VERSION ""

NS_ :

BS_:

BU_: SGW RFHM MPAD IPC GNMM EVCU2 ESL ECM DTCM DMSM BSM BCM AGSM ADCAM

BO_ 2654339197 PDC_INFO_FD_IDCM: 32 EVCU2
 SG_ EOL_FD11_IDCM : 7|1@0+ (1,0) [0|1] "-"  SGW
 SG_ WakeupSource_FD11_IDCM : 95|8@0+ (1,0) [0|255] "" SGW
 SG_ StayActiveSource_FD11_IDCM : 111|64@0+ (1,0) [0|0] "" SGW
 SG_ PreviousCanNMState_FD11_IDCM : 103|4@0+ (1,0) [0|15] "" SGW
 SG_ GenericFailSts_FD11_IDCM : 180|1@0+ (1,0) [0|1] "" SGW
 SG_ DES_FD11_IDCM : 183|2@0+ (1,0) [0|3] "" SGW
 SG_ CurrentFailSts_FD11_IDCM : 181|1@0+ (1,0) [0|1] "" SGW
 SG_ CurrentCanNMState_FD11_IDCM : 99|4@0+ (1,0) [0|15] "" SGW
 SG_ WakeupSource_FD05_IDCM : 23|8@0+ (1,0) [0|255] "" SGW
 SG_ StayActiveSource_FD05_IDCM : 31|64@0+ (1,0) [0|0] "" SGW
 SG_ PreviousCanNMState_FD05_IDCM : 11|4@0+ (1,0) [0|15] "" SGW
 SG_ GenericFailSts_FD05_IDCM : 5|1@0+ (1,0) [0|1] "" SGW,BCM
 SG_ EOL_FD05_IDCM : 2|1@0+ (1,0) [0|1] "-"  SGW,BCM
 SG_ DES_FD05_IDCM : 4|2@0+ (1,0) [0|3] "" SGW
 SG_ CurrentFailSts_FD05_IDCM : 6|1@0+ (1,0) [0|1] "" SGW,BCM
 SG_ CurrentCanNMState_FD05_IDCM : 15|4@0+ (1,0) [0|15] "" SGW

BO_ 1585 TBM_FD_2: 32 SGW
 SG_ WiFi_Client_Mode_Confirm : 13|2@0+ (1,0) [0|3] "-"  MPAD

BO_ 2654339137 PDC_INFO_FD_RFHM: 32 RFHM
 SG_ GenericFailSts_FD03_RFHM : 5|1@0+ (1,0) [0|1] "" SGW,BCM
 SG_ EOL_FD03_RFHM : 7|1@0+ (1,0) [0|1] "-"  SGW,BCM
 SG_ CurrentFailSts_FD03_RFHM : 6|1@0+ (1,0) [0|1] "" SGW,BCM
 SG_ WakeupSource_FD03_RFHM : 23|8@0+ (1,0) [0|255] "" SGW
 SG_ PreviousCanNMState_FD03_RFHM : 11|4@0+ (1,0) [0|15] "" SGW
 SG_ DES_FD03_RFHM : 4|2@0+ (1,0) [0|3] "" SGW
 SG_ CurrentCanNMState_FD03_RFHM : 15|4@0+ (1,0) [0|15] "" SGW
 SG_ WakeupSource_FD09_RFHM : 111|8@0+ (1,0) [0|255] "" SGW
 SG_ PreviousCanNMState_FD09_RFHM : 99|4@0+ (1,0) [0|15] "" SGW
 SG_ GenericFailSts_FD09_RFHM : 93|1@0+ (1,0) [0|1] "" SGW
 SG_ EOL_FD09_RFHM : 95|1@0+ (1,0) [0|1] "-"  SGW
 SG_ DES_FD09_RFHM : 92|2@0+ (1,0) [0|3] "" SGW
 SG_ CurrentFailSts_FD09_RFHM : 94|1@0+ (1,0) [0|1] "" SGW
 SG_ CurrentCanNMState_FD09_RFHM : 103|4@0+ (1,0) [0|15] "" SGW
 SG_ StayActiveSource_FD09_RFHM : 119|64@0+ (1,0) [0|18446744073709551615] "" SGW
 SG_ StayActiveSource_FD03_RFHM : 31|64@0+ (1,0) [0|18446744073709551615] "" SGW

BO_ 2564487440 DIAGNOSTIC_RESPONSE_FOTA_ECM_KWP: 8 ECM
 SG_ N_PDU : 7|64@0+ (1,0) [0|0] "" SGW

BO_ 2564554489 DIAGNOSTIC_REQUEST_FUNC_FOTA_KWP: 8 SGW
 SG_ N_PDU : 7|64@0+ (1,0) [0|0] "" Vector__XXX

BO_ 2564428025 DIAGNOSTIC_REQUEST_FOTA_ECM_KWP: 8 SGW
 SG_ N_PDU : 7|64@0+ (1,0) [0|0] "" Vector__XXX

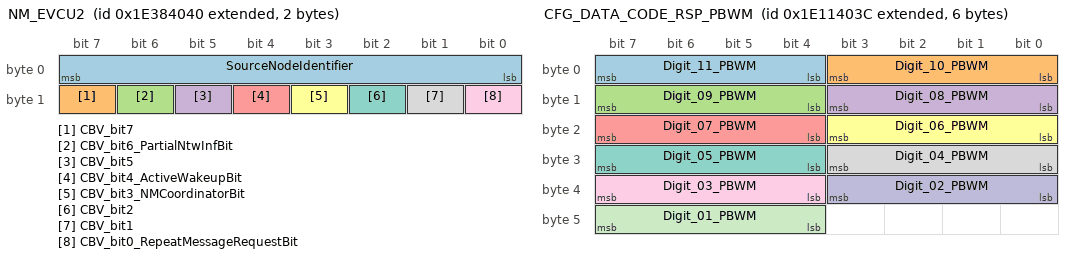
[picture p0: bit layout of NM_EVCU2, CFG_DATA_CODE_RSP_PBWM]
BO_ 2654486592 NM_EVCU2: 2 EVCU2
 SG_ SourceNodeIdentifier : 7|8@0+ (1,0) [0|255] "-"  ADCAM,MPAD,GNMM,SGW,AGSM,ESL,BCM,BSM,IPC,RFHM,ECM,DTCM
 SG_ CBV_bit7 : 15|1@0+ (1,0) [0|1] "" ADCAM,MPAD,GNMM,SGW,AGSM,ESL,BCM,BSM,IPC,RFHM,ECM,DTCM
 SG_ CBV_bit6_PartialNtwInfBit : 14|1@0+ (1,0) [0|1] "" ADCAM,MPAD,GNMM,SGW,AGSM,ESL,BCM,BSM,IPC,RFHM,ECM,DTCM
 SG_ CBV_bit5 : 13|1@0+ (1,0) [0|1] "" ADCAM,MPAD,GNMM,SGW,AGSM,ESL,BCM,BSM,IPC,RFHM,ECM,DTCM
 SG_ CBV_bit4_ActiveWakeupBit : 12|1@0+ (1,0) [0|1] "" ADCAM,MPAD,GNMM,SGW,AGSM,ESL,BCM,BSM,IPC,RFHM,ECM,DTCM
 SG_ CBV_bit3_NMCoordinatorBit : 11|1@0+ (1,0) [0|1] "" ADCAM,MPAD,GNMM,SGW,AGSM,ESL,BCM,BSM,IPC,RFHM,ECM,DTCM
 SG_ CBV_bit2 : 10|1@0+ (1,0) [0|1] "" ADCAM,MPAD,GNMM,SGW,AGSM,ESL,BCM,BSM,IPC,RFHM,ECM,DTCM
 SG_ CBV_bit1 : 9|1@0+ (1,0) [0|1] "" ADCAM,MPAD,GNMM,SGW,AGSM,ESL,BCM,BSM,IPC,RFHM,ECM,DTCM
 SG_ CBV_bit0_RepeatMessageRequestBit : 8|1@0+ (1,0) [0|1] "" ADCAM,MPAD,GNMM,SGW,AGSM,ESL,BCM,BSM,IPC,RFHM,ECM,DTCM

BO_ 1044 HYBRID_DISPLAY2: 64 EVCU2
 SG_ RI_TOTAL_Range_Add : 63|11@0+ (0.1,0) [0|204.70] "km"  SGW
 SG_ RI_SEATSWHL_Range : 20|9@0+ (0.1,0) [0|51.1] "km"  SGW
 SG_ RI_OTHER_Range : 40|9@0+ (0.1,0) [0|51.1] "km"  SGW
 SG_ RI_LIGHTS_Range : 33|9@0+ (0.1,0) [0|51.1] "km"  SGW
 SG_ RI_DEFROST_Range : 13|9@0+ (0.1,0) [0|51.1] "km"  SGW
 SG_ RI_AUDIO_Range : 27|10@0+ (0.1,0) [0|102.3] "km"  SGW
 SG_ RI_AC_FAN_Range : 7|10@0+ (0.1,0) [0|102.30] "km"  SGW
 SG_ PnC_Reattepmt_Failure : 68|1@0+ (1,0) [0|1] "" IPC
 SG_ PnC_Failure : 67|1@0+ (1,0) [0|1] "" SGW,IPC
 SG_ TransTemp_Display : 181|6@0+ (3,-40) [-40|149] "deg C"  SGW,IPC
 SG_ HVBatteryMILRq : 104|1@0+ (1,0) [0|1] "" IPC
 SG_ APCM_Rq_Display : 183|2@0+ (1,0) [0|3] "" SGW

BO_ 616 ADAS_FD_HMI_VIP: 32 ADCAM
 SG_ Set_Speed_MPH_VIP : 15|8@0+ (1,0) [0|255] "mph"  Vector__XXX
 SG_ Set_Speed_KPH_VIP : 7|8@0+ (1,0) [0|255] "kph"  Vector__XXX
 SG_ RRCC_LEDSts_VIP : 25|2@0+ (1,0) [0|3] "No_Unit"  MPAD
 SG_ MessageCounter_ADAS_FD_HMI_VIP : 179|4@0+ (1,0) [0|15] "No_Unit"  MPAD
 SG_ CRC_ADAS_FD_HMI_VIP : 191|8@0+ (1,0) [0|255] "No_Unit"  MPAD

BO_ 1488 TBM_COOP_CHARGING: 64 SGW
 SG_ TBM_StopCharge : 7|1@0+ (1,0) [0|1] "" EVCU2
 SG_ TBM_Cooperative_Charge_Command : 3|2@0+ (1,0) [0|3] "" EVCU2
 SG_ Remote_Chargeport_Command : 6|2@0+ (1,0) [0|3] "" EVCU2
 SG_ Cooperative_Vehicle_Location : 4|1@0+ (1,0) [0|1] "" EVCU2

BO_ 1487 HCP_CHARGING_STAT: 64 EVCU2
 SG_ Total_Battery_Capacity : 5|12@0+ (0.1,0) [0|409.5] "kWh"  SGW
 SG_ Lv2_EstChargeTime_80 : 79|13@0+ (1,0) [0|8191] "Min"  SGW
 SG_ Lv1_EstChargeTime_80 : 63|13@0+ (1,0) [0|8191] "Min"  SGW
 SG_ EVSE_Power : 37|9@0+ (0.1,0) [0|51.1] "kW"  SGW
 SG_ EV_Charge_Current : 44|11@0+ (0.1,0) [0|204.70] "Amp"  SGW
 SG_ Est_Range_FullCharge : 16|11@0+ (1,0) [0|2047] "km"  SGW
 SG_ Energy_to_Battery : 9|9@0+ (0.1,0) [0|51.1] "kW"  SGW
 SG_ Cooperative_Status : 66|3@0+ (1,0) [0|7] "" SGW
 SG_ Chargeport_Lock_Status : 7|2@0+ (1,0) [0|3] "" SGW

BO_ 2654339132 PDC_INFO_FD_PBWM: 32 EVCU2
 SG_ WakeupSource_FD11_PBWM : 23|8@0+ (1,0) [0|255] "" Vector__XXX
 SG_ WakeupSource_FD05_PBWM : 175|8@0+ (1,0) [0|255] "" Vector__XXX
 SG_ StayActiveSource_FD11_PBWM : 31|64@0+ (1,0) [0|0] "" Vector__XXX
 SG_ StayActiveSource_FD05_PBWM : 99|64@0+ (1,0) [0|0] "" Vector__XXX
 SG_ PreviousCanNMState_FD11_PBWM : 11|4@0+ (1,0) [0|15] "" Vector__XXX
 SG_ PreviousCanNMState_FD05_PBWM : 103|4@0+ (1,0) [0|15] "" Vector__XXX
 SG_ GenericFailSts_FD11_PBWM : 5|1@0+ (1,0) [0|1] "" BCM
 SG_ GenericFailSts_FD05_PBWM : 89|1@0+ (1,0) [0|1] "" Vector__XXX
 SG_ EOL_FD11_PBWM : 7|1@0+ (1,0) [0|1] "-"  BCM
 SG_ EOL_FD05_PBWM : 1|1@0+ (1,0) [0|1] "-"  Vector__XXX
 SG_ DES_FD11_PBWM : 4|2@0+ (1,0) [0|3] "" Vector__XXX
 SG_ DES_FD05_PBWM : 91|2@0+ (1,0) [0|3] "" Vector__XXX
 SG_ CurrentFailSts_FD11_PBWM : 2|1@0+ (1,0) [0|1] "" BCM
 SG_ CurrentFailSts_FD05_PBWM : 6|1@0+ (1,0) [0|1] "" Vector__XXX
 SG_ CurrentCanNMState_FD11_PBWM : 15|4@0+ (1,0) [0|15] "" Vector__XXX
 SG_ CurrentCanNMState_FD05_PBWM : 95|4@0+ (1,0) [0|15] "" Vector__XXX

BO_ 2654339138 PDC_INFO_FD_DMPI: 32 EVCU2
 SG_ WakeupSource_FD11_DMPI : 23|8@0+ (1,0) [0|255] "" Vector__XXX
 SG_ WakeupSource_FD05_DMPI : 175|8@0+ (1,0) [0|255] "" Vector__XXX
 SG_ StayActiveSource_FD11_DMPI : 31|64@0+ (1,0) [0|0] "" Vector__XXX
 SG_ StayActiveSource_FD05_DMPI : 99|64@0+ (1,0) [0|0] "" Vector__XXX
 SG_ PreviousCanNMState_FD11_DMPI : 11|4@0+ (1,0) [0|15] "" Vector__XXX
 SG_ PreviousCanNMState_FD05_DMPI : 103|4@0+ (1,0) [0|15] "" Vector__XXX
 SG_ GenericFailSts_FD11_DMPI : 5|1@0+ (1,0) [0|1] "" BCM
 SG_ GenericFailSts_FD05_DMPI : 89|1@0+ (1,0) [0|1] "" Vector__XXX
 SG_ EOL_FD11_DMPI : 7|1@0+ (1,0) [0|1] "-"  BCM
 SG_ EOL_FD05_DMPI : 1|1@0+ (1,0) [0|1] "-"  Vector__XXX
 SG_ DES_FD11_DMPI : 4|2@0+ (1,0) [0|3] "" Vector__XXX
 SG_ DES_FD05_DMPI : 91|2@0+ (1,0) [0|3] "" Vector__XXX
 SG_ CurrentFailSts_FD11_DMPI : 2|1@0+ (1,0) [0|1] "" BCM
 SG_ CurrentFailSts_FD05_DMPI : 6|1@0+ (1,0) [0|1] "" Vector__XXX
 SG_ CurrentCanNMState_FD11_DMPI : 15|4@0+ (1,0) [0|15] "" Vector__XXX
 SG_ CurrentCanNMState_FD05_DMPI : 95|4@0+ (1,0) [0|15] "" Vector__XXX

BO_ 2564486631 DIAGNOSTIC_RESPONSE_FOTA_MPFC: 64 MPAD
 SG_ N_PDU : 7|64@0+ (1,0) [0|0] "" SGW

BO_ 2564483061 DIAGNOSTIC_REQUEST_FOTA_MPFC: 64 SGW
 SG_ N_PDU : 7|64@0+ (1,0) [0|0] "-"  MPAD

BO_ 2651930684 CFG_DATA_CODE_RSP_PBWM: 6 EVCU2
 SG_ Digit_11_PBWM : 7|4@0+ (1,0) [0|15] "-"  BCM
 SG_ Digit_10_PBWM : 3|4@0+ (1,0) [0|15] "-"  BCM
 SG_ Digit_09_PBWM : 15|4@0+ (1,0) [0|15] "-"  BCM
 SG_ Digit_08_PBWM : 11|4@0+ (1,0) [0|15] "-"  BCM
 SG_ Digit_07_PBWM : 23|4@0+ (1,0) [0|15] "-"  BCM
 SG_ Digit_06_PBWM : 19|4@0+ (1,0) [0|15] "-"  BCM
 SG_ Digit_05_PBWM : 31|4@0+ (1,0) [0|15] "-"  BCM
 SG_ Digit_04_PBWM : 27|4@0+ (1,0) [0|15] "-"  BCM
 SG_ Digit_03_PBWM : 39|4@0+ (1,0) [0|15] "-"  BCM
 SG_ Digit_02_PBWM : 35|4@0+ (1,0) [0|15] "-"  BCM
 SG_ Digit_01_PBWM : 47|4@0+ (1,0) [0|15] "-"  BCM

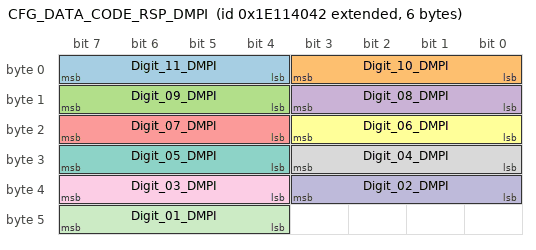
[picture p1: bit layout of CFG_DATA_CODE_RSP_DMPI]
BO_ 2651930690 CFG_DATA_CODE_RSP_DMPI: 6 EVCU2
 SG_ Digit_11_DMPI : 7|4@0+ (1,0) [0|15] "-"  BCM
 SG_ Digit_10_DMPI : 3|4@0+ (1,0) [0|15] "-"  BCM
 SG_ Digit_09_DMPI : 15|4@0+ (1,0) [0|15] "-"  BCM
 SG_ Digit_08_DMPI : 11|4@0+ (1,0) [0|15] "-"  BCM
 SG_ Digit_07_DMPI : 23|4@0+ (1,0) [0|15] "-"  BCM
 SG_ Digit_06_DMPI : 19|4@0+ (1,0) [0|15] "-"  BCM
 SG_ Digit_05_DMPI : 31|4@0+ (1,0) [0|15] "-"  BCM
 SG_ Digit_04_DMPI : 27|4@0+ (1,0) [0|15] "-"  BCM
 SG_ Digit_03_DMPI : 39|4@0+ (1,0) [0|15] "-"  BCM
 SG_ Digit_02_DMPI : 35|4@0+ (1,0) [0|15] "-"  BCM
 SG_ Digit_01_DMPI : 47|4@0+ (1,0) [0|15] "-"  BCM

BO_ 2564682304 DIAGNOSTIC_ROE_FD_BCM: 64 BCM
 SG_ N_PDU : 7|64@0+ (1,0) [0|0] "" SGW

BO_ 2564682048 DIAGNOSTIC_ROE_BCM: 8 BCM
 SG_ N_PDU : 7|64@0+ (1,0) [0|0] "" SGW

BO_ 577 SYNCHRO_DC_GLOBAL: 32 ECM
 SG_ QualifyDriveCycle : 7|1@0+ (1,0) [0|1] "" EVCU2

BO_ 1914 FOTA_RSP_MPFC: 32 MPAD
 SG_ Download_Status_MPFC : 12|2@0+ (1,0) [0|3] "" SGW
 SG_ Big_ECU_Ready_MPFC : 14|2@0+ (1,0) [0|3] "" SGW
 SG_ Update_Status_MPFC : 5|2@0+ (1,0) [0|3] "" SGW

CM_ SG_ 2654339197 CurrentFailSts_FD05_IDCM "Indicates the presence/absence of at least one DTC with DTCStatus = present in the System Memory";
CM_ SG_ 2654339197 CurrentCanNMState_FD11_IDCM "Indicates that CanNM state the ECU is currently executing";
CM_ SG_ 2654339197 CurrentCanNMState_FD05_IDCM "Indicates that CanNM state the ECU is currently executing";
CM_ SG_ 2654339197 DES_FD05_IDCM "Indicates whether the ECU?s CAN cell is in either ErrorActive, or ErrorPassive state OR has just now recovered from a BusOff condition";
CM_ SG_ 2654339197 DES_FD11_IDCM "Indicates whether the ECU?s CAN cell is in either ErrorActive, or ErrorPassive state OR has just now recovered from a BusOff condition";
CM_ SG_ 2654339197 EOL_FD05_IDCM "Indicates if the ECU requires configuration data at the assembly plant End Of Line";
CM_ SG_ 2654339197 EOL_FD11_IDCM "Indicates if the ECU requires configuration data at the assembly plant End Of Line";
CM_ SG_ 2654339197 GenericFailSts_FD05_IDCM "Indicates the presence/absent of at least one DTC in the System Memory";
CM_ SG_ 2654339197 GenericFailSts_FD11_IDCM "Indicates the presence/absent of at least one DTC in the System Memory";
CM_ SG_ 2654339197 PreviousCanNMState_FD05_IDCM "Indicates the last CanNM state that the ECU existed in";
CM_ SG_ 2654339197 PreviousCanNMState_FD11_IDCM "Indicates the last CanNM state that the ECU existed in";
CM_ SG_ 2654339197 StayActiveSource_FD05_IDCM "Indicates the source that requests the ECU to stay active";
CM_ SG_ 2654339197 StayActiveSource_FD11_IDCM "Indicates the source that requests the ECU to stay active";
CM_ SG_ 2654339197 WakeupSource_FD05_IDCM "Indicates the reason the ECU was most recently awakened";
CM_ SG_ 2654339197 WakeupSource_FD11_IDCM "Indicates the reason the ECU was most recently awakened";
CM_ SG_ 2654339197 CurrentFailSts_FD11_IDCM "Indicates the presence/absence of at least one DTC with DTCStatus = present in the System Memory";
CM_ SG_ 1585 WiFi_Client_Mode_Confirm "WiFI Client Mode Confirmation";
CM_ SG_ 2654339137 DES_FD09_RFHM "Indicates whether the ECU?s CAN cell is in either ErrorActive, or ErrorPassive state OR has just now recovered from a BusOff condition";
CM_ SG_ 2654339137 CurrentCanNMState_FD03_RFHM "Indicates that CanNM state the ECU is currently executing";
CM_ SG_ 2654339137 CurrentCanNMState_FD09_RFHM "Indicates that CanNM state the ECU is currently executing";
CM_ SG_ 2654339137 CurrentFailSts_FD03_RFHM "Indicates the presence/absence of at least one DTC with DTCStatus = present in the System Memory";
CM_ SG_ 2654339137 CurrentFailSts_FD09_RFHM "Indicates the presence/absence of at least one DTC with DTCStatus = present in the System Memory";
CM_ SG_ 2654339137 DES_FD03_RFHM "Indicates whether the ECU?s CAN cell is in either ErrorActive, or ErrorPassive state OR has just now recovered from a BusOff condition";
CM_ SG_ 2654339137 EOL_FD03_RFHM "Indicates if the ECU requires configuration data at the assembly plant End Of Line";
CM_ SG_ 2654339137 EOL_FD09_RFHM "Indicates if the ECU requires configuration data at the assembly plant End Of Line";
CM_ SG_ 2654339137 GenericFailSts_FD03_RFHM "Indicates the presence/absent of at least one DTC in the System Memory";
CM_ SG_ 2654339137 GenericFailSts_FD09_RFHM "Indicates the presence/absent of at least one DTC in the System Memory";
CM_ SG_ 2654339137 PreviousCanNMState_FD03_RFHM "Indicates the last CanNM state that the ECU existed in";
CM_ SG_ 2654339137 PreviousCanNMState_FD09_RFHM "Indicates the last CanNM state that the ECU existed in";
CM_ SG_ 2654339137 StayActiveSource_FD03_RFHM "Indicates the source that requests the ECU to stay active";
CM_ SG_ 2654339137 StayActiveSource_FD09_RFHM "Indicates the source that requests the ECU to stay active";
CM_ SG_ 2654339137 WakeupSource_FD03_RFHM "Indicates the reason the ECU was most recently awakened";
CM_ SG_ 2654339137 WakeupSource_FD09_RFHM "Indicates the reason the ECU was most recently awakened";
CM_ SG_ 2564487440 N_PDU "This signal is used for diagnostic purposes";
CM_ SG_ 2564554489 N_PDU "This signal is used for diagnostic purposes";
CM_ SG_ 2564428025 N_PDU "This signal is used for diagnostic purposes";
CM_ SG_ 1044 TransTemp_Display "Transmission Temp For Display";
CM_ SG_ 1044 RI_TOTAL_Range_Add "Total Range Impact of Turning All Non-Propulsive Power Consuming Features Off";
CM_ SG_ 1044 RI_SEATSWHL_Range "Range Impact of Turning Seats and Wheel Heating/Venting Off";
CM_ SG_ 1044 RI_OTHER_Range "Range Impact of Turning Other Non-Propulsive Power Consuming Features Off";
CM_ SG_ 1044 RI_LIGHTS_Range "Range Impact of Turning External Lights Off";
CM_ SG_ 1044 RI_DEFROST_Range "Range Impact of Turning Defrost Off";
CM_ SG_ 1044 RI_AUDIO_Range "Range Impact of Turning Audio Off";
CM_ SG_ 1044 RI_AC_FAN_Range "Range Impact of Turning AC Off";
CM_ SG_ 1044 PnC_Reattepmt_Failure "The maximum number of authentication retry attempts has been reached";
CM_ SG_ 1044 PnC_Failure "A Plug and Charge failure has been detected";
CM_ SG_ 1044 HVBatteryMILRq "HV Battery MIL Request";
CM_ SG_ 1044 APCM_Rq_Display "Auto position correction mode request";
CM_ SG_ 616 CRC_ADAS_FD_HMI_VIP "CRC according to SAE J1850 standard at each frame transmission.";
CM_ SG_ 616 MessageCounter_ADAS_FD_HMI_VIP "This signal is a counter used for safety checks strategies. This counter is incremented of 1 (one) unit at each frame transmission.";
CM_ SG_ 616 RRCC_LEDSts_VIP "RRCC_LEDSts";
CM_ SG_ 616 Set_Speed_KPH_VIP "Speed shown by IPC, which ACC is controlling in KPH";
CM_ SG_ 616 Set_Speed_MPH_VIP "Speed shown by IPC, which ACC is controlling in MPH";
CM_ SG_ 1488 Cooperative_Vehicle_Location "Vehicle at Cooperative enabled location.";
CM_ SG_ 1488 Remote_Chargeport_Command "Remote Charge port lock/unlock command";
CM_ SG_ 1488 TBM_Cooperative_Charge_Command "Remote cooperative charging command";
CM_ SG_ 1488 TBM_StopCharge "Remote Stop HV Charging Command";
CM_ SG_ 1487 EV_Charge_Current "HV Charging Current Draw from EVSE";
CM_ SG_ 1487 Est_Range_FullCharge "Estimated Range at 100% SOC";
CM_ SG_ 1487 Total_Battery_Capacity "Total Battery capacity in kWh";
CM_ SG_ 1487 Lv2_EstChargeTime_80 "Estimated time to charge to 80% on Level 2";
CM_ SG_ 1487 Lv1_EstChargeTime_80 "Estimated time to charge to 80% on Level 1";
CM_ SG_ 1487 Chargeport_Lock_Status "Charge Port Lock Status";
CM_ SG_ 1487 Cooperative_Status "Cooperative charging status";
CM_ SG_ 1487 Energy_to_Battery "HV Battery Charging Energy Rate";
CM_ SG_ 1487 EVSE_Power "EVSE Power available";
CM_ SG_ 2654339132 GenericFailSts_FD11_PBWM "Indicates the presence/absent of at least one DTC in the System Memory";
CM_ SG_ 2654339132 CurrentCanNMState_FD05_PBWM "Indicates that CanNM state the ECU is currently executing";
CM_ SG_ 2654339132 CurrentCanNMState_FD11_PBWM "Indicates that CanNM state the ECU is currently executing";
CM_ SG_ 2654339132 CurrentFailSts_FD05_PBWM "Indicates the presence/absence of at least one DTC with DTCStatus = present in the System Memory";
CM_ SG_ 2654339132 CurrentFailSts_FD11_PBWM "Indicates the presence/absence of at least one DTC with DTCStatus = present in the System Memory";
CM_ SG_ 2654339132 DES_FD05_PBWM "Indicates whether the ECU?s CAN cell is in either ErrorActive, or ErrorPassive state OR has just now recovered from a BusOff condition";
CM_ SG_ 2654339132 DES_FD11_PBWM "Indicates whether the ECU?s CAN cell is in either ErrorActive, or ErrorPassive state OR has just now recovered from a BusOff condition";
CM_ SG_ 2654339132 EOL_FD05_PBWM "Indicates if the ECU requires configuration data at the assembly plant End Of Line";
CM_ SG_ 2654339132 EOL_FD11_PBWM "Indicates if the ECU requires configuration data at the assembly plant End Of Line";
CM_ SG_ 2654339132 GenericFailSts_FD05_PBWM "Indicates the presence/absent of at least one DTC in the System Memory";
CM_ SG_ 2654339132 PreviousCanNMState_FD05_PBWM "Indicates the last CanNM state that the ECU existed in";
CM_ SG_ 2654339132 PreviousCanNMState_FD11_PBWM "Indicates the last CanNM state that the ECU existed in";
CM_ SG_ 2654339132 StayActiveSource_FD05_PBWM "Indicates the source that requests the ECU to stay active";
CM_ SG_ 2654339132 StayActiveSource_FD11_PBWM "Indicates the source that requests the ECU to stay active";
CM_ SG_ 2654339132 WakeupSource_FD05_PBWM "Indicates the reason the ECU was most recently awakened";
CM_ SG_ 2654339132 WakeupSource_FD11_PBWM "Indicates the reason the ECU was most recently awakened";
CM_ SG_ 2654339138 CurrentCanNMState_FD05_DMPI "Indicates that CanNM state the ECU is currently executing";
CM_ SG_ 2654339138 CurrentCanNMState_FD11_DMPI "Indicates that CanNM state the ECU is currently executing";
CM_ SG_ 2654339138 CurrentFailSts_FD05_DMPI "Indicates the presence/absence of at least one DTC with DTCStatus = present in the System Memory";
CM_ SG_ 2654339138 CurrentFailSts_FD11_DMPI "Indicates the presence/absence of at least one DTC with DTCStatus = present in the System Memory";
CM_ SG_ 2654339138 DES_FD05_DMPI "Indicates whether the ECU?s CAN cell is in either ErrorActive, or ErrorPassive state OR has just now recovered from a BusOff condition";
CM_ SG_ 2654339138 DES_FD11_DMPI "Indicates whether the ECU?s CAN cell is in either ErrorActive, or ErrorPassive state OR has just now recovered from a BusOff condition";
CM_ SG_ 2654339138 EOL_FD05_DMPI "Indicates if the ECU requires configuration data at the assembly plant End Of Line";
CM_ SG_ 2654339138 EOL_FD11_DMPI "Indicates if the ECU requires configuration data at the assembly plant End Of Line";
CM_ SG_ 2654339138 GenericFailSts_FD05_DMPI "Indicates the presence/absent of at least one DTC in the System Memory";
CM_ SG_ 2654339138 GenericFailSts_FD11_DMPI "Indicates the presence/absent of at least one DTC in the System Memory";
CM_ SG_ 2654339138 PreviousCanNMState_FD05_DMPI "Indicates the last CanNM state that the ECU existed in";
CM_ SG_ 2654339138 PreviousCanNMState_FD11_DMPI "Indicates the last CanNM state that the ECU existed in";
CM_ SG_ 2654339138 StayActiveSource_FD05_DMPI "Indicates the source that requests the ECU to stay active";
CM_ SG_ 2654339138 StayActiveSource_FD11_DMPI "Indicates the source that requests the ECU to stay active";
CM_ SG_ 2654339138 WakeupSource_FD05_DMPI "Indicates the reason the ECU was most recently awakened";
CM_ SG_ 2654339138 WakeupSource_FD11_DMPI "Indicates the reason the ECU was most recently awakened";
CM_ SG_ 2564486631 N_PDU "This signal is used for diagnostic purposes";
CM_ SG_ 2564483061 N_PDU "This signal is used for diagnostic purposes";
CM_ SG_ 2564682304 N_PDU "This signal is used for diagnostic purposes";
CM_ SG_ 2564682048 N_PDU "This signal is used for diagnostic purposes";
CM_ SG_ 577 QualifyDriveCycle "Qualified Drive Cycle";
CM_ SG_ 1914 Big_ECU_Ready_MPFC "MPFC Ready Status";
CM_ SG_ 1914 Download_Status_MPFC "MPFC Download Status";
CM_ SG_ 1914 Update_Status_MPFC "MPFC Update Status";
BA_DEF_ BO_ "CANFD_BRS" ENUM "0","1";
BA_DEF_ BO_ "VFrameFormat" ENUM "StandardCAN","ExtendedCAN","reserved","reserved","reserved","reserved","reserved","reserved","reserved","reserved","reserved","reserved","reserved","reserved","StandardCAN_FD","ExtendedCAN_FD";
BA_DEF_ BO_ "DiagConnection" HEX 0 65535;
BA_DEF_ BO_ "DiagState" ENUM "No","Yes";
BA_DEF_ BO_ "NmAsrMessage" ENUM "No","Yes";
BA_DEF_ BO_ "GenMsgDelayTime" INT 0 65535;
BA_DEF_ BO_ "GenMsgCycleTime" INT 0 65535;
BA_DEF_ BO_ "GenMsgCycleTimeFast" INT 0 65535;
BA_DEF_ BO_ "GenMsgStartDelayTime" INT 0 65535;
BA_DEF_ BO_ "GenMsgILSupport" ENUM "No","Yes";
BA_DEF_ BO_ "GenMsgNrOfRepetition" INT 0 255;
BA_DEF_ BO_ "GenMsgSendType" ENUM "Cyclic","NotUsed","NotUsed","NotUsed","NotUsed","NotUsed","NotUsed","NotUsed","NoMsgSendType";
BA_DEF_ BO_ "NmMessage" ENUM "No","Yes";
BA_DEF_ BO_ "DiagResponse" ENUM "No","Yes";
BA_DEF_ BO_ "Type" ENUM "P","C","PE","COC","PE_Cntrl","E","E_Cntrl","OC","S","BAF","DC","EM","MM","ISO-TP","-";
BA_DEF_ BO_ "DiagRequest" ENUM "No","Yes";
BA_DEF_ SG_ "GenSigTimeoutTime_SGW" INT 0 65535;
BA_DEF_ SG_ "GenSigTimeoutTime_RFHM" INT 0 65535;
BA_DEF_ SG_ "GenSigTimeoutTime_MPAD" INT 0 65535;
BA_DEF_ SG_ "GenSigTimeoutTime_IPC" INT 0 65535;
BA_DEF_ SG_ "GenSigTimeoutTime_GNMM" INT 0 65535;
BA_DEF_ SG_ "GenSigTimeoutTime_EVCU2" INT 0 65535;
BA_DEF_ SG_ "GenSigTimeoutTime_ESL" INT 0 65535;
BA_DEF_ SG_ "GenSigTimeoutTime_ECM" INT 0 65535;
BA_DEF_ SG_ "GenSigTimeoutTime_DTCM" INT 0 65535;
BA_DEF_ SG_ "GenSigTimeoutTime_DMSM" INT 0 65535;
BA_DEF_ SG_ "GenSigTimeoutTime_BSM" INT 0 65535;
BA_DEF_ SG_ "GenSigTimeoutTime_BCM" INT 0 65535;
BA_DEF_ SG_ "GenSigTimeoutTime_AGSM" INT 0 65535;
BA_DEF_ SG_ "GenSigTimeoutTime_ADCAM" INT 0 65535;
BA_DEF_ SG_ "SystemSignalLongSymbol" STRING ;
BA_DEF_ SG_ "GenSigSendType" ENUM "NotUsed","OnWrite","OnWriteWithRepetition","OnChange","OnChangeWithRepetition","IfActive","IfActiveWithRepetition","NoSigSendType";
BA_DEF_ SG_ "GenSigInactiveValue" INT 0 2147483647;
BA_DEF_ SG_ "GenSigStartValue" INT 0 2147483647;
BA_DEF_DEF_ "CANFD_BRS" "0";
BA_DEF_DEF_ "VFrameFormat" "StandardCAN_FD";
BA_DEF_DEF_ "DiagConnection" 0;
BA_DEF_DEF_ "DiagState" "No";
BA_DEF_DEF_ "NmAsrMessage" "No";
BA_DEF_DEF_ "GenMsgDelayTime" 0;
BA_DEF_DEF_ "GenMsgCycleTime" 0;
BA_DEF_DEF_ "GenMsgCycleTimeFast" 0;
BA_DEF_DEF_ "GenMsgStartDelayTime" 0;
BA_DEF_DEF_ "GenMsgILSupport" "No";
BA_DEF_DEF_ "GenMsgNrOfRepetition" 0;
BA_DEF_DEF_ "GenMsgSendType" "NoMsgSendType";
BA_DEF_DEF_ "NmMessage" "No";
BA_DEF_DEF_ "DiagResponse" "No";
BA_DEF_DEF_ "Type" "-";
BA_DEF_DEF_ "DiagRequest" "No";
BA_DEF_DEF_ "GenSigTimeoutTime_SGW" 2500;
BA_DEF_DEF_ "GenSigTimeoutTime_RFHM" 2500;
BA_DEF_DEF_ "GenSigTimeoutTime_MPAD" 2500;
BA_DEF_DEF_ "GenSigTimeoutTime_IPC" 2500;
BA_DEF_DEF_ "GenSigTimeoutTime_GNMM" 2500;
BA_DEF_DEF_ "GenSigTimeoutTime_EVCU2" 2500;
BA_DEF_DEF_ "GenSigTimeoutTime_ESL" 2500;
BA_DEF_DEF_ "GenSigTimeoutTime_ECM" 2500;
BA_DEF_DEF_ "GenSigTimeoutTime_DTCM" 2500;
BA_DEF_DEF_ "GenSigTimeoutTime_DMSM" 2500;
BA_DEF_DEF_ "GenSigTimeoutTime_BSM" 2500;
BA_DEF_DEF_ "GenSigTimeoutTime_BCM" 2500;
BA_DEF_DEF_ "GenSigTimeoutTime_AGSM" 2500;
BA_DEF_DEF_ "GenSigTimeoutTime_ADCAM" 2500;
BA_DEF_DEF_ "SystemSignalLongSymbol" "";
BA_DEF_DEF_ "GenSigSendType" "NoSigSendType";
BA_DEF_DEF_ "GenSigInactiveValue" 0;
BA_DEF_DEF_ "GenSigStartValue" 0;
BA_ "GenMsgCycleTime" BO_ 2654339197 1000;
BA_ "GenMsgILSupport" BO_ 2654339197 1;
BA_ "CANFD_BRS" BO_ 2654339197 1;
BA_ "VFrameFormat" BO_ 2654339197 15;
BA_ "GenMsgSendType" BO_ 2654339197 0;
BA_ "Type" BO_ 2654339197 1;
BA_ "CANFD_BRS" BO_ 1585 1;
BA_ "GenMsgCycleTime" BO_ 1585 500;
BA_ "GenMsgILSupport" BO_ 1585 1;
BA_ "GenMsgSendType" BO_ 1585 0;
BA_ "Type" BO_ 1585 1;
BA_ "CANFD_BRS" BO_ 2654339137 1;
BA_ "VFrameFormat" BO_ 2654339137 15;
BA_ "GenMsgCycleTime" BO_ 2654339137 1000;
BA_ "GenMsgILSupport" BO_ 2654339137 1;
BA_ "GenMsgSendType" BO_ 2654339137 0;
BA_ "Type" BO_ 2654339137 1;
BA_ "VFrameFormat" BO_ 2564487440 1;
BA_ "DiagConnection" BO_ 2564487440 63760;
BA_ "DiagResponse" BO_ 2564487440 1;
BA_ "Type" BO_ 2564487440 8;
BA_ "VFrameFormat" BO_ 2564554489 1;
BA_ "DiagConnection" BO_ 2564554489 63998;
BA_ "DiagState" BO_ 2564554489 1;
BA_ "Type" BO_ 2564554489 8;
BA_ "VFrameFormat" BO_ 2564428025 1;
BA_ "DiagConnection" BO_ 2564428025 63760;
BA_ "Type" BO_ 2564428025 8;
BA_ "DiagRequest" BO_ 2564428025 1;
BA_ "CANFD_BRS" BO_ 2654486592 1;
BA_ "VFrameFormat" BO_ 2654486592 15;
BA_ "NmAsrMessage" BO_ 2654486592 1;
BA_ "NmMessage" BO_ 2654486592 1;
BA_ "Type" BO_ 2654486592 8;
BA_ "CANFD_BRS" BO_ 1044 1;
BA_ "GenMsgDelayTime" BO_ 1044 20;
BA_ "GenMsgCycleTime" BO_ 1044 100;
BA_ "GenMsgILSupport" BO_ 1044 1;
BA_ "GenMsgSendType" BO_ 1044 0;
BA_ "Type" BO_ 1044 1;
BA_ "CANFD_BRS" BO_ 616 1;
BA_ "GenMsgDelayTime" BO_ 616 20;
BA_ "GenMsgCycleTime" BO_ 616 100;
BA_ "GenMsgILSupport" BO_ 616 1;
BA_ "GenMsgSendType" BO_ 616 0;
BA_ "Type" BO_ 616 3;
BA_ "CANFD_BRS" BO_ 1488 1;
BA_ "GenMsgDelayTime" BO_ 1488 20;
BA_ "GenMsgCycleTime" BO_ 1488 1000;
BA_ "GenMsgILSupport" BO_ 1488 1;
BA_ "GenMsgSendType" BO_ 1488 0;
BA_ "Type" BO_ 1488 1;
BA_ "CANFD_BRS" BO_ 1487 1;
BA_ "GenMsgDelayTime" BO_ 1487 20;
BA_ "GenMsgCycleTime" BO_ 1487 1000;
BA_ "GenMsgILSupport" BO_ 1487 1;
BA_ "GenMsgSendType" BO_ 1487 0;
BA_ "Type" BO_ 1487 1;
BA_ "CANFD_BRS" BO_ 2654339132 1;
BA_ "VFrameFormat" BO_ 2654339132 15;
BA_ "GenMsgCycleTime" BO_ 2654339132 1000;
BA_ "GenMsgILSupport" BO_ 2654339132 1;
BA_ "GenMsgSendType" BO_ 2654339132 0;
BA_ "Type" BO_ 2654339132 1;
BA_ "CANFD_BRS" BO_ 2654339138 1;
BA_ "VFrameFormat" BO_ 2654339138 15;
BA_ "GenMsgCycleTime" BO_ 2654339138 1000;
BA_ "GenMsgILSupport" BO_ 2654339138 1;
BA_ "GenMsgSendType" BO_ 2654339138 0;
BA_ "Type" BO_ 2654339138 1;
BA_ "CANFD_BRS" BO_ 2564486631 1;
BA_ "VFrameFormat" BO_ 2564486631 15;
BA_ "DiagConnection" BO_ 2564486631 62951;
BA_ "DiagResponse" BO_ 2564486631 1;
BA_ "Type" BO_ 2564486631 8;
BA_ "CANFD_BRS" BO_ 2564483061 1;
BA_ "VFrameFormat" BO_ 2564483061 15;
BA_ "DiagConnection" BO_ 2564483061 62951;
BA_ "Type" BO_ 2564483061 8;
BA_ "DiagRequest" BO_ 2564483061 1;
BA_ "CANFD_BRS" BO_ 2651930684 1;
BA_ "VFrameFormat" BO_ 2651930684 15;
BA_ "GenMsgILSupport" BO_ 2651930684 1;
BA_ "Type" BO_ 2651930684 11;
BA_ "CANFD_BRS" BO_ 2651930690 1;
BA_ "VFrameFormat" BO_ 2651930690 15;
BA_ "GenMsgILSupport" BO_ 2651930690 1;
BA_ "Type" BO_ 2651930690 11;
BA_ "CANFD_BRS" BO_ 2564682304 1;
BA_ "VFrameFormat" BO_ 2564682304 15;
BA_ "DiagConnection" BO_ 2564682304 62016;
BA_ "DiagResponse" BO_ 2564682304 1;
BA_ "Type" BO_ 2564682304 8;
BA_ "VFrameFormat" BO_ 2564682048 1;
BA_ "DiagConnection" BO_ 2564682048 61760;
BA_ "DiagResponse" BO_ 2564682048 1;
BA_ "Type" BO_ 2564682048 8;
BA_ "CANFD_BRS" BO_ 577 1;
BA_ "GenMsgDelayTime" BO_ 577 20;
BA_ "GenMsgCycleTime" BO_ 577 1000;
BA_ "GenMsgILSupport" BO_ 577 1;
BA_ "GenMsgSendType" BO_ 577 0;
BA_ "Type" BO_ 577 3;
BA_ "CANFD_BRS" BO_ 1914 1;
BA_ "GenMsgDelayTime" BO_ 1914 20;
BA_ "GenMsgCycleTime" BO_ 1914 1000;
BA_ "GenMsgCycleTimeFast" BO_ 1914 20;
BA_ "GenMsgILSupport" BO_ 1914 1;
BA_ "GenMsgNrOfRepetition" BO_ 1914 2;
BA_ "GenMsgSendType" BO_ 1914 0;
BA_ "Type" BO_ 1914 1;
BA_ "GenSigTimeoutTime_SGW" SG_ 2564682304 N_PDU 0;
BA_ "GenSigTimeoutTime_RFHM" SG_ 2564682304 N_PDU 0;
BA_ "GenSigTimeoutTime_MPAD" SG_ 2564682304 N_PDU 0;
BA_ "GenSigTimeoutTime_IPC" SG_ 2564682304 N_PDU 0;
BA_ "GenSigTimeoutTime_GNMM" SG_ 2564682304 N_PDU 0;
BA_ "GenSigTimeoutTime_EVCU2" SG_ 2564682304 N_PDU 0;
BA_ "GenSigTimeoutTime_ESL" SG_ 2564682304 N_PDU 0;
BA_ "GenSigTimeoutTime_ECM" SG_ 2564682304 N_PDU 0;
BA_ "GenSigTimeoutTime_DTCM" SG_ 2564682304 N_PDU 0;
BA_ "GenSigTimeoutTime_DMSM" SG_ 2564682304 N_PDU 0;
BA_ "GenSigTimeoutTime_BSM" SG_ 2564682304 N_PDU 0;
BA_ "GenSigTimeoutTime_BCM" SG_ 2564682304 N_PDU 0;
BA_ "GenSigTimeoutTime_AGSM" SG_ 2564682304 N_PDU 0;
BA_ "GenSigTimeoutTime_ADCAM" SG_ 2564682304 N_PDU 0;
BA_ "GenSigTimeoutTime_SGW" SG_ 2564682048 N_PDU 0;
BA_ "GenSigTimeoutTime_RFHM" SG_ 2564682048 N_PDU 0;
BA_ "GenSigTimeoutTime_MPAD" SG_ 2564682048 N_PDU 0;
BA_ "GenSigTimeoutTime_IPC" SG_ 2564682048 N_PDU 0;
BA_ "GenSigTimeoutTime_GNMM" SG_ 2564682048 N_PDU 0;
BA_ "GenSigTimeoutTime_EVCU2" SG_ 2564682048 N_PDU 0;
BA_ "GenSigTimeoutTime_ESL" SG_ 2564682048 N_PDU 0;
BA_ "GenSigTimeoutTime_ECM" SG_ 2564682048 N_PDU 0;
BA_ "GenSigTimeoutTime_DTCM" SG_ 2564682048 N_PDU 0;
BA_ "GenSigTimeoutTime_DMSM" SG_ 2564682048 N_PDU 0;
BA_ "GenSigTimeoutTime_BSM" SG_ 2564682048 N_PDU 0;
BA_ "GenSigTimeoutTime_BCM" SG_ 2564682048 N_PDU 0;
BA_ "GenSigTimeoutTime_AGSM" SG_ 2564682048 N_PDU 0;
BA_ "GenSigTimeoutTime_ADCAM" SG_ 2564682048 N_PDU 0;
BA_ "GenSigTimeoutTime_SGW" SG_ 2564486631 N_PDU 0;
BA_ "GenSigTimeoutTime_RFHM" SG_ 2564486631 N_PDU 0;
BA_ "GenSigTimeoutTime_MPAD" SG_ 2564486631 N_PDU 0;
BA_ "GenSigTimeoutTime_IPC" SG_ 2564486631 N_PDU 0;
BA_ "GenSigTimeoutTime_GNMM" SG_ 2564486631 N_PDU 0;
BA_ "GenSigTimeoutTime_EVCU2" SG_ 2564486631 N_PDU 0;
BA_ "GenSigTimeoutTime_ESL" SG_ 2564486631 N_PDU 0;
BA_ "GenSigTimeoutTime_ECM" SG_ 2564486631 N_PDU 0;
BA_ "GenSigTimeoutTime_DTCM" SG_ 2564486631 N_PDU 0;
BA_ "GenSigTimeoutTime_DMSM" SG_ 2564486631 N_PDU 0;
BA_ "GenSigTimeoutTime_BSM" SG_ 2564486631 N_PDU 0;
BA_ "GenSigTimeoutTime_BCM" SG_ 2564486631 N_PDU 0;
BA_ "GenSigTimeoutTime_AGSM" SG_ 2564486631 N_PDU 0;
BA_ "GenSigTimeoutTime_ADCAM" SG_ 2564486631 N_PDU 0;
BA_ "GenSigTimeoutTime_SGW" SG_ 2564487440 N_PDU 0;
BA_ "GenSigTimeoutTime_RFHM" SG_ 2564487440 N_PDU 0;
BA_ "GenSigTimeoutTime_MPAD" SG_ 2564487440 N_PDU 0;
BA_ "GenSigTimeoutTime_IPC" SG_ 2564487440 N_PDU 0;
BA_ "GenSigTimeoutTime_GNMM" SG_ 2564487440 N_PDU 0;
BA_ "GenSigTimeoutTime_EVCU2" SG_ 2564487440 N_PDU 0;
BA_ "GenSigTimeoutTime_ESL" SG_ 2564487440 N_PDU 0;
BA_ "GenSigTimeoutTime_ECM" SG_ 2564487440 N_PDU 0;
BA_ "GenSigTimeoutTime_DTCM" SG_ 2564487440 N_PDU 0;
BA_ "GenSigTimeoutTime_DMSM" SG_ 2564487440 N_PDU 0;
BA_ "GenSigTimeoutTime_BSM" SG_ 2564487440 N_PDU 0;
BA_ "GenSigTimeoutTime_BCM" SG_ 2564487440 N_PDU 0;
BA_ "GenSigTimeoutTime_AGSM" SG_ 2564487440 N_PDU 0;
BA_ "GenSigTimeoutTime_ADCAM" SG_ 2564487440 N_PDU 0;
BA_ "GenSigTimeoutTime_AGSM" SG_ 2564554489 N_PDU 0;
BA_ "GenSigTimeoutTime_ADCAM" SG_ 2564554489 N_PDU 0;
BA_ "GenSigTimeoutTime_SGW" SG_ 2564554489 N_PDU 0;
BA_ "GenSigTimeoutTime_RFHM" SG_ 2564554489 N_PDU 0;
BA_ "GenSigTimeoutTime_MPAD" SG_ 2564554489 N_PDU 0;
BA_ "GenSigTimeoutTime_IPC" SG_ 2564554489 N_PDU 0;
BA_ "GenSigTimeoutTime_GNMM" SG_ 2564554489 N_PDU 0;
BA_ "GenSigTimeoutTime_EVCU2" SG_ 2564554489 N_PDU 0;
BA_ "GenSigTimeoutTime_ESL" SG_ 2564554489 N_PDU 0;
BA_ "GenSigTimeoutTime_ECM" SG_ 2564554489 N_PDU 0;
BA_ "GenSigTimeoutTime_DTCM" SG_ 2564554489 N_PDU 0;
BA_ "GenSigTimeoutTime_DMSM" SG_ 2564554489 N_PDU 0;
BA_ "GenSigTimeoutTime_BSM" SG_ 2564554489 N_PDU 0;
BA_ "GenSigTimeoutTime_BCM" SG_ 2564554489 N_PDU 0;
BA_ "GenSigTimeoutTime_SGW" SG_ 2564483061 N_PDU 0;
BA_ "GenSigTimeoutTime_RFHM" SG_ 2564483061 N_PDU 0;
BA_ "GenSigTimeoutTime_MPAD" SG_ 2564483061 N_PDU 0;
BA_ "GenSigTimeoutTime_IPC" SG_ 2564483061 N_PDU 0;
BA_ "GenSigTimeoutTime_GNMM" SG_ 2564483061 N_PDU 0;
BA_ "GenSigTimeoutTime_EVCU2" SG_ 2564483061 N_PDU 0;
BA_ "GenSigTimeoutTime_ESL" SG_ 2564483061 N_PDU 0;
BA_ "GenSigTimeoutTime_ECM" SG_ 2564483061 N_PDU 0;
BA_ "GenSigTimeoutTime_DTCM" SG_ 2564483061 N_PDU 0;
BA_ "GenSigTimeoutTime_DMSM" SG_ 2564483061 N_PDU 0;
BA_ "GenSigTimeoutTime_BSM" SG_ 2564483061 N_PDU 0;
BA_ "GenSigTimeoutTime_BCM" SG_ 2564483061 N_PDU 0;
BA_ "GenSigTimeoutTime_AGSM" SG_ 2564483061 N_PDU 0;
BA_ "GenSigTimeoutTime_ADCAM" SG_ 2564483061 N_PDU 0;
BA_ "GenSigTimeoutTime_SGW" SG_ 2564428025 N_PDU 0;
BA_ "GenSigTimeoutTime_RFHM" SG_ 2564428025 N_PDU 0;
BA_ "GenSigTimeoutTime_MPAD" SG_ 2564428025 N_PDU 0;
BA_ "GenSigTimeoutTime_IPC" SG_ 2564428025 N_PDU 0;
BA_ "GenSigTimeoutTime_GNMM" SG_ 2564428025 N_PDU 0;
BA_ "GenSigTimeoutTime_EVCU2" SG_ 2564428025 N_PDU 0;
BA_ "GenSigTimeoutTime_ESL" SG_ 2564428025 N_PDU 0;
BA_ "GenSigTimeoutTime_ECM" SG_ 2564428025 N_PDU 0;
BA_ "GenSigTimeoutTime_DTCM" SG_ 2564428025 N_PDU 0;
BA_ "GenSigTimeoutTime_DMSM" SG_ 2564428025 N_PDU 0;
BA_ "GenSigTimeoutTime_BSM" SG_ 2564428025 N_PDU 0;
BA_ "GenSigTimeoutTime_BCM" SG_ 2564428025 N_PDU 0;
BA_ "GenSigTimeoutTime_AGSM" SG_ 2564428025 N_PDU 0;
BA_ "GenSigTimeoutTime_ADCAM" SG_ 2564428025 N_PDU 0;
BA_ "GenSigTimeoutTime_SGW" SG_ 2654486592 CBV_bit6_PartialNtwInfBit 0;
BA_ "GenSigTimeoutTime_RFHM" SG_ 2654486592 CBV_bit6_PartialNtwInfBit 0;
BA_ "GenSigTimeoutTime_MPAD" SG_ 2654486592 CBV_bit6_PartialNtwInfBit 0;
BA_ "GenSigTimeoutTime_IPC" SG_ 2654486592 CBV_bit6_PartialNtwInfBit 0;
BA_ "GenSigTimeoutTime_GNMM" SG_ 2654486592 CBV_bit6_PartialNtwInfBit 0;
BA_ "GenSigTimeoutTime_EVCU2" SG_ 2654486592 CBV_bit6_PartialNtwInfBit 0;
BA_ "GenSigTimeoutTime_ESL" SG_ 2654486592 CBV_bit6_PartialNtwInfBit 0;
BA_ "GenSigTimeoutTime_ECM" SG_ 2654486592 CBV_bit6_PartialNtwInfBit 0;
BA_ "GenSigTimeoutTime_DTCM" SG_ 2654486592 CBV_bit6_PartialNtwInfBit 0;
BA_ "GenSigTimeoutTime_DMSM" SG_ 2654486592 CBV_bit6_PartialNtwInfBit 0;
BA_ "GenSigTimeoutTime_BSM" SG_ 2654486592 CBV_bit6_PartialNtwInfBit 0;
BA_ "GenSigTimeoutTime_BCM" SG_ 2654486592 CBV_bit6_PartialNtwInfBit 0;
BA_ "GenSigTimeoutTime_AGSM" SG_ 2654486592 CBV_bit6_PartialNtwInfBit 0;
BA_ "GenSigTimeoutTime_ADCAM" SG_ 2654486592 CBV_bit6_PartialNtwInfBit 0;
BA_ "GenSigTimeoutTime_SGW" SG_ 2654486592 CBV_bit5 0;
BA_ "GenSigTimeoutTime_RFHM" SG_ 2654486592 CBV_bit5 0;
BA_ "GenSigTimeoutTime_MPAD" SG_ 2654486592 CBV_bit5 0;
BA_ "GenSigTimeoutTime_IPC" SG_ 2654486592 CBV_bit5 0;
BA_ "GenSigTimeoutTime_GNMM" SG_ 2654486592 CBV_bit5 0;
BA_ "GenSigTimeoutTime_EVCU2" SG_ 2654486592 CBV_bit5 0;
BA_ "GenSigTimeoutTime_ESL" SG_ 2654486592 CBV_bit5 0;
BA_ "GenSigTimeoutTime_ECM" SG_ 2654486592 CBV_bit5 0;
BA_ "GenSigTimeoutTime_DTCM" SG_ 2654486592 CBV_bit5 0;
BA_ "GenSigTimeoutTime_DMSM" SG_ 2654486592 CBV_bit5 0;
BA_ "GenSigTimeoutTime_BSM" SG_ 2654486592 CBV_bit5 0;
BA_ "GenSigTimeoutTime_BCM" SG_ 2654486592 CBV_bit5 0;
BA_ "GenSigTimeoutTime_AGSM" SG_ 2654486592 CBV_bit5 0;
BA_ "GenSigTimeoutTime_ADCAM" SG_ 2654486592 CBV_bit5 0;
BA_ "GenSigTimeoutTime_SGW" SG_ 2654486592 CBV_bit4_ActiveWakeupBit 0;
BA_ "GenSigTimeoutTime_RFHM" SG_ 2654486592 CBV_bit4_ActiveWakeupBit 0;
BA_ "GenSigTimeoutTime_MPAD" SG_ 2654486592 CBV_bit4_ActiveWakeupBit 0;
BA_ "GenSigTimeoutTime_IPC" SG_ 2654486592 CBV_bit4_ActiveWakeupBit 0;
BA_ "GenSigTimeoutTime_GNMM" SG_ 2654486592 CBV_bit4_ActiveWakeupBit 0;
BA_ "GenSigTimeoutTime_EVCU2" SG_ 2654486592 CBV_bit4_ActiveWakeupBit 0;
BA_ "GenSigTimeoutTime_ESL" SG_ 2654486592 CBV_bit4_ActiveWakeupBit 0;
BA_ "GenSigTimeoutTime_ECM" SG_ 2654486592 CBV_bit4_ActiveWakeupBit 0;
BA_ "GenSigTimeoutTime_DTCM" SG_ 2654486592 CBV_bit4_ActiveWakeupBit 0;
BA_ "GenSigTimeoutTime_DMSM" SG_ 2654486592 CBV_bit4_ActiveWakeupBit 0;
BA_ "GenSigTimeoutTime_BSM" SG_ 2654486592 CBV_bit4_ActiveWakeupBit 0;
BA_ "GenSigTimeoutTime_BCM" SG_ 2654486592 CBV_bit4_ActiveWakeupBit 0;
BA_ "GenSigTimeoutTime_AGSM" SG_ 2654486592 CBV_bit4_ActiveWakeupBit 0;
BA_ "GenSigTimeoutTime_ADCAM" SG_ 2654486592 CBV_bit4_ActiveWakeupBit 0;
BA_ "GenSigTimeoutTime_SGW" SG_ 2654486592 CBV_bit3_NMCoordinatorBit 0;
BA_ "GenSigTimeoutTime_RFHM" SG_ 2654486592 CBV_bit3_NMCoordinatorBit 0;
BA_ "GenSigTimeoutTime_MPAD" SG_ 2654486592 CBV_bit3_NMCoordinatorBit 0;
BA_ "GenSigTimeoutTime_IPC" SG_ 2654486592 CBV_bit3_NMCoordinatorBit 0;
BA_ "GenSigTimeoutTime_SGW" SG_ 2654486592 CBV_bit2 0;
BA_ "GenSigTimeoutTime_RFHM" SG_ 2654486592 CBV_bit2 0;
BA_ "GenSigTimeoutTime_MPAD" SG_ 2654486592 CBV_bit2 0;
BA_ "GenSigTimeoutTime_IPC" SG_ 2654486592 CBV_bit2 0;
BA_ "GenSigTimeoutTime_GNMM" SG_ 2654486592 CBV_bit2 0;
BA_ "GenSigTimeoutTime_EVCU2" SG_ 2654486592 CBV_bit2 0;
BA_ "GenSigTimeoutTime_ESL" SG_ 2654486592 CBV_bit2 0;
BA_ "GenSigTimeoutTime_ECM" SG_ 2654486592 CBV_bit2 0;
BA_ "GenSigTimeoutTime_DTCM" SG_ 2654486592 CBV_bit2 0;
BA_ "GenSigTimeoutTime_DMSM" SG_ 2654486592 CBV_bit2 0;
BA_ "GenSigTimeoutTime_BSM" SG_ 2654486592 CBV_bit2 0;
BA_ "GenSigTimeoutTime_BCM" SG_ 2654486592 CBV_bit2 0;
BA_ "GenSigTimeoutTime_AGSM" SG_ 2654486592 CBV_bit2 0;
BA_ "GenSigTimeoutTime_ADCAM" SG_ 2654486592 CBV_bit2 0;
BA_ "GenSigTimeoutTime_GNMM" SG_ 2654486592 CBV_bit3_NMCoordinatorBit 0;
BA_ "GenSigTimeoutTime_EVCU2" SG_ 2654486592 CBV_bit3_NMCoordinatorBit 0;
BA_ "GenSigTimeoutTime_ESL" SG_ 2654486592 CBV_bit3_NMCoordinatorBit 0;
BA_ "GenSigTimeoutTime_ECM" SG_ 2654486592 CBV_bit3_NMCoordinatorBit 0;
BA_ "GenSigTimeoutTime_DTCM" SG_ 2654486592 CBV_bit3_NMCoordinatorBit 0;
BA_ "GenSigTimeoutTime_DMSM" SG_ 2654486592 CBV_bit3_NMCoordinatorBit 0;
BA_ "GenSigTimeoutTime_BSM" SG_ 2654486592 CBV_bit3_NMCoordinatorBit 0;
BA_ "GenSigTimeoutTime_BCM" SG_ 2654486592 CBV_bit3_NMCoordinatorBit 0;
BA_ "GenSigTimeoutTime_AGSM" SG_ 2654486592 CBV_bit3_NMCoordinatorBit 0;
BA_ "GenSigTimeoutTime_ADCAM" SG_ 2654486592 CBV_bit3_NMCoordinatorBit 0;
BA_ "GenSigTimeoutTime_SGW" SG_ 2654486592 CBV_bit1 0;
BA_ "GenSigTimeoutTime_RFHM" SG_ 2654486592 CBV_bit1 0;
BA_ "GenSigTimeoutTime_MPAD" SG_ 2654486592 CBV_bit1 0;
BA_ "GenSigTimeoutTime_IPC" SG_ 2654486592 CBV_bit1 0;
BA_ "GenSigTimeoutTime_GNMM" SG_ 2654486592 CBV_bit1 0;
BA_ "GenSigTimeoutTime_EVCU2" SG_ 2654486592 CBV_bit1 0;
BA_ "GenSigTimeoutTime_ESL" SG_ 2654486592 CBV_bit1 0;
BA_ "GenSigTimeoutTime_ECM" SG_ 2654486592 CBV_bit1 0;
BA_ "GenSigTimeoutTime_DTCM" SG_ 2654486592 CBV_bit1 0;
BA_ "GenSigTimeoutTime_DMSM" SG_ 2654486592 CBV_bit1 0;
BA_ "GenSigTimeoutTime_BSM" SG_ 2654486592 CBV_bit1 0;
BA_ "GenSigTimeoutTime_BCM" SG_ 2654486592 CBV_bit1 0;
BA_ "GenSigTimeoutTime_AGSM" SG_ 2654486592 CBV_bit1 0;
BA_ "GenSigTimeoutTime_ADCAM" SG_ 2654486592 CBV_bit1 0;
BA_ "GenSigTimeoutTime_SGW" SG_ 2654486592 CBV_bit0_RepeatMessageRequestBit 0;
BA_ "GenSigTimeoutTime_RFHM" SG_ 2654486592 CBV_bit0_RepeatMessageRequestBit 0;
BA_ "GenSigTimeoutTime_MPAD" SG_ 2654486592 CBV_bit0_RepeatMessageRequestBit 0;
BA_ "GenSigTimeoutTime_IPC" SG_ 2654486592 CBV_bit0_RepeatMessageRequestBit 0;
BA_ "GenSigTimeoutTime_GNMM" SG_ 2654486592 CBV_bit0_RepeatMessageRequestBit 0;
BA_ "GenSigTimeoutTime_EVCU2" SG_ 2654486592 CBV_bit0_RepeatMessageRequestBit 0;
BA_ "GenSigTimeoutTime_ESL" SG_ 2654486592 CBV_bit0_RepeatMessageRequestBit 0;
BA_ "GenSigTimeoutTime_ECM" SG_ 2654486592 CBV_bit0_RepeatMessageRequestBit 0;
BA_ "GenSigTimeoutTime_DTCM" SG_ 2654486592 CBV_bit0_RepeatMessageRequestBit 0;
BA_ "GenSigTimeoutTime_DMSM" SG_ 2654486592 CBV_bit0_RepeatMessageRequestBit 0;
BA_ "GenSigTimeoutTime_BSM" SG_ 2654486592 CBV_bit0_RepeatMessageRequestBit 0;
BA_ "GenSigTimeoutTime_BCM" SG_ 2654486592 CBV_bit0_RepeatMessageRequestBit 0;
BA_ "GenSigTimeoutTime_AGSM" SG_ 2654486592 CBV_bit0_RepeatMessageRequestBit 0;
BA_ "GenSigTimeoutTime_ADCAM" SG_ 2654486592 CBV_bit0_RepeatMessageRequestBit 0;
BA_ "GenSigTimeoutTime_SGW" SG_ 616 Set_Speed_MPH_VIP 0;
BA_ "GenSigTimeoutTime_RFHM" SG_ 616 Set_Speed_MPH_VIP 0;
BA_ "GenSigTimeoutTime_MPAD" SG_ 616 Set_Speed_MPH_VIP 0;
BA_ "GenSigTimeoutTime_IPC" SG_ 616 Set_Speed_MPH_VIP 0;
BA_ "GenSigTimeoutTime_GNMM" SG_ 616 Set_Speed_MPH_VIP 0;
BA_ "GenSigTimeoutTime_EVCU2" SG_ 616 Set_Speed_MPH_VIP 0;
BA_ "GenSigTimeoutTime_ESL" SG_ 616 Set_Speed_MPH_VIP 0;
BA_ "GenSigTimeoutTime_ECM" SG_ 616 Set_Speed_MPH_VIP 0;
BA_ "GenSigTimeoutTime_DTCM" SG_ 616 Set_Speed_MPH_VIP 0;
BA_ "GenSigTimeoutTime_DMSM" SG_ 616 Set_Speed_MPH_VIP 0;
BA_ "GenSigTimeoutTime_BSM" SG_ 616 Set_Speed_MPH_VIP 0;
BA_ "GenSigTimeoutTime_BCM" SG_ 616 Set_Speed_MPH_VIP 0;
BA_ "GenSigTimeoutTime_AGSM" SG_ 616 Set_Speed_MPH_VIP 0;
BA_ "GenSigTimeoutTime_ADCAM" SG_ 616 Set_Speed_MPH_VIP 0;
BA_ "GenSigSendType" SG_ 616 Set_Speed_MPH_VIP 3;
BA_ "GenSigTimeoutTime_SGW" SG_ 616 Set_Speed_KPH_VIP 0;
BA_ "GenSigTimeoutTime_RFHM" SG_ 616 Set_Speed_KPH_VIP 0;
BA_ "GenSigTimeoutTime_MPAD" SG_ 616 Set_Speed_KPH_VIP 0;
BA_ "GenSigTimeoutTime_IPC" SG_ 616 Set_Speed_KPH_VIP 0;
BA_ "GenSigTimeoutTime_GNMM" SG_ 616 Set_Speed_KPH_VIP 0;
BA_ "GenSigTimeoutTime_EVCU2" SG_ 616 Set_Speed_KPH_VIP 0;
BA_ "GenSigTimeoutTime_ESL" SG_ 616 Set_Speed_KPH_VIP 0;
BA_ "GenSigTimeoutTime_ECM" SG_ 616 Set_Speed_KPH_VIP 0;
BA_ "GenSigTimeoutTime_DTCM" SG_ 616 Set_Speed_KPH_VIP 0;
BA_ "GenSigTimeoutTime_DMSM" SG_ 616 Set_Speed_KPH_VIP 0;
BA_ "GenSigTimeoutTime_BSM" SG_ 616 Set_Speed_KPH_VIP 0;
BA_ "GenSigTimeoutTime_BCM" SG_ 616 Set_Speed_KPH_VIP 0;
BA_ "GenSigTimeoutTime_AGSM" SG_ 616 Set_Speed_KPH_VIP 0;
BA_ "GenSigTimeoutTime_ADCAM" SG_ 616 Set_Speed_KPH_VIP 0;
BA_ "GenSigSendType" SG_ 616 Set_Speed_KPH_VIP 3;
BA_ "GenSigTimeoutTime_SGW" SG_ 616 RRCC_LEDSts_VIP 0;
BA_ "GenSigTimeoutTime_RFHM" SG_ 616 RRCC_LEDSts_VIP 0;
BA_ "GenSigTimeoutTime_IPC" SG_ 616 RRCC_LEDSts_VIP 0;
BA_ "GenSigTimeoutTime_GNMM" SG_ 616 RRCC_LEDSts_VIP 0;
BA_ "GenSigTimeoutTime_EVCU2" SG_ 616 RRCC_LEDSts_VIP 0;
BA_ "GenSigTimeoutTime_ESL" SG_ 616 RRCC_LEDSts_VIP 0;
BA_ "GenSigTimeoutTime_ECM" SG_ 616 RRCC_LEDSts_VIP 0;
BA_ "GenSigTimeoutTime_DTCM" SG_ 616 RRCC_LEDSts_VIP 0;
BA_ "GenSigTimeoutTime_DMSM" SG_ 616 RRCC_LEDSts_VIP 0;
BA_ "GenSigTimeoutTime_BSM" SG_ 616 RRCC_LEDSts_VIP 0;
BA_ "GenSigTimeoutTime_BCM" SG_ 616 RRCC_LEDSts_VIP 0;
BA_ "GenSigTimeoutTime_AGSM" SG_ 616 RRCC_LEDSts_VIP 0;
BA_ "GenSigTimeoutTime_ADCAM" SG_ 616 RRCC_LEDSts_VIP 0;
BA_ "GenSigSendType" SG_ 616 RRCC_LEDSts_VIP 3;
BA_ "GenSigTimeoutTime_SGW" SG_ 616 MessageCounter_ADAS_FD_HMI_VIP 0;
BA_ "GenSigTimeoutTime_RFHM" SG_ 616 MessageCounter_ADAS_FD_HMI_VIP 0;
BA_ "GenSigTimeoutTime_IPC" SG_ 616 MessageCounter_ADAS_FD_HMI_VIP 0;
BA_ "GenSigTimeoutTime_GNMM" SG_ 616 MessageCounter_ADAS_FD_HMI_VIP 0;
BA_ "GenSigTimeoutTime_EVCU2" SG_ 616 MessageCounter_ADAS_FD_HMI_VIP 0;
BA_ "GenSigTimeoutTime_ESL" SG_ 616 MessageCounter_ADAS_FD_HMI_VIP 0;
BA_ "GenSigTimeoutTime_ECM" SG_ 616 MessageCounter_ADAS_FD_HMI_VIP 0;
BA_ "GenSigTimeoutTime_DTCM" SG_ 616 MessageCounter_ADAS_FD_HMI_VIP 0;
BA_ "GenSigTimeoutTime_DMSM" SG_ 616 MessageCounter_ADAS_FD_HMI_VIP 0;
BA_ "GenSigTimeoutTime_BSM" SG_ 616 MessageCounter_ADAS_FD_HMI_VIP 0;
BA_ "GenSigTimeoutTime_BCM" SG_ 616 MessageCounter_ADAS_FD_HMI_VIP 0;
BA_ "GenSigTimeoutTime_AGSM" SG_ 616 MessageCounter_ADAS_FD_HMI_VIP 0;
BA_ "GenSigTimeoutTime_ADCAM" SG_ 616 MessageCounter_ADAS_FD_HMI_VIP 0;
BA_ "GenSigTimeoutTime_SGW" SG_ 616 CRC_ADAS_FD_HMI_VIP 0;
BA_ "GenSigTimeoutTime_RFHM" SG_ 616 CRC_ADAS_FD_HMI_VIP 0;
BA_ "GenSigTimeoutTime_IPC" SG_ 616 CRC_ADAS_FD_HMI_VIP 0;
BA_ "GenSigTimeoutTime_GNMM" SG_ 616 CRC_ADAS_FD_HMI_VIP 0;
BA_ "GenSigTimeoutTime_EVCU2" SG_ 616 CRC_ADAS_FD_HMI_VIP 0;
BA_ "GenSigTimeoutTime_ESL" SG_ 616 CRC_ADAS_FD_HMI_VIP 0;
BA_ "GenSigTimeoutTime_ECM" SG_ 616 CRC_ADAS_FD_HMI_VIP 0;
BA_ "GenSigTimeoutTime_DTCM" SG_ 616 CRC_ADAS_FD_HMI_VIP 0;
BA_ "GenSigTimeoutTime_DMSM" SG_ 616 CRC_ADAS_FD_HMI_VIP 0;
BA_ "GenSigTimeoutTime_BSM" SG_ 616 CRC_ADAS_FD_HMI_VIP 0;
BA_ "GenSigTimeoutTime_BCM" SG_ 616 CRC_ADAS_FD_HMI_VIP 0;
BA_ "GenSigTimeoutTime_AGSM" SG_ 616 CRC_ADAS_FD_HMI_VIP 0;
BA_ "GenSigTimeoutTime_ADCAM" SG_ 616 CRC_ADAS_FD_HMI_VIP 0;
BA_ "GenSigTimeoutTime_RFHM" SG_ 1487 Est_Range_FullCharge 0;
BA_ "GenSigTimeoutTime_MPAD" SG_ 1487 Est_Range_FullCharge 0;
BA_ "GenSigTimeoutTime_IPC" SG_ 1487 Est_Range_FullCharge 0;
BA_ "GenSigTimeoutTime_GNMM" SG_ 1487 Est_Range_FullCharge 0;
BA_ "GenSigTimeoutTime_RFHM" SG_ 1487 EV_Charge_Current 0;
BA_ "GenSigTimeoutTime_MPAD" SG_ 1487 EV_Charge_Current 0;
BA_ "GenSigTimeoutTime_IPC" SG_ 1487 EV_Charge_Current 0;
BA_ "GenSigTimeoutTime_GNMM" SG_ 1487 EV_Charge_Current 0;
BA_ "GenSigTimeoutTime_EVCU2" SG_ 1487 EV_Charge_Current 0;
BA_ "GenSigTimeoutTime_ESL" SG_ 1487 EV_Charge_Current 0;
BA_ "GenSigTimeoutTime_ECM" SG_ 1487 EV_Charge_Current 0;
BA_ "GenSigTimeoutTime_DTCM" SG_ 1487 EV_Charge_Current 0;
BA_ "GenSigTimeoutTime_DMSM" SG_ 1487 EV_Charge_Current 0;
BA_ "GenSigTimeoutTime_BSM" SG_ 1487 EV_Charge_Current 0;
BA_ "GenSigTimeoutTime_BCM" SG_ 1487 EV_Charge_Current 0;
BA_ "GenSigTimeoutTime_AGSM" SG_ 1487 EV_Charge_Current 0;
BA_ "GenSigTimeoutTime_ADCAM" SG_ 1487 EV_Charge_Current 0;
BA_ "GenSigTimeoutTime_RFHM" SG_ 1487 EVSE_Power 0;
BA_ "GenSigTimeoutTime_MPAD" SG_ 1487 EVSE_Power 0;
BA_ "GenSigTimeoutTime_IPC" SG_ 1487 EVSE_Power 0;
BA_ "GenSigTimeoutTime_GNMM" SG_ 1487 EVSE_Power 0;
BA_ "GenSigTimeoutTime_EVCU2" SG_ 1487 EVSE_Power 0;
BA_ "GenSigTimeoutTime_ESL" SG_ 1487 EVSE_Power 0;
BA_ "GenSigTimeoutTime_ECM" SG_ 1487 EVSE_Power 0;
BA_ "GenSigTimeoutTime_DTCM" SG_ 1487 EVSE_Power 0;
BA_ "GenSigTimeoutTime_DMSM" SG_ 1487 EVSE_Power 0;
BA_ "GenSigTimeoutTime_BSM" SG_ 1487 EVSE_Power 0;
BA_ "GenSigTimeoutTime_BCM" SG_ 1487 EVSE_Power 0;
BA_ "GenSigTimeoutTime_AGSM" SG_ 1487 EVSE_Power 0;
BA_ "GenSigTimeoutTime_ADCAM" SG_ 1487 EVSE_Power 0;
BA_ "GenSigTimeoutTime_ADCAM" SG_ 1487 Lv1_EstChargeTime_80 0;
BA_ "GenSigTimeoutTime_RFHM" SG_ 1487 Lv1_EstChargeTime_80 0;
BA_ "GenSigTimeoutTime_MPAD" SG_ 1487 Lv1_EstChargeTime_80 0;
BA_ "GenSigTimeoutTime_IPC" SG_ 1487 Lv1_EstChargeTime_80 0;
BA_ "GenSigTimeoutTime_GNMM" SG_ 1487 Lv1_EstChargeTime_80 0;
BA_ "GenSigTimeoutTime_EVCU2" SG_ 1487 Lv1_EstChargeTime_80 0;
BA_ "GenSigTimeoutTime_ESL" SG_ 1487 Lv1_EstChargeTime_80 0;
BA_ "GenSigTimeoutTime_ECM" SG_ 1487 Lv1_EstChargeTime_80 0;
BA_ "GenSigTimeoutTime_DTCM" SG_ 1487 Lv1_EstChargeTime_80 0;
BA_ "GenSigTimeoutTime_DMSM" SG_ 1487 Lv1_EstChargeTime_80 0;
BA_ "GenSigTimeoutTime_BSM" SG_ 1487 Lv1_EstChargeTime_80 0;
BA_ "GenSigTimeoutTime_BCM" SG_ 1487 Lv1_EstChargeTime_80 0;
BA_ "GenSigTimeoutTime_AGSM" SG_ 1487 Lv1_EstChargeTime_80 0;
BA_ "GenSigTimeoutTime_RFHM" SG_ 1487 Lv2_EstChargeTime_80 0;
BA_ "GenSigTimeoutTime_MPAD" SG_ 1487 Lv2_EstChargeTime_80 0;
BA_ "GenSigTimeoutTime_IPC" SG_ 1487 Lv2_EstChargeTime_80 0;
BA_ "GenSigTimeoutTime_GNMM" SG_ 1487 Lv2_EstChargeTime_80 0;
BA_ "GenSigTimeoutTime_EVCU2" SG_ 1487 Lv2_EstChargeTime_80 0;
BA_ "GenSigTimeoutTime_ESL" SG_ 1487 Lv2_EstChargeTime_80 0;
BA_ "GenSigTimeoutTime_ECM" SG_ 1487 Lv2_EstChargeTime_80 0;
BA_ "GenSigTimeoutTime_DTCM" SG_ 1487 Lv2_EstChargeTime_80 0;
BA_ "GenSigTimeoutTime_DMSM" SG_ 1487 Lv2_EstChargeTime_80 0;
BA_ "GenSigTimeoutTime_BSM" SG_ 1487 Lv2_EstChargeTime_80 0;
BA_ "GenSigTimeoutTime_BCM" SG_ 1487 Lv2_EstChargeTime_80 0;
BA_ "GenSigTimeoutTime_AGSM" SG_ 1487 Lv2_EstChargeTime_80 0;
BA_ "GenSigTimeoutTime_ADCAM" SG_ 1487 Lv2_EstChargeTime_80 0;
BA_ "GenSigTimeoutTime_RFHM" SG_ 1487 Total_Battery_Capacity 0;
BA_ "GenSigTimeoutTime_MPAD" SG_ 1487 Total_Battery_Capacity 0;
BA_ "GenSigTimeoutTime_IPC" SG_ 1487 Total_Battery_Capacity 0;
BA_ "GenSigTimeoutTime_GNMM" SG_ 1487 Total_Battery_Capacity 0;
BA_ "GenSigTimeoutTime_EVCU2" SG_ 1487 Total_Battery_Capacity 0;
BA_ "GenSigTimeoutTime_ESL" SG_ 1487 Total_Battery_Capacity 0;
BA_ "GenSigTimeoutTime_ECM" SG_ 1487 Total_Battery_Capacity 0;
BA_ "GenSigTimeoutTime_DTCM" SG_ 1487 Total_Battery_Capacity 0;
BA_ "GenSigTimeoutTime_DMSM" SG_ 1487 Total_Battery_Capacity 0;
BA_ "GenSigTimeoutTime_BSM" SG_ 1487 Total_Battery_Capacity 0;
BA_ "GenSigTimeoutTime_BCM" SG_ 1487 Total_Battery_Capacity 0;
BA_ "GenSigTimeoutTime_AGSM" SG_ 1487 Total_Battery_Capacity 0;
BA_ "GenSigTimeoutTime_ADCAM" SG_ 1487 Total_Battery_Capacity 0;
BA_ "GenSigTimeoutTime_RFHM" SG_ 2654339137 GenericFailSts_FD03_RFHM 0;
BA_ "GenSigTimeoutTime_MPAD" SG_ 2654339137 GenericFailSts_FD03_RFHM 0;
BA_ "GenSigTimeoutTime_IPC" SG_ 2654339137 GenericFailSts_FD03_RFHM 0;
BA_ "GenSigTimeoutTime_GNMM" SG_ 2654339137 GenericFailSts_FD03_RFHM 0;
BA_ "GenSigTimeoutTime_EVCU2" SG_ 2654339137 GenericFailSts_FD03_RFHM 0;
BA_ "GenSigTimeoutTime_ESL" SG_ 2654339137 GenericFailSts_FD03_RFHM 0;
BA_ "GenSigTimeoutTime_ECM" SG_ 2654339137 GenericFailSts_FD03_RFHM 0;
BA_ "GenSigTimeoutTime_DTCM" SG_ 2654339137 GenericFailSts_FD03_RFHM 0;
BA_ "GenSigTimeoutTime_DMSM" SG_ 2654339137 GenericFailSts_FD03_RFHM 0;
BA_ "GenSigTimeoutTime_BSM" SG_ 2654339137 GenericFailSts_FD03_RFHM 0;
BA_ "GenSigTimeoutTime_AGSM" SG_ 2654339137 GenericFailSts_FD03_RFHM 0;
BA_ "GenSigTimeoutTime_ADCAM" SG_ 2654339137 GenericFailSts_FD03_RFHM 0;
BA_ "GenSigTimeoutTime_RFHM" SG_ 2654339137 EOL_FD03_RFHM 0;
BA_ "GenSigTimeoutTime_MPAD" SG_ 2654339137 EOL_FD03_RFHM 0;
BA_ "GenSigTimeoutTime_IPC" SG_ 2654339137 EOL_FD03_RFHM 0;
BA_ "GenSigTimeoutTime_GNMM" SG_ 2654339137 EOL_FD03_RFHM 0;
BA_ "GenSigTimeoutTime_EVCU2" SG_ 2654339137 EOL_FD03_RFHM 0;
BA_ "GenSigTimeoutTime_ESL" SG_ 2654339137 EOL_FD03_RFHM 0;
BA_ "GenSigTimeoutTime_ECM" SG_ 2654339137 EOL_FD03_RFHM 0;
BA_ "GenSigTimeoutTime_DTCM" SG_ 2654339137 EOL_FD03_RFHM 0;
BA_ "GenSigTimeoutTime_DMSM" SG_ 2654339137 EOL_FD03_RFHM 0;
BA_ "GenSigTimeoutTime_BSM" SG_ 2654339137 EOL_FD03_RFHM 0;
BA_ "GenSigTimeoutTime_AGSM" SG_ 2654339137 EOL_FD03_RFHM 0;
BA_ "GenSigTimeoutTime_ADCAM" SG_ 2654339137 EOL_FD03_RFHM 0;
BA_ "GenSigTimeoutTime_RFHM" SG_ 2654339137 CurrentFailSts_FD03_RFHM 0;
BA_ "GenSigTimeoutTime_MPAD" SG_ 2654339137 CurrentFailSts_FD03_RFHM 0;
BA_ "GenSigTimeoutTime_IPC" SG_ 2654339137 CurrentFailSts_FD03_RFHM 0;
BA_ "GenSigTimeoutTime_GNMM" SG_ 2654339137 CurrentFailSts_FD03_RFHM 0;
BA_ "GenSigTimeoutTime_EVCU2" SG_ 2654339137 CurrentFailSts_FD03_RFHM 0;
BA_ "GenSigTimeoutTime_ESL" SG_ 2654339137 CurrentFailSts_FD03_RFHM 0;
BA_ "GenSigTimeoutTime_ECM" SG_ 2654339137 CurrentFailSts_FD03_RFHM 0;
BA_ "GenSigTimeoutTime_DTCM" SG_ 2654339137 CurrentFailSts_FD03_RFHM 0;
BA_ "GenSigTimeoutTime_DMSM" SG_ 2654339137 CurrentFailSts_FD03_RFHM 0;
BA_ "GenSigTimeoutTime_BSM" SG_ 2654339137 CurrentFailSts_FD03_RFHM 0;
BA_ "GenSigTimeoutTime_AGSM" SG_ 2654339137 CurrentFailSts_FD03_RFHM 0;
BA_ "GenSigTimeoutTime_ADCAM" SG_ 2654339137 CurrentFailSts_FD03_RFHM 0;
BA_ "GenSigTimeoutTime_SGW" SG_ 2651930684 Digit_05_PBWM 0;
BA_ "GenSigTimeoutTime_RFHM" SG_ 2651930684 Digit_05_PBWM 0;
BA_ "GenSigTimeoutTime_MPAD" SG_ 2651930684 Digit_05_PBWM 0;
BA_ "GenSigTimeoutTime_IPC" SG_ 2651930684 Digit_05_PBWM 0;
BA_ "GenSigTimeoutTime_GNMM" SG_ 2651930684 Digit_05_PBWM 0;
BA_ "GenSigTimeoutTime_EVCU2" SG_ 2651930684 Digit_05_PBWM 0;
BA_ "GenSigTimeoutTime_ESL" SG_ 2651930684 Digit_05_PBWM 0;
BA_ "GenSigTimeoutTime_ECM" SG_ 2651930684 Digit_05_PBWM 0;
BA_ "GenSigTimeoutTime_DTCM" SG_ 2651930684 Digit_05_PBWM 0;
BA_ "GenSigTimeoutTime_DMSM" SG_ 2651930684 Digit_05_PBWM 0;
BA_ "GenSigTimeoutTime_BSM" SG_ 2651930684 Digit_05_PBWM 0;
BA_ "GenSigTimeoutTime_AGSM" SG_ 2651930684 Digit_05_PBWM 0;
BA_ "GenSigTimeoutTime_ADCAM" SG_ 2651930684 Digit_05_PBWM 0;
BA_ "GenSigTimeoutTime_SGW" SG_ 2651930684 Digit_06_PBWM 0;
BA_ "GenSigTimeoutTime_RFHM" SG_ 2651930684 Digit_06_PBWM 0;
BA_ "GenSigTimeoutTime_MPAD" SG_ 2651930684 Digit_06_PBWM 0;
BA_ "GenSigTimeoutTime_IPC" SG_ 2651930684 Digit_06_PBWM 0;
BA_ "GenSigTimeoutTime_GNMM" SG_ 2651930684 Digit_06_PBWM 0;
BA_ "GenSigTimeoutTime_EVCU2" SG_ 2651930684 Digit_06_PBWM 0;
BA_ "GenSigTimeoutTime_ESL" SG_ 2651930684 Digit_06_PBWM 0;
BA_ "GenSigTimeoutTime_ECM" SG_ 2651930684 Digit_06_PBWM 0;
BA_ "GenSigTimeoutTime_DTCM" SG_ 2651930684 Digit_06_PBWM 0;
BA_ "GenSigTimeoutTime_DMSM" SG_ 2651930684 Digit_06_PBWM 0;
BA_ "GenSigTimeoutTime_BSM" SG_ 2651930684 Digit_06_PBWM 0;
BA_ "GenSigTimeoutTime_AGSM" SG_ 2651930684 Digit_06_PBWM 0;
BA_ "GenSigTimeoutTime_ADCAM" SG_ 2651930684 Digit_06_PBWM 0;
BA_ "GenSigTimeoutTime_SGW" SG_ 2651930684 Digit_07_PBWM 0;
BA_ "GenSigTimeoutTime_RFHM" SG_ 2651930684 Digit_07_PBWM 0;
BA_ "GenSigTimeoutTime_MPAD" SG_ 2651930684 Digit_07_PBWM 0;
BA_ "GenSigTimeoutTime_IPC" SG_ 2651930684 Digit_07_PBWM 0;
BA_ "GenSigTimeoutTime_GNMM" SG_ 2651930684 Digit_07_PBWM 0;
BA_ "GenSigTimeoutTime_EVCU2" SG_ 2651930684 Digit_07_PBWM 0;
BA_ "GenSigTimeoutTime_ESL" SG_ 2651930684 Digit_07_PBWM 0;
BA_ "GenSigTimeoutTime_ECM" SG_ 2651930684 Digit_07_PBWM 0;
BA_ "GenSigTimeoutTime_DTCM" SG_ 2651930684 Digit_07_PBWM 0;
BA_ "GenSigTimeoutTime_DMSM" SG_ 2651930684 Digit_07_PBWM 0;
BA_ "GenSigTimeoutTime_BSM" SG_ 2651930684 Digit_07_PBWM 0;
BA_ "GenSigTimeoutTime_AGSM" SG_ 2651930684 Digit_07_PBWM 0;
BA_ "GenSigTimeoutTime_ADCAM" SG_ 2651930684 Digit_07_PBWM 0;
BA_ "GenSigTimeoutTime_SGW" SG_ 2651930684 Digit_08_PBWM 0;
BA_ "GenSigTimeoutTime_RFHM" SG_ 2651930684 Digit_08_PBWM 0;
BA_ "GenSigTimeoutTime_MPAD" SG_ 2651930684 Digit_08_PBWM 0;
BA_ "GenSigTimeoutTime_IPC" SG_ 2651930684 Digit_08_PBWM 0;
BA_ "GenSigTimeoutTime_GNMM" SG_ 2651930684 Digit_08_PBWM 0;
BA_ "GenSigTimeoutTime_EVCU2" SG_ 2651930684 Digit_08_PBWM 0;
BA_ "GenSigTimeoutTime_ESL" SG_ 2651930684 Digit_08_PBWM 0;
BA_ "GenSigTimeoutTime_ECM" SG_ 2651930684 Digit_08_PBWM 0;
BA_ "GenSigTimeoutTime_DTCM" SG_ 2651930684 Digit_08_PBWM 0;
BA_ "GenSigTimeoutTime_DMSM" SG_ 2651930684 Digit_08_PBWM 0;
BA_ "GenSigTimeoutTime_BSM" SG_ 2651930684 Digit_08_PBWM 0;
BA_ "GenSigTimeoutTime_AGSM" SG_ 2651930684 Digit_08_PBWM 0;
BA_ "GenSigTimeoutTime_ADCAM" SG_ 2651930684 Digit_08_PBWM 0;
BA_ "GenSigTimeoutTime_SGW" SG_ 2651930684 Digit_09_PBWM 0;
BA_ "GenSigTimeoutTime_RFHM" SG_ 2651930684 Digit_09_PBWM 0;
BA_ "GenSigTimeoutTime_MPAD" SG_ 2651930684 Digit_09_PBWM 0;
BA_ "GenSigTimeoutTime_IPC" SG_ 2651930684 Digit_09_PBWM 0;
BA_ "GenSigTimeoutTime_GNMM" SG_ 2651930684 Digit_09_PBWM 0;
BA_ "GenSigTimeoutTime_EVCU2" SG_ 2651930684 Digit_09_PBWM 0;
BA_ "GenSigTimeoutTime_ESL" SG_ 2651930684 Digit_09_PBWM 0;
BA_ "GenSigTimeoutTime_ECM" SG_ 2651930684 Digit_09_PBWM 0;
BA_ "GenSigTimeoutTime_DTCM" SG_ 2651930684 Digit_09_PBWM 0;
BA_ "GenSigTimeoutTime_DMSM" SG_ 2651930684 Digit_09_PBWM 0;
BA_ "GenSigTimeoutTime_BSM" SG_ 2651930684 Digit_09_PBWM 0;
BA_ "GenSigTimeoutTime_AGSM" SG_ 2651930684 Digit_09_PBWM 0;
BA_ "GenSigTimeoutTime_ADCAM" SG_ 2651930684 Digit_09_PBWM 0;
BA_ "GenSigTimeoutTime_SGW" SG_ 2651930684 Digit_10_PBWM 0;
BA_ "GenSigTimeoutTime_RFHM" SG_ 2651930684 Digit_10_PBWM 0;
BA_ "GenSigTimeoutTime_MPAD" SG_ 2651930684 Digit_10_PBWM 0;
BA_ "GenSigTimeoutTime_IPC" SG_ 2651930684 Digit_10_PBWM 0;
BA_ "GenSigTimeoutTime_GNMM" SG_ 2651930684 Digit_10_PBWM 0;
BA_ "GenSigTimeoutTime_EVCU2" SG_ 2651930684 Digit_10_PBWM 0;
BA_ "GenSigTimeoutTime_ESL" SG_ 2651930684 Digit_10_PBWM 0;
BA_ "GenSigTimeoutTime_ECM" SG_ 2651930684 Digit_10_PBWM 0;
BA_ "GenSigTimeoutTime_DTCM" SG_ 2651930684 Digit_10_PBWM 0;
BA_ "GenSigTimeoutTime_DMSM" SG_ 2651930684 Digit_10_PBWM 0;
BA_ "GenSigTimeoutTime_BSM" SG_ 2651930684 Digit_10_PBWM 0;
BA_ "GenSigTimeoutTime_AGSM" SG_ 2651930684 Digit_10_PBWM 0;
BA_ "GenSigTimeoutTime_ADCAM" SG_ 2651930684 Digit_10_PBWM 0;
BA_ "GenSigTimeoutTime_SGW" SG_ 2651930684 Digit_11_PBWM 0;
BA_ "GenSigTimeoutTime_RFHM" SG_ 2651930684 Digit_11_PBWM 0;
BA_ "GenSigTimeoutTime_MPAD" SG_ 2651930684 Digit_11_PBWM 0;
BA_ "GenSigTimeoutTime_IPC" SG_ 2651930684 Digit_11_PBWM 0;
BA_ "GenSigTimeoutTime_GNMM" SG_ 2651930684 Digit_11_PBWM 0;
BA_ "GenSigTimeoutTime_EVCU2" SG_ 2651930684 Digit_11_PBWM 0;
BA_ "GenSigTimeoutTime_ESL" SG_ 2651930684 Digit_11_PBWM 0;
BA_ "GenSigTimeoutTime_ECM" SG_ 2651930684 Digit_11_PBWM 0;
BA_ "GenSigTimeoutTime_DTCM" SG_ 2651930684 Digit_11_PBWM 0;
BA_ "GenSigTimeoutTime_DMSM" SG_ 2651930684 Digit_11_PBWM 0;
BA_ "GenSigTimeoutTime_BSM" SG_ 2651930684 Digit_11_PBWM 0;
BA_ "GenSigTimeoutTime_AGSM" SG_ 2651930684 Digit_11_PBWM 0;
BA_ "GenSigTimeoutTime_ADCAM" SG_ 2651930684 Digit_11_PBWM 0;
BA_ "GenSigTimeoutTime_SGW" SG_ 2651930690 Digit_11_DMPI 0;
BA_ "GenSigTimeoutTime_RFHM" SG_ 2651930690 Digit_11_DMPI 0;
BA_ "GenSigTimeoutTime_MPAD" SG_ 2651930690 Digit_11_DMPI 0;
BA_ "GenSigTimeoutTime_IPC" SG_ 2651930690 Digit_11_DMPI 0;
BA_ "GenSigTimeoutTime_GNMM" SG_ 2651930690 Digit_11_DMPI 0;
BA_ "GenSigTimeoutTime_EVCU2" SG_ 2651930690 Digit_11_DMPI 0;
BA_ "GenSigTimeoutTime_ESL" SG_ 2651930690 Digit_11_DMPI 0;
BA_ "GenSigTimeoutTime_ECM" SG_ 2651930690 Digit_11_DMPI 0;
BA_ "GenSigTimeoutTime_DTCM" SG_ 2651930690 Digit_11_DMPI 0;
BA_ "GenSigTimeoutTime_DMSM" SG_ 2651930690 Digit_11_DMPI 0;
BA_ "GenSigTimeoutTime_BSM" SG_ 2651930690 Digit_11_DMPI 0;
BA_ "GenSigTimeoutTime_AGSM" SG_ 2651930690 Digit_11_DMPI 0;
BA_ "GenSigTimeoutTime_ESL" SG_ 2654339137 GenericFailSts_FD09_RFHM 0;
BA_ "GenSigTimeoutTime_ECM" SG_ 2654339137 GenericFailSts_FD09_RFHM 0;
BA_ "GenSigTimeoutTime_DTCM" SG_ 2654339137 GenericFailSts_FD09_RFHM 0;
BA_ "GenSigTimeoutTime_DMSM" SG_ 2654339137 GenericFailSts_FD09_RFHM 0;
BA_ "GenSigTimeoutTime_BSM" SG_ 2654339137 GenericFailSts_FD09_RFHM 0;
BA_ "GenSigTimeoutTime_BCM" SG_ 2654339137 GenericFailSts_FD09_RFHM 0;
BA_ "GenSigTimeoutTime_AGSM" SG_ 2654339137 GenericFailSts_FD09_RFHM 0;
BA_ "GenSigTimeoutTime_ADCAM" SG_ 2654339137 GenericFailSts_FD09_RFHM 0;
BA_ "GenSigTimeoutTime_RFHM" SG_ 2654339137 EOL_FD09_RFHM 0;
BA_ "GenSigTimeoutTime_MPAD" SG_ 2654339137 EOL_FD09_RFHM 0;
BA_ "GenSigTimeoutTime_IPC" SG_ 2654339137 EOL_FD09_RFHM 0;
BA_ "GenSigTimeoutTime_GNMM" SG_ 2654339137 EOL_FD09_RFHM 0;
BA_ "GenSigTimeoutTime_EVCU2" SG_ 2654339137 EOL_FD09_RFHM 0;
BA_ "GenSigTimeoutTime_ESL" SG_ 2654339137 EOL_FD09_RFHM 0;
BA_ "GenSigTimeoutTime_ECM" SG_ 2654339137 EOL_FD09_RFHM 0;
BA_ "GenSigTimeoutTime_DTCM" SG_ 2654339137 EOL_FD09_RFHM 0;
BA_ "GenSigTimeoutTime_DMSM" SG_ 2654339137 EOL_FD09_RFHM 0;
BA_ "GenSigTimeoutTime_BSM" SG_ 2654339137 EOL_FD09_RFHM 0;
BA_ "GenSigTimeoutTime_BCM" SG_ 2654339137 EOL_FD09_RFHM 0;
BA_ "GenSigTimeoutTime_AGSM" SG_ 2654339137 EOL_FD09_RFHM 0;
BA_ "GenSigTimeoutTime_ADCAM" SG_ 2654339137 EOL_FD09_RFHM 0;
BA_ "GenSigTimeoutTime_RFHM" SG_ 2654339137 DES_FD09_RFHM 0;
BA_ "GenSigTimeoutTime_MPAD" SG_ 2654339137 DES_FD09_RFHM 0;
BA_ "GenSigTimeoutTime_IPC" SG_ 2654339137 DES_FD09_RFHM 0;
BA_ "GenSigTimeoutTime_GNMM" SG_ 2654339137 DES_FD09_RFHM 0;
BA_ "GenSigTimeoutTime_EVCU2" SG_ 2654339137 DES_FD09_RFHM 0;
BA_ "GenSigTimeoutTime_ESL" SG_ 2654339137 DES_FD09_RFHM 0;
BA_ "GenSigTimeoutTime_ECM" SG_ 2654339137 DES_FD09_RFHM 0;
BA_ "GenSigTimeoutTime_DTCM" SG_ 2654339137 DES_FD09_RFHM 0;
BA_ "GenSigTimeoutTime_DMSM" SG_ 2654339137 DES_FD09_RFHM 0;
BA_ "GenSigTimeoutTime_BSM" SG_ 2654339137 DES_FD09_RFHM 0;
BA_ "GenSigTimeoutTime_BCM" SG_ 2654339137 DES_FD09_RFHM 0;
BA_ "GenSigTimeoutTime_AGSM" SG_ 2654339137 DES_FD09_RFHM 0;
BA_ "GenSigTimeoutTime_ADCAM" SG_ 2654339137 DES_FD09_RFHM 0;
BA_ "GenSigTimeoutTime_RFHM" SG_ 2654339137 CurrentFailSts_FD09_RFHM 0;
BA_ "GenSigTimeoutTime_MPAD" SG_ 2654339137 CurrentFailSts_FD09_RFHM 0;
BA_ "GenSigTimeoutTime_IPC" SG_ 2654339137 CurrentFailSts_FD09_RFHM 0;
BA_ "GenSigTimeoutTime_GNMM" SG_ 2654339137 CurrentFailSts_FD09_RFHM 0;
BA_ "GenSigTimeoutTime_EVCU2" SG_ 2654339137 CurrentFailSts_FD09_RFHM 0;
BA_ "GenSigTimeoutTime_ESL" SG_ 2654339137 CurrentFailSts_FD09_RFHM 0;
BA_ "GenSigTimeoutTime_ECM" SG_ 2654339137 CurrentFailSts_FD09_RFHM 0;
BA_ "GenSigTimeoutTime_DTCM" SG_ 2654339137 CurrentFailSts_FD09_RFHM 0;
BA_ "GenSigTimeoutTime_DMSM" SG_ 2654339137 CurrentFailSts_FD09_RFHM 0;
BA_ "GenSigTimeoutTime_BSM" SG_ 2654339137 CurrentFailSts_FD09_RFHM 0;
BA_ "GenSigTimeoutTime_BCM" SG_ 2654339137 CurrentFailSts_FD09_RFHM 0;
BA_ "GenSigTimeoutTime_AGSM" SG_ 2654339137 CurrentFailSts_FD09_RFHM 0;
BA_ "GenSigTimeoutTime_ADCAM" SG_ 2654339137 CurrentFailSts_FD09_RFHM 0;
BA_ "GenSigTimeoutTime_RFHM" SG_ 2654339137 CurrentCanNMState_FD09_RFHM 0;
BA_ "GenSigTimeoutTime_MPAD" SG_ 2654339137 CurrentCanNMState_FD09_RFHM 0;
BA_ "GenSigTimeoutTime_IPC" SG_ 2654339137 CurrentCanNMState_FD09_RFHM 0;
BA_ "GenSigTimeoutTime_GNMM" SG_ 2654339137 CurrentCanNMState_FD09_RFHM 0;
BA_ "GenSigTimeoutTime_EVCU2" SG_ 2654339137 CurrentCanNMState_FD09_RFHM 0;
BA_ "GenSigTimeoutTime_ESL" SG_ 2654339137 CurrentCanNMState_FD09_RFHM 0;
BA_ "GenSigTimeoutTime_ECM" SG_ 2654339137 CurrentCanNMState_FD09_RFHM 0;
BA_ "GenSigTimeoutTime_DTCM" SG_ 2654339137 CurrentCanNMState_FD09_RFHM 0;
BA_ "GenSigTimeoutTime_DMSM" SG_ 2654339137 CurrentCanNMState_FD09_RFHM 0;
BA_ "GenSigTimeoutTime_BSM" SG_ 2654339137 CurrentCanNMState_FD09_RFHM 0;
BA_ "GenSigTimeoutTime_BCM" SG_ 2654339137 CurrentCanNMState_FD09_RFHM 0;
BA_ "GenSigTimeoutTime_AGSM" SG_ 2654339137 CurrentCanNMState_FD09_RFHM 0;
BA_ "GenSigTimeoutTime_ADCAM" SG_ 2654339137 CurrentCanNMState_FD09_RFHM 0;
BA_ "GenSigTimeoutTime_SGW" SG_ 2654339132 WakeupSource_FD11_PBWM 0;
BA_ "GenSigTimeoutTime_RFHM" SG_ 2654339132 WakeupSource_FD11_PBWM 0;
BA_ "GenSigTimeoutTime_MPAD" SG_ 2654339132 WakeupSource_FD11_PBWM 0;
BA_ "GenSigTimeoutTime_IPC" SG_ 2654339132 WakeupSource_FD11_PBWM 0;
BA_ "GenSigTimeoutTime_GNMM" SG_ 2654339132 WakeupSource_FD11_PBWM 0;
BA_ "GenSigTimeoutTime_EVCU2" SG_ 2654339132 WakeupSource_FD11_PBWM 0;
BA_ "GenSigTimeoutTime_ESL" SG_ 2654339132 WakeupSource_FD11_PBWM 0;
BA_ "GenSigTimeoutTime_ECM" SG_ 2654339132 WakeupSource_FD11_PBWM 0;
BA_ "GenSigTimeoutTime_DTCM" SG_ 2654339132 WakeupSource_FD11_PBWM 0;
BA_ "GenSigTimeoutTime_DMSM" SG_ 2654339132 WakeupSource_FD11_PBWM 0;
BA_ "GenSigTimeoutTime_BSM" SG_ 2654339132 WakeupSource_FD11_PBWM 0;
BA_ "GenSigTimeoutTime_BCM" SG_ 2654339132 WakeupSource_FD11_PBWM 0;
BA_ "GenSigTimeoutTime_AGSM" SG_ 2654339132 WakeupSource_FD11_PBWM 0;
BA_ "GenSigTimeoutTime_ADCAM" SG_ 2654339132 WakeupSource_FD11_PBWM 0;
BA_ "GenSigTimeoutTime_SGW" SG_ 2654339132 WakeupSource_FD05_PBWM 0;
BA_ "GenSigTimeoutTime_RFHM" SG_ 2654339132 WakeupSource_FD05_PBWM 0;
BA_ "GenSigTimeoutTime_MPAD" SG_ 2654339132 WakeupSource_FD05_PBWM 0;
BA_ "GenSigTimeoutTime_IPC" SG_ 2654339132 WakeupSource_FD05_PBWM 0;
BA_ "GenSigTimeoutTime_GNMM" SG_ 2654339132 WakeupSource_FD05_PBWM 0;
BA_ "GenSigTimeoutTime_EVCU2" SG_ 2654339132 WakeupSource_FD05_PBWM 0;
BA_ "GenSigTimeoutTime_ESL" SG_ 2654339132 WakeupSource_FD05_PBWM 0;
BA_ "GenSigTimeoutTime_ECM" SG_ 2654339132 WakeupSource_FD05_PBWM 0;
BA_ "GenSigTimeoutTime_DTCM" SG_ 2654339132 WakeupSource_FD05_PBWM 0;
BA_ "GenSigTimeoutTime_DMSM" SG_ 2654339132 WakeupSource_FD05_PBWM 0;
BA_ "GenSigTimeoutTime_BSM" SG_ 2654339132 WakeupSource_FD05_PBWM 0;
BA_ "GenSigTimeoutTime_BCM" SG_ 2654339132 WakeupSource_FD05_PBWM 0;
BA_ "GenSigTimeoutTime_AGSM" SG_ 2654339132 WakeupSource_FD05_PBWM 0;
BA_ "GenSigTimeoutTime_ADCAM" SG_ 2654339132 WakeupSource_FD05_PBWM 0;
BA_ "GenSigTimeoutTime_SGW" SG_ 2654339132 StayActiveSource_FD11_PBWM 0;
BA_ "GenSigTimeoutTime_RFHM" SG_ 2654339132 StayActiveSource_FD11_PBWM 0;
BA_ "GenSigTimeoutTime_MPAD" SG_ 2654339132 StayActiveSource_FD11_PBWM 0;
BA_ "GenSigTimeoutTime_IPC" SG_ 2654339132 StayActiveSource_FD11_PBWM 0;
BA_ "GenSigTimeoutTime_GNMM" SG_ 2654339132 StayActiveSource_FD11_PBWM 0;
BA_ "GenSigTimeoutTime_EVCU2" SG_ 2654339132 StayActiveSource_FD11_PBWM 0;
BA_ "GenSigTimeoutTime_ESL" SG_ 2654339132 StayActiveSource_FD11_PBWM 0;
BA_ "GenSigTimeoutTime_ECM" SG_ 2654339132 StayActiveSource_FD11_PBWM 0;
BA_ "GenSigTimeoutTime_DTCM" SG_ 2654339132 StayActiveSource_FD11_PBWM 0;
BA_ "GenSigTimeoutTime_DMSM" SG_ 2654339132 StayActiveSource_FD11_PBWM 0;
BA_ "GenSigTimeoutTime_BSM" SG_ 2654339132 StayActiveSource_FD11_PBWM 0;
BA_ "GenSigTimeoutTime_BCM" SG_ 2654339132 StayActiveSource_FD11_PBWM 0;
BA_ "GenSigTimeoutTime_AGSM" SG_ 2654339132 StayActiveSource_FD11_PBWM 0;
BA_ "GenSigTimeoutTime_ADCAM" SG_ 2654339132 StayActiveSource_FD11_PBWM 0;
BA_ "GenSigTimeoutTime_GNMM" SG_ 2654339132 StayActiveSource_FD05_PBWM 0;
BA_ "GenSigTimeoutTime_EVCU2" SG_ 2654339132 StayActiveSource_FD05_PBWM 0;
BA_ "GenSigTimeoutTime_ESL" SG_ 2654339132 StayActiveSource_FD05_PBWM 0;
BA_ "GenSigTimeoutTime_ECM" SG_ 2654339132 StayActiveSource_FD05_PBWM 0;
BA_ "GenSigTimeoutTime_DTCM" SG_ 2654339132 StayActiveSource_FD05_PBWM 0;
BA_ "GenSigTimeoutTime_DMSM" SG_ 2654339132 StayActiveSource_FD05_PBWM 0;
BA_ "GenSigTimeoutTime_BSM" SG_ 2654339132 StayActiveSource_FD05_PBWM 0;
BA_ "GenSigTimeoutTime_BCM" SG_ 2654339132 StayActiveSource_FD05_PBWM 0;
BA_ "GenSigTimeoutTime_AGSM" SG_ 2654339132 StayActiveSource_FD05_PBWM 0;
BA_ "GenSigTimeoutTime_ADCAM" SG_ 2654339132 StayActiveSource_FD05_PBWM 0;
BA_ "GenSigTimeoutTime_SGW" SG_ 2654339132 StayActiveSource_FD05_PBWM 0;
BA_ "GenSigTimeoutTime_RFHM" SG_ 2654339132 StayActiveSource_FD05_PBWM 0;
BA_ "GenSigTimeoutTime_MPAD" SG_ 2654339132 StayActiveSource_FD05_PBWM 0;
BA_ "GenSigTimeoutTime_IPC" SG_ 2654339132 StayActiveSource_FD05_PBWM 0;
BA_ "GenSigTimeoutTime_SGW" SG_ 2654339132 PreviousCanNMState_FD11_PBWM 0;
BA_ "GenSigTimeoutTime_RFHM" SG_ 2654339132 PreviousCanNMState_FD11_PBWM 0;
BA_ "GenSigTimeoutTime_MPAD" SG_ 2654339132 PreviousCanNMState_FD11_PBWM 0;
BA_ "GenSigTimeoutTime_IPC" SG_ 2654339132 PreviousCanNMState_FD11_PBWM 0;
BA_ "GenSigTimeoutTime_GNMM" SG_ 2654339132 PreviousCanNMState_FD11_PBWM 0;
BA_ "GenSigTimeoutTime_EVCU2" SG_ 2654339132 PreviousCanNMState_FD11_PBWM 0;
BA_ "GenSigTimeoutTime_ESL" SG_ 2654339132 PreviousCanNMState_FD11_PBWM 0;
BA_ "GenSigTimeoutTime_ECM" SG_ 2654339132 PreviousCanNMState_FD11_PBWM 0;
BA_ "GenSigTimeoutTime_DTCM" SG_ 2654339132 PreviousCanNMState_FD11_PBWM 0;
BA_ "GenSigTimeoutTime_DMSM" SG_ 2654339132 PreviousCanNMState_FD11_PBWM 0;
BA_ "GenSigTimeoutTime_BSM" SG_ 2654339132 PreviousCanNMState_FD11_PBWM 0;
BA_ "GenSigTimeoutTime_BCM" SG_ 2654339132 PreviousCanNMState_FD11_PBWM 0;
BA_ "GenSigTimeoutTime_AGSM" SG_ 2654339132 PreviousCanNMState_FD11_PBWM 0;
BA_ "GenSigTimeoutTime_ADCAM" SG_ 2654339132 PreviousCanNMState_FD11_PBWM 0;
BA_ "GenSigTimeoutTime_SGW" SG_ 2654339132 PreviousCanNMState_FD05_PBWM 0;
BA_ "GenSigTimeoutTime_RFHM" SG_ 2654339132 PreviousCanNMState_FD05_PBWM 0;
BA_ "GenSigTimeoutTime_MPAD" SG_ 2654339132 PreviousCanNMState_FD05_PBWM 0;
BA_ "GenSigTimeoutTime_IPC" SG_ 2654339132 PreviousCanNMState_FD05_PBWM 0;
BA_ "GenSigTimeoutTime_GNMM" SG_ 2654339132 PreviousCanNMState_FD05_PBWM 0;
BA_ "GenSigTimeoutTime_EVCU2" SG_ 2654339132 PreviousCanNMState_FD05_PBWM 0;
BA_ "GenSigTimeoutTime_ESL" SG_ 2654339132 PreviousCanNMState_FD05_PBWM 0;
BA_ "GenSigTimeoutTime_ECM" SG_ 2654339132 PreviousCanNMState_FD05_PBWM 0;
BA_ "GenSigTimeoutTime_DTCM" SG_ 2654339132 PreviousCanNMState_FD05_PBWM 0;
BA_ "GenSigTimeoutTime_DMSM" SG_ 2654339132 PreviousCanNMState_FD05_PBWM 0;
BA_ "GenSigTimeoutTime_RFHM" SG_ 2654339137 DES_FD03_RFHM 0;
BA_ "GenSigTimeoutTime_MPAD" SG_ 2654339137 DES_FD03_RFHM 0;
BA_ "GenSigTimeoutTime_IPC" SG_ 2654339137 DES_FD03_RFHM 0;
BA_ "GenSigTimeoutTime_GNMM" SG_ 2654339137 DES_FD03_RFHM 0;
BA_ "GenSigTimeoutTime_EVCU2" SG_ 2654339137 DES_FD03_RFHM 0;
BA_ "GenSigTimeoutTime_ESL" SG_ 2654339137 DES_FD03_RFHM 0;
BA_ "GenSigTimeoutTime_ECM" SG_ 2654339137 DES_FD03_RFHM 0;
BA_ "GenSigTimeoutTime_DTCM" SG_ 2654339137 DES_FD03_RFHM 0;
BA_ "GenSigTimeoutTime_DMSM" SG_ 2654339137 DES_FD03_RFHM 0;
BA_ "GenSigTimeoutTime_BSM" SG_ 2654339137 DES_FD03_RFHM 0;
BA_ "GenSigTimeoutTime_BCM" SG_ 2654339137 DES_FD03_RFHM 0;
BA_ "GenSigTimeoutTime_AGSM" SG_ 2654339137 DES_FD03_RFHM 0;
BA_ "GenSigTimeoutTime_ADCAM" SG_ 2654339137 DES_FD03_RFHM 0;
BA_ "GenSigTimeoutTime_RFHM" SG_ 2654339137 CurrentCanNMState_FD03_RFHM 0;
BA_ "GenSigTimeoutTime_MPAD" SG_ 2654339137 CurrentCanNMState_FD03_RFHM 0;
BA_ "GenSigTimeoutTime_IPC" SG_ 2654339137 CurrentCanNMState_FD03_RFHM 0;
BA_ "GenSigTimeoutTime_GNMM" SG_ 2654339137 CurrentCanNMState_FD03_RFHM 0;
BA_ "GenSigTimeoutTime_EVCU2" SG_ 2654339137 CurrentCanNMState_FD03_RFHM 0;
BA_ "GenSigTimeoutTime_ESL" SG_ 2654339137 CurrentCanNMState_FD03_RFHM 0;
BA_ "GenSigTimeoutTime_ECM" SG_ 2654339137 CurrentCanNMState_FD03_RFHM 0;
BA_ "GenSigTimeoutTime_DTCM" SG_ 2654339137 CurrentCanNMState_FD03_RFHM 0;
BA_ "GenSigTimeoutTime_DMSM" SG_ 2654339137 CurrentCanNMState_FD03_RFHM 0;
BA_ "GenSigTimeoutTime_BSM" SG_ 2654339137 CurrentCanNMState_FD03_RFHM 0;
BA_ "GenSigTimeoutTime_BCM" SG_ 2654339137 CurrentCanNMState_FD03_RFHM 0;
BA_ "GenSigTimeoutTime_AGSM" SG_ 2654339137 CurrentCanNMState_FD03_RFHM 0;
BA_ "GenSigTimeoutTime_ADCAM" SG_ 2654339137 CurrentCanNMState_FD03_RFHM 0;
BA_ "GenSigTimeoutTime_BSM" SG_ 2654339132 PreviousCanNMState_FD05_PBWM 0;
BA_ "GenSigTimeoutTime_RFHM" SG_ 1044 TransTemp_Display 0;
BA_ "GenSigTimeoutTime_MPAD" SG_ 1044 TransTemp_Display 0;
BA_ "GenSigTimeoutTime_GNMM" SG_ 1044 TransTemp_Display 0;
BA_ "GenSigTimeoutTime_EVCU2" SG_ 1044 TransTemp_Display 0;
BA_ "GenSigTimeoutTime_ESL" SG_ 1044 TransTemp_Display 0;
BA_ "GenSigTimeoutTime_ECM" SG_ 1044 TransTemp_Display 0;
BA_ "GenSigTimeoutTime_DTCM" SG_ 1044 TransTemp_Display 0;
BA_ "GenSigTimeoutTime_DMSM" SG_ 1044 TransTemp_Display 0;
BA_ "GenSigTimeoutTime_BSM" SG_ 1044 TransTemp_Display 0;
BA_ "GenSigTimeoutTime_BCM" SG_ 1044 TransTemp_Display 0;
BA_ "GenSigTimeoutTime_AGSM" SG_ 1044 TransTemp_Display 0;
BA_ "GenSigTimeoutTime_ADCAM" SG_ 1044 TransTemp_Display 0;
BA_ "GenSigStartValue" SG_ 1044 TransTemp_Display 40;
BA_ "GenSigTimeoutTime_RFHM" SG_ 1044 RI_LIGHTS_Range 0;
BA_ "GenSigTimeoutTime_MPAD" SG_ 1044 RI_LIGHTS_Range 0;
BA_ "GenSigTimeoutTime_IPC" SG_ 1044 RI_LIGHTS_Range 0;
BA_ "GenSigTimeoutTime_GNMM" SG_ 1044 RI_LIGHTS_Range 0;
BA_ "GenSigTimeoutTime_EVCU2" SG_ 1044 RI_LIGHTS_Range 0;
BA_ "GenSigTimeoutTime_ESL" SG_ 1044 RI_LIGHTS_Range 0;
BA_ "GenSigTimeoutTime_ECM" SG_ 1044 RI_LIGHTS_Range 0;
BA_ "GenSigTimeoutTime_DTCM" SG_ 1044 RI_LIGHTS_Range 0;
BA_ "GenSigTimeoutTime_DMSM" SG_ 1044 RI_LIGHTS_Range 0;
BA_ "GenSigTimeoutTime_BSM" SG_ 1044 RI_LIGHTS_Range 0;
BA_ "GenSigTimeoutTime_BCM" SG_ 1044 RI_LIGHTS_Range 0;
BA_ "GenSigTimeoutTime_AGSM" SG_ 1044 RI_LIGHTS_Range 0;
BA_ "GenSigTimeoutTime_ADCAM" SG_ 1044 RI_LIGHTS_Range 0;
BA_ "GenSigTimeoutTime_RFHM" SG_ 1044 RI_OTHER_Range 0;
BA_ "GenSigTimeoutTime_MPAD" SG_ 1044 RI_OTHER_Range 0;
BA_ "GenSigTimeoutTime_IPC" SG_ 1044 RI_OTHER_Range 0;
BA_ "GenSigTimeoutTime_GNMM" SG_ 1044 RI_OTHER_Range 0;
BA_ "GenSigTimeoutTime_EVCU2" SG_ 1044 RI_OTHER_Range 0;
BA_ "GenSigTimeoutTime_ESL" SG_ 1044 RI_OTHER_Range 0;
BA_ "GenSigTimeoutTime_ECM" SG_ 1044 RI_OTHER_Range 0;
BA_ "GenSigTimeoutTime_DTCM" SG_ 1044 RI_OTHER_Range 0;
BA_ "GenSigTimeoutTime_DMSM" SG_ 1044 RI_OTHER_Range 0;
BA_ "GenSigTimeoutTime_BSM" SG_ 1044 RI_OTHER_Range 0;
BA_ "GenSigTimeoutTime_BCM" SG_ 1044 RI_OTHER_Range 0;
BA_ "GenSigTimeoutTime_AGSM" SG_ 1044 RI_OTHER_Range 0;
BA_ "GenSigTimeoutTime_ADCAM" SG_ 1044 RI_OTHER_Range 0;
BA_ "GenSigTimeoutTime_RFHM" SG_ 1044 RI_SEATSWHL_Range 0;
BA_ "GenSigTimeoutTime_MPAD" SG_ 1044 RI_SEATSWHL_Range 0;
BA_ "GenSigTimeoutTime_IPC" SG_ 1044 RI_SEATSWHL_Range 0;
BA_ "GenSigTimeoutTime_GNMM" SG_ 1044 RI_SEATSWHL_Range 0;
BA_ "GenSigTimeoutTime_EVCU2" SG_ 1044 RI_SEATSWHL_Range 0;
BA_ "GenSigTimeoutTime_ESL" SG_ 1044 RI_SEATSWHL_Range 0;
BA_ "GenSigTimeoutTime_ECM" SG_ 1044 RI_SEATSWHL_Range 0;
BA_ "GenSigTimeoutTime_DTCM" SG_ 1044 RI_SEATSWHL_Range 0;
BA_ "GenSigTimeoutTime_DMSM" SG_ 1044 RI_SEATSWHL_Range 0;
BA_ "GenSigTimeoutTime_BSM" SG_ 1044 RI_SEATSWHL_Range 0;
BA_ "GenSigTimeoutTime_BCM" SG_ 1044 RI_SEATSWHL_Range 0;
BA_ "GenSigTimeoutTime_AGSM" SG_ 1044 RI_SEATSWHL_Range 0;
BA_ "GenSigTimeoutTime_ADCAM" SG_ 1044 RI_SEATSWHL_Range 0;
BA_ "GenSigTimeoutTime_RFHM" SG_ 1044 RI_TOTAL_Range_Add 0;
BA_ "GenSigTimeoutTime_MPAD" SG_ 1044 RI_TOTAL_Range_Add 0;
BA_ "GenSigTimeoutTime_IPC" SG_ 1044 RI_TOTAL_Range_Add 0;
BA_ "GenSigTimeoutTime_GNMM" SG_ 1044 RI_TOTAL_Range_Add 0;
BA_ "GenSigTimeoutTime_EVCU2" SG_ 1044 RI_TOTAL_Range_Add 0;
BA_ "GenSigTimeoutTime_ESL" SG_ 1044 RI_TOTAL_Range_Add 0;
BA_ "GenSigTimeoutTime_ECM" SG_ 1044 RI_TOTAL_Range_Add 0;
BA_ "GenSigTimeoutTime_DTCM" SG_ 1044 RI_TOTAL_Range_Add 0;
BA_ "GenSigTimeoutTime_DMSM" SG_ 1044 RI_TOTAL_Range_Add 0;
BA_ "GenSigTimeoutTime_BSM" SG_ 1044 RI_TOTAL_Range_Add 0;
BA_ "GenSigTimeoutTime_BCM" SG_ 1044 RI_TOTAL_Range_Add 0;
BA_ "GenSigTimeoutTime_AGSM" SG_ 1044 RI_TOTAL_Range_Add 0;
BA_ "GenSigTimeoutTime_ADCAM" SG_ 1044 RI_TOTAL_Range_Add 0;
BA_ "GenSigTimeoutTime_RFHM" SG_ 1044 APCM_Rq_Display 0;
BA_ "GenSigTimeoutTime_MPAD" SG_ 1044 APCM_Rq_Display 0;
BA_ "GenSigTimeoutTime_IPC" SG_ 1044 APCM_Rq_Display 0;
BA_ "GenSigTimeoutTime_GNMM" SG_ 1044 APCM_Rq_Display 0;
BA_ "GenSigTimeoutTime_EVCU2" SG_ 1044 APCM_Rq_Display 0;
BA_ "GenSigTimeoutTime_ESL" SG_ 1044 APCM_Rq_Display 0;
BA_ "GenSigTimeoutTime_ECM" SG_ 1044 APCM_Rq_Display 0;
BA_ "GenSigTimeoutTime_DTCM" SG_ 1044 APCM_Rq_Display 0;
BA_ "GenSigTimeoutTime_DMSM" SG_ 1044 APCM_Rq_Display 0;
BA_ "GenSigTimeoutTime_BSM" SG_ 1044 APCM_Rq_Display 0;
BA_ "GenSigTimeoutTime_BCM" SG_ 1044 APCM_Rq_Display 0;
BA_ "GenSigTimeoutTime_AGSM" SG_ 1044 APCM_Rq_Display 0;
BA_ "GenSigTimeoutTime_ADCAM" SG_ 1044 APCM_Rq_Display 0;
BA_ "GenSigTimeoutTime_SGW" SG_ 1044 HVBatteryMILRq 0;
BA_ "GenSigTimeoutTime_RFHM" SG_ 1044 HVBatteryMILRq 0;
BA_ "GenSigTimeoutTime_MPAD" SG_ 1044 HVBatteryMILRq 0;
BA_ "GenSigTimeoutTime_GNMM" SG_ 1044 HVBatteryMILRq 0;
BA_ "GenSigTimeoutTime_EVCU2" SG_ 1044 HVBatteryMILRq 0;
BA_ "GenSigTimeoutTime_ESL" SG_ 1044 HVBatteryMILRq 0;
BA_ "GenSigTimeoutTime_ECM" SG_ 1044 HVBatteryMILRq 0;
BA_ "GenSigTimeoutTime_DTCM" SG_ 1044 HVBatteryMILRq 0;
BA_ "GenSigTimeoutTime_DMSM" SG_ 1044 HVBatteryMILRq 0;
BA_ "GenSigTimeoutTime_BSM" SG_ 1044 HVBatteryMILRq 0;
BA_ "GenSigTimeoutTime_BCM" SG_ 1044 HVBatteryMILRq 0;
BA_ "GenSigTimeoutTime_AGSM" SG_ 1044 HVBatteryMILRq 0;
BA_ "GenSigTimeoutTime_ADCAM" SG_ 1044 HVBatteryMILRq 0;
BA_ "GenSigTimeoutTime_RFHM" SG_ 1044 PnC_Failure 0;
BA_ "GenSigTimeoutTime_MPAD" SG_ 1044 PnC_Failure 0;
BA_ "GenSigTimeoutTime_GNMM" SG_ 1044 PnC_Failure 0;
BA_ "GenSigTimeoutTime_EVCU2" SG_ 1044 PnC_Failure 0;
BA_ "GenSigTimeoutTime_ESL" SG_ 1044 PnC_Failure 0;
BA_ "GenSigTimeoutTime_ECM" SG_ 1044 PnC_Failure 0;
BA_ "GenSigTimeoutTime_DTCM" SG_ 1044 PnC_Failure 0;
BA_ "GenSigTimeoutTime_DMSM" SG_ 1044 PnC_Failure 0;
BA_ "GenSigTimeoutTime_BSM" SG_ 1044 PnC_Failure 0;
BA_ "GenSigTimeoutTime_BCM" SG_ 1044 PnC_Failure 0;
BA_ "GenSigTimeoutTime_AGSM" SG_ 1044 PnC_Failure 0;
BA_ "GenSigTimeoutTime_ADCAM" SG_ 1044 PnC_Failure 0;
BA_ "GenSigTimeoutTime_SGW" SG_ 1044 PnC_Reattepmt_Failure 0;
BA_ "GenSigTimeoutTime_RFHM" SG_ 1044 PnC_Reattepmt_Failure 0;
BA_ "GenSigTimeoutTime_MPAD" SG_ 1044 PnC_Reattepmt_Failure 0;
BA_ "GenSigTimeoutTime_GNMM" SG_ 1044 PnC_Reattepmt_Failure 0;
BA_ "GenSigTimeoutTime_EVCU2" SG_ 1044 PnC_Reattepmt_Failure 0;
BA_ "GenSigTimeoutTime_ESL" SG_ 1044 PnC_Reattepmt_Failure 0;
BA_ "GenSigTimeoutTime_ECM" SG_ 1044 PnC_Reattepmt_Failure 0;
BA_ "GenSigTimeoutTime_DTCM" SG_ 1044 PnC_Reattepmt_Failure 0;
BA_ "GenSigTimeoutTime_DMSM" SG_ 1044 PnC_Reattepmt_Failure 0;
BA_ "GenSigTimeoutTime_BSM" SG_ 1044 PnC_Reattepmt_Failure 0;
BA_ "GenSigTimeoutTime_BCM" SG_ 1044 PnC_Reattepmt_Failure 0;
BA_ "GenSigTimeoutTime_AGSM" SG_ 1044 PnC_Reattepmt_Failure 0;
BA_ "GenSigTimeoutTime_ADCAM" SG_ 1044 PnC_Reattepmt_Failure 0;
BA_ "GenSigTimeoutTime_RFHM" SG_ 1044 RI_AC_FAN_Range 0;
BA_ "GenSigTimeoutTime_MPAD" SG_ 1044 RI_AC_FAN_Range 0;
BA_ "GenSigTimeoutTime_IPC" SG_ 1044 RI_AC_FAN_Range 0;
BA_ "GenSigTimeoutTime_GNMM" SG_ 1044 RI_AC_FAN_Range 0;
BA_ "GenSigTimeoutTime_EVCU2" SG_ 1044 RI_AC_FAN_Range 0;
BA_ "GenSigTimeoutTime_ESL" SG_ 1044 RI_AC_FAN_Range 0;
BA_ "GenSigTimeoutTime_ECM" SG_ 1044 RI_AC_FAN_Range 0;
BA_ "GenSigTimeoutTime_DTCM" SG_ 1044 RI_AC_FAN_Range 0;
BA_ "GenSigTimeoutTime_DMSM" SG_ 1044 RI_AC_FAN_Range 0;
BA_ "GenSigTimeoutTime_BSM" SG_ 1044 RI_AC_FAN_Range 0;
BA_ "GenSigTimeoutTime_BCM" SG_ 1044 RI_AC_FAN_Range 0;
BA_ "GenSigTimeoutTime_AGSM" SG_ 1044 RI_AC_FAN_Range 0;
BA_ "GenSigTimeoutTime_ADCAM" SG_ 1044 RI_AC_FAN_Range 0;
BA_ "GenSigTimeoutTime_RFHM" SG_ 1044 RI_AUDIO_Range 0;
BA_ "GenSigTimeoutTime_MPAD" SG_ 1044 RI_AUDIO_Range 0;
BA_ "GenSigTimeoutTime_IPC" SG_ 1044 RI_AUDIO_Range 0;
BA_ "GenSigTimeoutTime_GNMM" SG_ 1044 RI_AUDIO_Range 0;
BA_ "GenSigTimeoutTime_EVCU2" SG_ 1044 RI_AUDIO_Range 0;
BA_ "GenSigTimeoutTime_ESL" SG_ 1044 RI_AUDIO_Range 0;
BA_ "GenSigTimeoutTime_ECM" SG_ 1044 RI_AUDIO_Range 0;
BA_ "GenSigTimeoutTime_DTCM" SG_ 1044 RI_AUDIO_Range 0;
BA_ "GenSigTimeoutTime_DMSM" SG_ 1044 RI_AUDIO_Range 0;
BA_ "GenSigTimeoutTime_BSM" SG_ 1044 RI_AUDIO_Range 0;
BA_ "GenSigTimeoutTime_BCM" SG_ 1044 RI_AUDIO_Range 0;
BA_ "GenSigTimeoutTime_AGSM" SG_ 1044 RI_AUDIO_Range 0;
BA_ "GenSigTimeoutTime_ADCAM" SG_ 1044 RI_AUDIO_Range 0;
BA_ "GenSigTimeoutTime_RFHM" SG_ 1044 RI_DEFROST_Range 0;
BA_ "GenSigTimeoutTime_MPAD" SG_ 1044 RI_DEFROST_Range 0;
BA_ "GenSigTimeoutTime_IPC" SG_ 1044 RI_DEFROST_Range 0;
BA_ "GenSigTimeoutTime_GNMM" SG_ 1044 RI_DEFROST_Range 0;
BA_ "GenSigTimeoutTime_EVCU2" SG_ 1044 RI_DEFROST_Range 0;
BA_ "GenSigTimeoutTime_ESL" SG_ 1044 RI_DEFROST_Range 0;
BA_ "GenSigTimeoutTime_ECM" SG_ 1044 RI_DEFROST_Range 0;
BA_ "GenSigTimeoutTime_DTCM" SG_ 1044 RI_DEFROST_Range 0;
BA_ "GenSigTimeoutTime_DMSM" SG_ 1044 RI_DEFROST_Range 0;
BA_ "GenSigTimeoutTime_BSM" SG_ 1044 RI_DEFROST_Range 0;
BA_ "GenSigTimeoutTime_BCM" SG_ 1044 RI_DEFROST_Range 0;
BA_ "GenSigTimeoutTime_AGSM" SG_ 1044 RI_DEFROST_Range 0;
BA_ "GenSigTimeoutTime_ADCAM" SG_ 1044 RI_DEFROST_Range 0;
BA_ "GenSigTimeoutTime_ADCAM" SG_ 2654339197 DES_FD11_IDCM 0;
BA_ "GenSigTimeoutTime_RFHM" SG_ 2654339197 DES_FD11_IDCM 0;
BA_ "GenSigTimeoutTime_MPAD" SG_ 2654339197 DES_FD11_IDCM 0;
BA_ "GenSigTimeoutTime_IPC" SG_ 2654339197 DES_FD11_IDCM 0;
BA_ "GenSigTimeoutTime_GNMM" SG_ 2654339197 DES_FD11_IDCM 0;
BA_ "GenSigTimeoutTime_EVCU2" SG_ 2654339197 DES_FD11_IDCM 0;
BA_ "GenSigTimeoutTime_ESL" SG_ 2654339197 DES_FD11_IDCM 0;
BA_ "GenSigTimeoutTime_ECM" SG_ 2654339197 DES_FD11_IDCM 0;
BA_ "GenSigTimeoutTime_DTCM" SG_ 2654339197 DES_FD11_IDCM 0;
BA_ "GenSigTimeoutTime_DMSM" SG_ 2654339197 DES_FD11_IDCM 0;
BA_ "GenSigTimeoutTime_BSM" SG_ 2654339197 DES_FD11_IDCM 0;
BA_ "GenSigTimeoutTime_BCM" SG_ 2654339197 DES_FD11_IDCM 0;
BA_ "GenSigTimeoutTime_AGSM" SG_ 2654339197 DES_FD11_IDCM 0;
BA_ "GenSigTimeoutTime_RFHM" SG_ 2654339197 DES_FD05_IDCM 0;
BA_ "GenSigTimeoutTime_MPAD" SG_ 2654339197 DES_FD05_IDCM 0;
BA_ "GenSigTimeoutTime_IPC" SG_ 2654339197 DES_FD05_IDCM 0;
BA_ "GenSigTimeoutTime_GNMM" SG_ 2654339197 DES_FD05_IDCM 0;
BA_ "GenSigTimeoutTime_EVCU2" SG_ 2654339197 DES_FD05_IDCM 0;
BA_ "GenSigTimeoutTime_ESL" SG_ 2654339197 DES_FD05_IDCM 0;
BA_ "GenSigTimeoutTime_ECM" SG_ 2654339197 DES_FD05_IDCM 0;
BA_ "GenSigTimeoutTime_DTCM" SG_ 2654339197 DES_FD05_IDCM 0;
BA_ "GenSigTimeoutTime_DMSM" SG_ 2654339197 DES_FD05_IDCM 0;
BA_ "GenSigTimeoutTime_BSM" SG_ 2654339197 DES_FD05_IDCM 0;
BA_ "GenSigTimeoutTime_BCM" SG_ 2654339197 DES_FD05_IDCM 0;
BA_ "GenSigTimeoutTime_AGSM" SG_ 2654339197 DES_FD05_IDCM 0;
BA_ "GenSigTimeoutTime_ADCAM" SG_ 2654339197 DES_FD05_IDCM 0;
BA_ "GenSigTimeoutTime_RFHM" SG_ 2654339197 CurrentFailSts_FD11_IDCM 0;
BA_ "GenSigTimeoutTime_MPAD" SG_ 2654339197 CurrentFailSts_FD11_IDCM 0;
BA_ "GenSigTimeoutTime_IPC" SG_ 2654339197 CurrentFailSts_FD11_IDCM 0;
BA_ "GenSigTimeoutTime_GNMM" SG_ 2654339197 CurrentFailSts_FD11_IDCM 0;
BA_ "GenSigTimeoutTime_EVCU2" SG_ 2654339197 CurrentFailSts_FD11_IDCM 0;
BA_ "GenSigTimeoutTime_ESL" SG_ 2654339197 CurrentFailSts_FD11_IDCM 0;
BA_ "GenSigTimeoutTime_ECM" SG_ 2654339197 CurrentFailSts_FD11_IDCM 0;
BA_ "GenSigTimeoutTime_DTCM" SG_ 2654339197 CurrentFailSts_FD11_IDCM 0;
BA_ "GenSigTimeoutTime_RFHM" SG_ 2654339197 WakeupSource_FD05_IDCM 0;
BA_ "GenSigTimeoutTime_MPAD" SG_ 2654339197 WakeupSource_FD05_IDCM 0;
BA_ "GenSigTimeoutTime_IPC" SG_ 2654339197 WakeupSource_FD05_IDCM 0;
BA_ "GenSigTimeoutTime_GNMM" SG_ 2654339197 WakeupSource_FD05_IDCM 0;
BA_ "GenSigTimeoutTime_EVCU2" SG_ 2654339197 WakeupSource_FD05_IDCM 0;
BA_ "GenSigTimeoutTime_ESL" SG_ 2654339197 WakeupSource_FD05_IDCM 0;
BA_ "GenSigTimeoutTime_ECM" SG_ 2654339197 WakeupSource_FD05_IDCM 0;
BA_ "GenSigTimeoutTime_DTCM" SG_ 2654339197 WakeupSource_FD05_IDCM 0;
BA_ "GenSigTimeoutTime_DMSM" SG_ 2654339197 WakeupSource_FD05_IDCM 0;
BA_ "GenSigTimeoutTime_BSM" SG_ 2654339197 WakeupSource_FD05_IDCM 0;
BA_ "GenSigTimeoutTime_BCM" SG_ 2654339197 WakeupSource_FD05_IDCM 0;
BA_ "GenSigTimeoutTime_AGSM" SG_ 2654339197 WakeupSource_FD05_IDCM 0;
BA_ "GenSigTimeoutTime_ADCAM" SG_ 2654339197 WakeupSource_FD05_IDCM 0;
BA_ "GenSigTimeoutTime_RFHM" SG_ 2654339197 StayActiveSource_FD11_IDCM 0;
BA_ "GenSigTimeoutTime_MPAD" SG_ 2654339197 StayActiveSource_FD11_IDCM 0;
BA_ "GenSigTimeoutTime_IPC" SG_ 2654339197 StayActiveSource_FD11_IDCM 0;
BA_ "GenSigTimeoutTime_GNMM" SG_ 2654339197 StayActiveSource_FD11_IDCM 0;
BA_ "GenSigTimeoutTime_EVCU2" SG_ 2654339197 StayActiveSource_FD11_IDCM 0;
BA_ "GenSigTimeoutTime_ESL" SG_ 2654339197 StayActiveSource_FD11_IDCM 0;
BA_ "GenSigTimeoutTime_ECM" SG_ 2654339197 StayActiveSource_FD11_IDCM 0;
BA_ "GenSigTimeoutTime_DTCM" SG_ 2654339197 StayActiveSource_FD11_IDCM 0;
BA_ "GenSigTimeoutTime_DMSM" SG_ 2654339197 StayActiveSource_FD11_IDCM 0;
BA_ "GenSigTimeoutTime_BSM" SG_ 2654339197 StayActiveSource_FD11_IDCM 0;
BA_ "GenSigTimeoutTime_BCM" SG_ 2654339197 StayActiveSource_FD11_IDCM 0;
BA_ "GenSigTimeoutTime_AGSM" SG_ 2654339197 StayActiveSource_FD11_IDCM 0;
BA_ "GenSigTimeoutTime_ADCAM" SG_ 2654339197 StayActiveSource_FD11_IDCM 0;
BA_ "GenSigTimeoutTime_RFHM" SG_ 2654339197 StayActiveSource_FD05_IDCM 0;
BA_ "GenSigTimeoutTime_MPAD" SG_ 2654339197 StayActiveSource_FD05_IDCM 0;
BA_ "GenSigTimeoutTime_IPC" SG_ 2654339197 StayActiveSource_FD05_IDCM 0;
BA_ "GenSigTimeoutTime_GNMM" SG_ 2654339197 StayActiveSource_FD05_IDCM 0;
BA_ "GenSigTimeoutTime_EVCU2" SG_ 2654339197 StayActiveSource_FD05_IDCM 0;
BA_ "GenSigTimeoutTime_ESL" SG_ 2654339197 StayActiveSource_FD05_IDCM 0;
BA_ "GenSigTimeoutTime_ECM" SG_ 2654339197 StayActiveSource_FD05_IDCM 0;
BA_ "GenSigTimeoutTime_DTCM" SG_ 2654339197 StayActiveSource_FD05_IDCM 0;
BA_ "GenSigTimeoutTime_DMSM" SG_ 2654339197 StayActiveSource_FD05_IDCM 0;
BA_ "GenSigTimeoutTime_BSM" SG_ 2654339197 StayActiveSource_FD05_IDCM 0;
BA_ "GenSigTimeoutTime_BCM" SG_ 2654339197 StayActiveSource_FD05_IDCM 0;
BA_ "GenSigTimeoutTime_AGSM" SG_ 2654339197 StayActiveSource_FD05_IDCM 0;
BA_ "GenSigTimeoutTime_ADCAM" SG_ 2654339197 StayActiveSource_FD05_IDCM 0;
BA_ "GenSigTimeoutTime_RFHM" SG_ 2654339197 PreviousCanNMState_FD11_IDCM 0;
BA_ "GenSigTimeoutTime_MPAD" SG_ 2654339197 PreviousCanNMState_FD11_IDCM 0;
BA_ "GenSigTimeoutTime_IPC" SG_ 2654339197 PreviousCanNMState_FD11_IDCM 0;
BA_ "GenSigTimeoutTime_GNMM" SG_ 2654339197 PreviousCanNMState_FD11_IDCM 0;
BA_ "GenSigTimeoutTime_EVCU2" SG_ 2654339197 PreviousCanNMState_FD11_IDCM 0;
BA_ "GenSigTimeoutTime_ESL" SG_ 2654339197 PreviousCanNMState_FD11_IDCM 0;
BA_ "GenSigTimeoutTime_ECM" SG_ 2654339197 PreviousCanNMState_FD11_IDCM 0;
BA_ "GenSigTimeoutTime_DTCM" SG_ 2654339197 PreviousCanNMState_FD11_IDCM 0;
BA_ "GenSigTimeoutTime_DMSM" SG_ 2654339197 PreviousCanNMState_FD11_IDCM 0;
BA_ "GenSigTimeoutTime_BSM" SG_ 2654339197 PreviousCanNMState_FD11_IDCM 0;
BA_ "GenSigTimeoutTime_BCM" SG_ 2654339197 PreviousCanNMState_FD11_IDCM 0;
BA_ "GenSigTimeoutTime_AGSM" SG_ 2654339197 PreviousCanNMState_FD11_IDCM 0;
BA_ "GenSigTimeoutTime_ADCAM" SG_ 2654339197 PreviousCanNMState_FD11_IDCM 0;
BA_ "GenSigTimeoutTime_RFHM" SG_ 2654339197 PreviousCanNMState_FD05_IDCM 0;
BA_ "GenSigTimeoutTime_MPAD" SG_ 2654339197 PreviousCanNMState_FD05_IDCM 0;
BA_ "GenSigTimeoutTime_IPC" SG_ 2654339197 PreviousCanNMState_FD05_IDCM 0;
BA_ "GenSigTimeoutTime_GNMM" SG_ 2654339197 PreviousCanNMState_FD05_IDCM 0;
BA_ "GenSigTimeoutTime_EVCU2" SG_ 2654339197 PreviousCanNMState_FD05_IDCM 0;
BA_ "GenSigTimeoutTime_ESL" SG_ 2654339197 PreviousCanNMState_FD05_IDCM 0;
BA_ "GenSigTimeoutTime_ECM" SG_ 2654339197 PreviousCanNMState_FD05_IDCM 0;
BA_ "GenSigTimeoutTime_DTCM" SG_ 2654339197 PreviousCanNMState_FD05_IDCM 0;
BA_ "GenSigTimeoutTime_DMSM" SG_ 2654339197 PreviousCanNMState_FD05_IDCM 0;
BA_ "GenSigTimeoutTime_BSM" SG_ 2654339197 PreviousCanNMState_FD05_IDCM 0;
BA_ "GenSigTimeoutTime_BCM" SG_ 2654339197 PreviousCanNMState_FD05_IDCM 0;
BA_ "GenSigTimeoutTime_AGSM" SG_ 2654339197 PreviousCanNMState_FD05_IDCM 0;
BA_ "GenSigTimeoutTime_ADCAM" SG_ 2654339197 PreviousCanNMState_FD05_IDCM 0;
BA_ "GenSigTimeoutTime_RFHM" SG_ 2654339197 GenericFailSts_FD11_IDCM 0;
BA_ "GenSigTimeoutTime_MPAD" SG_ 2654339197 GenericFailSts_FD11_IDCM 0;
BA_ "GenSigTimeoutTime_IPC" SG_ 2654339197 GenericFailSts_FD11_IDCM 0;
BA_ "GenSigTimeoutTime_GNMM" SG_ 2654339197 GenericFailSts_FD11_IDCM 0;
BA_ "GenSigTimeoutTime_EVCU2" SG_ 2654339197 GenericFailSts_FD11_IDCM 0;
BA_ "GenSigTimeoutTime_ESL" SG_ 2654339197 GenericFailSts_FD11_IDCM 0;
BA_ "GenSigTimeoutTime_ECM" SG_ 2654339197 GenericFailSts_FD11_IDCM 0;
BA_ "GenSigTimeoutTime_DTCM" SG_ 2654339197 GenericFailSts_FD11_IDCM 0;
BA_ "GenSigTimeoutTime_DMSM" SG_ 2654339197 GenericFailSts_FD11_IDCM 0;
BA_ "GenSigTimeoutTime_BSM" SG_ 2654339197 GenericFailSts_FD11_IDCM 0;
BA_ "GenSigTimeoutTime_BCM" SG_ 2654339197 GenericFailSts_FD11_IDCM 0;
BA_ "GenSigTimeoutTime_AGSM" SG_ 2654339197 GenericFailSts_FD11_IDCM 0;
BA_ "GenSigTimeoutTime_ADCAM" SG_ 2654339197 GenericFailSts_FD11_IDCM 0;
BA_ "GenSigTimeoutTime_RFHM" SG_ 2654339197 GenericFailSts_FD05_IDCM 0;
BA_ "GenSigTimeoutTime_MPAD" SG_ 2654339197 GenericFailSts_FD05_IDCM 0;
BA_ "GenSigTimeoutTime_IPC" SG_ 2654339197 GenericFailSts_FD05_IDCM 0;
BA_ "GenSigTimeoutTime_GNMM" SG_ 2654339197 GenericFailSts_FD05_IDCM 0;
BA_ "GenSigTimeoutTime_EVCU2" SG_ 2654339197 GenericFailSts_FD05_IDCM 0;
BA_ "GenSigTimeoutTime_ESL" SG_ 2654339197 GenericFailSts_FD05_IDCM 0;
BA_ "GenSigTimeoutTime_ECM" SG_ 2654339197 GenericFailSts_FD05_IDCM 0;
BA_ "GenSigTimeoutTime_DTCM" SG_ 2654339197 GenericFailSts_FD05_IDCM 0;
BA_ "GenSigTimeoutTime_DMSM" SG_ 2654339197 GenericFailSts_FD05_IDCM 0;
BA_ "GenSigTimeoutTime_BSM" SG_ 2654339197 GenericFailSts_FD05_IDCM 0;
BA_ "GenSigTimeoutTime_AGSM" SG_ 2654339197 GenericFailSts_FD05_IDCM 0;
BA_ "GenSigTimeoutTime_ADCAM" SG_ 2654339197 GenericFailSts_FD05_IDCM 0;
BA_ "GenSigTimeoutTime_RFHM" SG_ 2654339197 EOL_FD05_IDCM 0;
BA_ "GenSigTimeoutTime_MPAD" SG_ 2654339197 EOL_FD05_IDCM 0;
BA_ "GenSigTimeoutTime_IPC" SG_ 2654339197 EOL_FD05_IDCM 0;
BA_ "GenSigTimeoutTime_GNMM" SG_ 2654339197 EOL_FD05_IDCM 0;
BA_ "GenSigTimeoutTime_EVCU2" SG_ 2654339197 EOL_FD05_IDCM 0;
BA_ "GenSigTimeoutTime_ESL" SG_ 2654339197 EOL_FD05_IDCM 0;
BA_ "GenSigTimeoutTime_ECM" SG_ 2654339197 EOL_FD05_IDCM 0;
BA_ "GenSigTimeoutTime_DTCM" SG_ 2654339197 EOL_FD05_IDCM 0;
BA_ "GenSigTimeoutTime_DMSM" SG_ 2654339197 EOL_FD05_IDCM 0;
BA_ "GenSigTimeoutTime_BSM" SG_ 2654339197 EOL_FD05_IDCM 0;
BA_ "GenSigTimeoutTime_AGSM" SG_ 2654339197 EOL_FD05_IDCM 0;
BA_ "GenSigTimeoutTime_ADCAM" SG_ 2654339197 EOL_FD05_IDCM 0;
BA_ "GenSigTimeoutTime_RFHM" SG_ 2654339197 WakeupSource_FD11_IDCM 0;
BA_ "GenSigTimeoutTime_MPAD" SG_ 2654339197 WakeupSource_FD11_IDCM 0;
BA_ "GenSigTimeoutTime_IPC" SG_ 2654339197 WakeupSource_FD11_IDCM 0;
BA_ "GenSigTimeoutTime_GNMM" SG_ 2654339197 WakeupSource_FD11_IDCM 0;
BA_ "GenSigTimeoutTime_EVCU2" SG_ 2654339197 WakeupSource_FD11_IDCM 0;
BA_ "GenSigTimeoutTime_ESL" SG_ 2654339197 WakeupSource_FD11_IDCM 0;
BA_ "GenSigTimeoutTime_ECM" SG_ 2654339197 WakeupSource_FD11_IDCM 0;
BA_ "GenSigTimeoutTime_DTCM" SG_ 2654339197 WakeupSource_FD11_IDCM 0;
BA_ "GenSigTimeoutTime_DMSM" SG_ 2654339197 WakeupSource_FD11_IDCM 0;
BA_ "GenSigTimeoutTime_BSM" SG_ 2654339197 WakeupSource_FD11_IDCM 0;
BA_ "GenSigTimeoutTime_BCM" SG_ 2654339197 WakeupSource_FD11_IDCM 0;
BA_ "GenSigTimeoutTime_AGSM" SG_ 2654339197 WakeupSource_FD11_IDCM 0;
BA_ "GenSigTimeoutTime_ADCAM" SG_ 2654339197 WakeupSource_FD11_IDCM 0;
BA_ "GenSigTimeoutTime_RFHM" SG_ 2654339197 EOL_FD11_IDCM 0;
BA_ "GenSigTimeoutTime_MPAD" SG_ 2654339197 EOL_FD11_IDCM 0;
BA_ "GenSigTimeoutTime_IPC" SG_ 2654339197 EOL_FD11_IDCM 0;
BA_ "GenSigTimeoutTime_GNMM" SG_ 2654339197 EOL_FD11_IDCM 0;
BA_ "GenSigTimeoutTime_EVCU2" SG_ 2654339197 EOL_FD11_IDCM 0;
BA_ "GenSigTimeoutTime_ESL" SG_ 2654339197 EOL_FD11_IDCM 0;
BA_ "GenSigTimeoutTime_ECM" SG_ 2654339197 EOL_FD11_IDCM 0;
BA_ "GenSigTimeoutTime_DTCM" SG_ 2654339197 EOL_FD11_IDCM 0;
BA_ "GenSigTimeoutTime_DMSM" SG_ 2654339197 EOL_FD11_IDCM 0;
BA_ "GenSigTimeoutTime_BSM" SG_ 2654339197 EOL_FD11_IDCM 0;
BA_ "GenSigTimeoutTime_BCM" SG_ 2654339197 EOL_FD11_IDCM 0;
BA_ "GenSigTimeoutTime_AGSM" SG_ 2654339197 EOL_FD11_IDCM 0;
BA_ "GenSigTimeoutTime_ADCAM" SG_ 2654339197 EOL_FD11_IDCM 0;
BA_ "GenSigTimeoutTime_ADCAM" SG_ 2651930690 Digit_11_DMPI 0;
BA_ "GenSigTimeoutTime_SGW" SG_ 2651930690 Digit_09_DMPI 0;
BA_ "GenSigTimeoutTime_RFHM" SG_ 2651930690 Digit_09_DMPI 0;
BA_ "GenSigTimeoutTime_MPAD" SG_ 2651930690 Digit_09_DMPI 0;
BA_ "GenSigTimeoutTime_IPC" SG_ 2651930690 Digit_09_DMPI 0;
BA_ "GenSigTimeoutTime_GNMM" SG_ 2651930690 Digit_09_DMPI 0;
BA_ "GenSigTimeoutTime_EVCU2" SG_ 2651930690 Digit_09_DMPI 0;
BA_ "GenSigTimeoutTime_ESL" SG_ 2651930690 Digit_09_DMPI 0;
BA_ "GenSigTimeoutTime_ECM" SG_ 2651930690 Digit_09_DMPI 0;
BA_ "GenSigTimeoutTime_DTCM" SG_ 2651930690 Digit_09_DMPI 0;
BA_ "GenSigTimeoutTime_DMSM" SG_ 2651930690 Digit_09_DMPI 0;
BA_ "GenSigTimeoutTime_BSM" SG_ 2651930690 Digit_09_DMPI 0;
BA_ "GenSigTimeoutTime_AGSM" SG_ 2651930690 Digit_09_DMPI 0;
BA_ "GenSigTimeoutTime_ADCAM" SG_ 2651930690 Digit_09_DMPI 0;
BA_ "GenSigTimeoutTime_SGW" SG_ 2651930690 Digit_10_DMPI 0;
BA_ "GenSigTimeoutTime_RFHM" SG_ 2651930690 Digit_10_DMPI 0;
BA_ "GenSigTimeoutTime_MPAD" SG_ 2651930690 Digit_10_DMPI 0;
BA_ "GenSigTimeoutTime_IPC" SG_ 2651930690 Digit_10_DMPI 0;
BA_ "GenSigTimeoutTime_GNMM" SG_ 2651930690 Digit_10_DMPI 0;
BA_ "GenSigTimeoutTime_EVCU2" SG_ 2651930690 Digit_10_DMPI 0;
BA_ "GenSigTimeoutTime_ESL" SG_ 2651930690 Digit_10_DMPI 0;
BA_ "GenSigTimeoutTime_ECM" SG_ 2651930690 Digit_10_DMPI 0;
BA_ "GenSigTimeoutTime_DTCM" SG_ 2651930690 Digit_10_DMPI 0;
BA_ "GenSigTimeoutTime_DMSM" SG_ 2651930690 Digit_10_DMPI 0;
BA_ "GenSigTimeoutTime_BSM" SG_ 2651930690 Digit_10_DMPI 0;
BA_ "GenSigTimeoutTime_AGSM" SG_ 2651930690 Digit_10_DMPI 0;
BA_ "GenSigTimeoutTime_ADCAM" SG_ 2651930690 Digit_10_DMPI 0;
BA_ "GenSigTimeoutTime_SGW" SG_ 2651930690 Digit_01_DMPI 0;
BA_ "GenSigTimeoutTime_RFHM" SG_ 2651930690 Digit_01_DMPI 0;
BA_ "GenSigTimeoutTime_MPAD" SG_ 2651930690 Digit_01_DMPI 0;
BA_ "GenSigTimeoutTime_IPC" SG_ 2651930690 Digit_01_DMPI 0;
BA_ "GenSigTimeoutTime_GNMM" SG_ 2651930690 Digit_01_DMPI 0;
BA_ "GenSigTimeoutTime_EVCU2" SG_ 2651930690 Digit_01_DMPI 0;
BA_ "GenSigTimeoutTime_ESL" SG_ 2651930690 Digit_01_DMPI 0;
BA_ "GenSigTimeoutTime_ECM" SG_ 2651930690 Digit_01_DMPI 0;
BA_ "GenSigTimeoutTime_DTCM" SG_ 2651930690 Digit_01_DMPI 0;
BA_ "GenSigTimeoutTime_DMSM" SG_ 2651930690 Digit_01_DMPI 0;
BA_ "GenSigTimeoutTime_BSM" SG_ 2651930690 Digit_01_DMPI 0;
BA_ "GenSigTimeoutTime_AGSM" SG_ 2651930690 Digit_01_DMPI 0;
BA_ "GenSigTimeoutTime_ADCAM" SG_ 2651930690 Digit_01_DMPI 0;
BA_ "GenSigSendType" SG_ 2651930690 Digit_01_DMPI 1;
BA_ "GenSigTimeoutTime_SGW" SG_ 2651930690 Digit_02_DMPI 0;
BA_ "GenSigTimeoutTime_RFHM" SG_ 2651930690 Digit_02_DMPI 0;
BA_ "GenSigTimeoutTime_MPAD" SG_ 2651930690 Digit_02_DMPI 0;
BA_ "GenSigTimeoutTime_IPC" SG_ 2651930690 Digit_02_DMPI 0;
BA_ "GenSigTimeoutTime_GNMM" SG_ 2651930690 Digit_02_DMPI 0;
BA_ "GenSigTimeoutTime_EVCU2" SG_ 2651930690 Digit_02_DMPI 0;
BA_ "GenSigTimeoutTime_ESL" SG_ 2651930690 Digit_02_DMPI 0;
BA_ "GenSigTimeoutTime_ECM" SG_ 2651930690 Digit_02_DMPI 0;
BA_ "GenSigTimeoutTime_DTCM" SG_ 2651930690 Digit_02_DMPI 0;
BA_ "GenSigTimeoutTime_DMSM" SG_ 2651930690 Digit_02_DMPI 0;
BA_ "GenSigTimeoutTime_BSM" SG_ 2651930690 Digit_02_DMPI 0;
BA_ "GenSigTimeoutTime_AGSM" SG_ 2651930690 Digit_02_DMPI 0;
BA_ "GenSigTimeoutTime_ADCAM" SG_ 2651930690 Digit_02_DMPI 0;
BA_ "GenSigTimeoutTime_SGW" SG_ 2651930690 Digit_03_DMPI 0;
BA_ "GenSigTimeoutTime_RFHM" SG_ 2651930690 Digit_03_DMPI 0;
BA_ "GenSigTimeoutTime_MPAD" SG_ 2651930690 Digit_03_DMPI 0;
BA_ "GenSigTimeoutTime_IPC" SG_ 2651930690 Digit_03_DMPI 0;
BA_ "GenSigTimeoutTime_GNMM" SG_ 2651930690 Digit_03_DMPI 0;
BA_ "GenSigTimeoutTime_EVCU2" SG_ 2651930690 Digit_03_DMPI 0;
BA_ "GenSigTimeoutTime_ESL" SG_ 2651930690 Digit_03_DMPI 0;
BA_ "GenSigTimeoutTime_ECM" SG_ 2651930690 Digit_03_DMPI 0;
BA_ "GenSigTimeoutTime_DTCM" SG_ 2651930690 Digit_03_DMPI 0;
BA_ "GenSigTimeoutTime_DMSM" SG_ 2651930690 Digit_03_DMPI 0;
BA_ "GenSigTimeoutTime_BSM" SG_ 2651930690 Digit_03_DMPI 0;
BA_ "GenSigTimeoutTime_AGSM" SG_ 2651930690 Digit_03_DMPI 0;
BA_ "GenSigTimeoutTime_ADCAM" SG_ 2651930690 Digit_03_DMPI 0;
BA_ "GenSigTimeoutTime_SGW" SG_ 2651930690 Digit_04_DMPI 0;
BA_ "GenSigTimeoutTime_RFHM" SG_ 2651930690 Digit_04_DMPI 0;
BA_ "GenSigTimeoutTime_MPAD" SG_ 2651930690 Digit_04_DMPI 0;
BA_ "GenSigTimeoutTime_IPC" SG_ 2651930690 Digit_04_DMPI 0;
BA_ "GenSigTimeoutTime_GNMM" SG_ 2651930690 Digit_04_DMPI 0;
BA_ "GenSigTimeoutTime_EVCU2" SG_ 2651930690 Digit_04_DMPI 0;
BA_ "GenSigTimeoutTime_ESL" SG_ 2651930690 Digit_04_DMPI 0;
BA_ "GenSigTimeoutTime_ECM" SG_ 2651930690 Digit_04_DMPI 0;
BA_ "GenSigTimeoutTime_DTCM" SG_ 2651930690 Digit_04_DMPI 0;
BA_ "GenSigTimeoutTime_DMSM" SG_ 2651930690 Digit_04_DMPI 0;
BA_ "GenSigTimeoutTime_BSM" SG_ 2651930690 Digit_04_DMPI 0;
BA_ "GenSigTimeoutTime_AGSM" SG_ 2651930690 Digit_04_DMPI 0;
BA_ "GenSigTimeoutTime_ADCAM" SG_ 2651930690 Digit_04_DMPI 0;
BA_ "GenSigTimeoutTime_SGW" SG_ 2651930690 Digit_05_DMPI 0;
BA_ "GenSigTimeoutTime_RFHM" SG_ 2651930690 Digit_05_DMPI 0;
BA_ "GenSigTimeoutTime_MPAD" SG_ 2651930690 Digit_05_DMPI 0;
BA_ "GenSigTimeoutTime_IPC" SG_ 2651930690 Digit_05_DMPI 0;
BA_ "GenSigTimeoutTime_GNMM" SG_ 2651930690 Digit_05_DMPI 0;
BA_ "GenSigTimeoutTime_EVCU2" SG_ 2651930690 Digit_05_DMPI 0;
BA_ "GenSigTimeoutTime_ESL" SG_ 2651930690 Digit_05_DMPI 0;
BA_ "GenSigTimeoutTime_ECM" SG_ 2651930690 Digit_05_DMPI 0;
BA_ "GenSigTimeoutTime_DTCM" SG_ 2651930690 Digit_05_DMPI 0;
BA_ "GenSigTimeoutTime_DMSM" SG_ 2651930690 Digit_05_DMPI 0;
BA_ "GenSigTimeoutTime_BSM" SG_ 2651930690 Digit_05_DMPI 0;
BA_ "GenSigTimeoutTime_AGSM" SG_ 2651930690 Digit_05_DMPI 0;
BA_ "GenSigTimeoutTime_ADCAM" SG_ 2651930690 Digit_05_DMPI 0;
BA_ "GenSigTimeoutTime_SGW" SG_ 2651930690 Digit_06_DMPI 0;
BA_ "GenSigTimeoutTime_RFHM" SG_ 2651930690 Digit_06_DMPI 0;
BA_ "GenSigTimeoutTime_MPAD" SG_ 2651930690 Digit_06_DMPI 0;
BA_ "GenSigTimeoutTime_IPC" SG_ 2651930690 Digit_06_DMPI 0;
BA_ "GenSigTimeoutTime_GNMM" SG_ 2651930690 Digit_06_DMPI 0;
BA_ "GenSigTimeoutTime_EVCU2" SG_ 2651930690 Digit_06_DMPI 0;
BA_ "GenSigTimeoutTime_ESL" SG_ 2651930690 Digit_06_DMPI 0;
BA_ "GenSigTimeoutTime_ECM" SG_ 2651930690 Digit_06_DMPI 0;
BA_ "GenSigTimeoutTime_DTCM" SG_ 2651930690 Digit_06_DMPI 0;
BA_ "GenSigTimeoutTime_DMSM" SG_ 2651930690 Digit_06_DMPI 0;
BA_ "GenSigTimeoutTime_BSM" SG_ 2651930690 Digit_06_DMPI 0;
BA_ "GenSigTimeoutTime_AGSM" SG_ 2651930690 Digit_06_DMPI 0;
BA_ "GenSigTimeoutTime_ADCAM" SG_ 2651930690 Digit_06_DMPI 0;
BA_ "GenSigTimeoutTime_SGW" SG_ 2651930690 Digit_07_DMPI 0;
BA_ "GenSigTimeoutTime_RFHM" SG_ 2651930690 Digit_07_DMPI 0;
BA_ "GenSigTimeoutTime_MPAD" SG_ 2651930690 Digit_07_DMPI 0;
BA_ "GenSigTimeoutTime_IPC" SG_ 2651930690 Digit_07_DMPI 0;
BA_ "GenSigTimeoutTime_GNMM" SG_ 2651930690 Digit_07_DMPI 0;
BA_ "GenSigTimeoutTime_EVCU2" SG_ 2651930690 Digit_07_DMPI 0;
BA_ "GenSigTimeoutTime_ESL" SG_ 2651930690 Digit_07_DMPI 0;
BA_ "GenSigTimeoutTime_ECM" SG_ 2651930690 Digit_07_DMPI 0;
BA_ "GenSigTimeoutTime_DTCM" SG_ 2651930690 Digit_07_DMPI 0;
BA_ "GenSigTimeoutTime_DMSM" SG_ 2651930690 Digit_07_DMPI 0;
BA_ "GenSigTimeoutTime_BSM" SG_ 2651930690 Digit_07_DMPI 0;
BA_ "GenSigTimeoutTime_AGSM" SG_ 2651930690 Digit_07_DMPI 0;
BA_ "GenSigTimeoutTime_ADCAM" SG_ 2651930690 Digit_07_DMPI 0;
BA_ "GenSigTimeoutTime_SGW" SG_ 2651930690 Digit_08_DMPI 0;
BA_ "GenSigTimeoutTime_RFHM" SG_ 2651930690 Digit_08_DMPI 0;
BA_ "GenSigTimeoutTime_MPAD" SG_ 2651930690 Digit_08_DMPI 0;
BA_ "GenSigTimeoutTime_IPC" SG_ 2651930690 Digit_08_DMPI 0;
BA_ "GenSigTimeoutTime_GNMM" SG_ 2651930690 Digit_08_DMPI 0;
BA_ "GenSigTimeoutTime_EVCU2" SG_ 2651930690 Digit_08_DMPI 0;
BA_ "GenSigTimeoutTime_ESL" SG_ 2651930690 Digit_08_DMPI 0;
BA_ "GenSigTimeoutTime_ECM" SG_ 2651930690 Digit_08_DMPI 0;
BA_ "GenSigTimeoutTime_DTCM" SG_ 2651930690 Digit_08_DMPI 0;
BA_ "GenSigTimeoutTime_DMSM" SG_ 2651930690 Digit_08_DMPI 0;
BA_ "GenSigTimeoutTime_BSM" SG_ 2651930690 Digit_08_DMPI 0;
BA_ "GenSigTimeoutTime_AGSM" SG_ 2651930690 Digit_08_DMPI 0;
BA_ "GenSigTimeoutTime_ADCAM" SG_ 2651930690 Digit_08_DMPI 0;
BA_ "GenSigTimeoutTime_DMSM" SG_ 2654339197 CurrentFailSts_FD11_IDCM 0;
BA_ "GenSigTimeoutTime_BSM" SG_ 2654339197 CurrentFailSts_FD11_IDCM 0;
BA_ "GenSigTimeoutTime_BCM" SG_ 2654339197 CurrentFailSts_FD11_IDCM 0;
BA_ "GenSigTimeoutTime_AGSM" SG_ 2654339197 CurrentFailSts_FD11_IDCM 0;
BA_ "GenSigTimeoutTime_ADCAM" SG_ 2654339197 CurrentFailSts_FD11_IDCM 0;
BA_ "GenSigTimeoutTime_EVCU2" SG_ 1487 Est_Range_FullCharge 0;
BA_ "GenSigTimeoutTime_ESL" SG_ 1487 Est_Range_FullCharge 0;
BA_ "GenSigTimeoutTime_ECM" SG_ 1487 Est_Range_FullCharge 0;
BA_ "GenSigTimeoutTime_DTCM" SG_ 1487 Est_Range_FullCharge 0;
BA_ "GenSigTimeoutTime_DMSM" SG_ 1487 Est_Range_FullCharge 0;
BA_ "GenSigTimeoutTime_BSM" SG_ 1487 Est_Range_FullCharge 0;
BA_ "GenSigTimeoutTime_BCM" SG_ 1487 Est_Range_FullCharge 0;
BA_ "GenSigTimeoutTime_AGSM" SG_ 1487 Est_Range_FullCharge 0;
BA_ "GenSigTimeoutTime_ADCAM" SG_ 1487 Est_Range_FullCharge 0;
BA_ "GenSigTimeoutTime_RFHM" SG_ 1487 Energy_to_Battery 0;
BA_ "GenSigTimeoutTime_MPAD" SG_ 1487 Energy_to_Battery 0;
BA_ "GenSigTimeoutTime_IPC" SG_ 1487 Energy_to_Battery 0;
BA_ "GenSigTimeoutTime_GNMM" SG_ 1487 Energy_to_Battery 0;
BA_ "GenSigTimeoutTime_EVCU2" SG_ 1487 Energy_to_Battery 0;
BA_ "GenSigTimeoutTime_ESL" SG_ 1487 Energy_to_Battery 0;
BA_ "GenSigTimeoutTime_ECM" SG_ 1487 Energy_to_Battery 0;
BA_ "GenSigTimeoutTime_DTCM" SG_ 1487 Energy_to_Battery 0;
BA_ "GenSigTimeoutTime_DMSM" SG_ 1487 Energy_to_Battery 0;
BA_ "GenSigTimeoutTime_BSM" SG_ 1487 Energy_to_Battery 0;
BA_ "GenSigTimeoutTime_BCM" SG_ 1487 Energy_to_Battery 0;
BA_ "GenSigTimeoutTime_AGSM" SG_ 1487 Energy_to_Battery 0;
BA_ "GenSigTimeoutTime_ADCAM" SG_ 1487 Energy_to_Battery 0;
BA_ "GenSigTimeoutTime_RFHM" SG_ 1487 Cooperative_Status 0;
BA_ "GenSigTimeoutTime_MPAD" SG_ 1487 Cooperative_Status 0;
BA_ "GenSigTimeoutTime_IPC" SG_ 1487 Cooperative_Status 0;
BA_ "GenSigTimeoutTime_GNMM" SG_ 1487 Cooperative_Status 0;
BA_ "GenSigTimeoutTime_EVCU2" SG_ 1487 Cooperative_Status 0;
BA_ "GenSigTimeoutTime_ESL" SG_ 1487 Cooperative_Status 0;
BA_ "GenSigTimeoutTime_ECM" SG_ 1487 Cooperative_Status 0;
BA_ "GenSigTimeoutTime_DTCM" SG_ 1487 Cooperative_Status 0;
BA_ "GenSigTimeoutTime_DMSM" SG_ 1487 Cooperative_Status 0;
BA_ "GenSigTimeoutTime_BSM" SG_ 1487 Cooperative_Status 0;
BA_ "GenSigTimeoutTime_BCM" SG_ 1487 Cooperative_Status 0;
BA_ "GenSigTimeoutTime_AGSM" SG_ 1487 Cooperative_Status 0;
BA_ "GenSigTimeoutTime_ADCAM" SG_ 1487 Cooperative_Status 0;
BA_ "GenSigTimeoutTime_RFHM" SG_ 1487 Chargeport_Lock_Status 0;
BA_ "GenSigTimeoutTime_MPAD" SG_ 1487 Chargeport_Lock_Status 0;
BA_ "GenSigTimeoutTime_IPC" SG_ 1487 Chargeport_Lock_Status 0;
BA_ "GenSigTimeoutTime_GNMM" SG_ 1487 Chargeport_Lock_Status 0;
BA_ "GenSigTimeoutTime_EVCU2" SG_ 1487 Chargeport_Lock_Status 0;
BA_ "GenSigTimeoutTime_ESL" SG_ 1487 Chargeport_Lock_Status 0;
BA_ "GenSigTimeoutTime_ECM" SG_ 1487 Chargeport_Lock_Status 0;
BA_ "GenSigTimeoutTime_DTCM" SG_ 1487 Chargeport_Lock_Status 0;
BA_ "GenSigTimeoutTime_DMSM" SG_ 1487 Chargeport_Lock_Status 0;
BA_ "GenSigTimeoutTime_BSM" SG_ 1487 Chargeport_Lock_Status 0;
BA_ "GenSigTimeoutTime_BCM" SG_ 1487 Chargeport_Lock_Status 0;
BA_ "GenSigTimeoutTime_AGSM" SG_ 1487 Chargeport_Lock_Status 0;
BA_ "GenSigTimeoutTime_ADCAM" SG_ 1487 Chargeport_Lock_Status 0;
BA_ "GenSigTimeoutTime_BCM" SG_ 2654339132 PreviousCanNMState_FD05_PBWM 0;
BA_ "GenSigTimeoutTime_AGSM" SG_ 2654339132 PreviousCanNMState_FD05_PBWM 0;
BA_ "GenSigTimeoutTime_ADCAM" SG_ 2654339132 PreviousCanNMState_FD05_PBWM 0;
BA_ "GenSigTimeoutTime_SGW" SG_ 2654339132 GenericFailSts_FD11_PBWM 0;
BA_ "GenSigTimeoutTime_RFHM" SG_ 2654339132 GenericFailSts_FD11_PBWM 0;
BA_ "GenSigTimeoutTime_MPAD" SG_ 2654339132 GenericFailSts_FD11_PBWM 0;
BA_ "GenSigTimeoutTime_IPC" SG_ 2654339132 GenericFailSts_FD11_PBWM 0;
BA_ "GenSigTimeoutTime_GNMM" SG_ 2654339132 GenericFailSts_FD11_PBWM 0;
BA_ "GenSigTimeoutTime_EVCU2" SG_ 2654339132 GenericFailSts_FD11_PBWM 0;
BA_ "GenSigTimeoutTime_ESL" SG_ 2654339132 GenericFailSts_FD11_PBWM 0;
BA_ "GenSigTimeoutTime_ECM" SG_ 2654339132 GenericFailSts_FD11_PBWM 0;
BA_ "GenSigTimeoutTime_DTCM" SG_ 2654339132 GenericFailSts_FD11_PBWM 0;
BA_ "GenSigTimeoutTime_DMSM" SG_ 2654339132 GenericFailSts_FD11_PBWM 0;
BA_ "GenSigTimeoutTime_BSM" SG_ 2654339132 GenericFailSts_FD11_PBWM 0;
BA_ "GenSigTimeoutTime_AGSM" SG_ 2654339132 GenericFailSts_FD11_PBWM 0;
BA_ "GenSigTimeoutTime_ADCAM" SG_ 2654339132 GenericFailSts_FD11_PBWM 0;
BA_ "GenSigTimeoutTime_SGW" SG_ 2654339132 GenericFailSts_FD05_PBWM 0;
BA_ "GenSigTimeoutTime_RFHM" SG_ 2654339132 GenericFailSts_FD05_PBWM 0;
BA_ "GenSigTimeoutTime_MPAD" SG_ 2654339132 GenericFailSts_FD05_PBWM 0;
BA_ "GenSigTimeoutTime_IPC" SG_ 2654339132 GenericFailSts_FD05_PBWM 0;
BA_ "GenSigTimeoutTime_GNMM" SG_ 2654339132 GenericFailSts_FD05_PBWM 0;
BA_ "GenSigTimeoutTime_EVCU2" SG_ 2654339132 GenericFailSts_FD05_PBWM 0;
BA_ "GenSigTimeoutTime_ESL" SG_ 2654339132 GenericFailSts_FD05_PBWM 0;
BA_ "GenSigTimeoutTime_ECM" SG_ 2654339132 GenericFailSts_FD05_PBWM 0;
BA_ "GenSigTimeoutTime_DTCM" SG_ 2654339132 GenericFailSts_FD05_PBWM 0;
BA_ "GenSigTimeoutTime_DMSM" SG_ 2654339132 GenericFailSts_FD05_PBWM 0;
BA_ "GenSigTimeoutTime_BSM" SG_ 2654339132 GenericFailSts_FD05_PBWM 0;
BA_ "GenSigTimeoutTime_BCM" SG_ 2654339132 GenericFailSts_FD05_PBWM 0;
BA_ "GenSigTimeoutTime_AGSM" SG_ 2654339132 GenericFailSts_FD05_PBWM 0;
BA_ "GenSigTimeoutTime_ADCAM" SG_ 2654339132 GenericFailSts_FD05_PBWM 0;
BA_ "GenSigTimeoutTime_SGW" SG_ 2654339132 EOL_FD11_PBWM 0;
BA_ "GenSigTimeoutTime_RFHM" SG_ 2654339132 EOL_FD11_PBWM 0;
BA_ "GenSigTimeoutTime_MPAD" SG_ 2654339132 EOL_FD11_PBWM 0;
BA_ "GenSigTimeoutTime_IPC" SG_ 2654339132 EOL_FD11_PBWM 0;
BA_ "GenSigTimeoutTime_GNMM" SG_ 2654339132 EOL_FD11_PBWM 0;
BA_ "GenSigTimeoutTime_EVCU2" SG_ 2654339132 EOL_FD11_PBWM 0;
BA_ "GenSigTimeoutTime_ESL" SG_ 2654339132 EOL_FD11_PBWM 0;
BA_ "GenSigTimeoutTime_ECM" SG_ 2654339132 EOL_FD11_PBWM 0;
BA_ "GenSigTimeoutTime_DTCM" SG_ 2654339132 EOL_FD11_PBWM 0;
BA_ "GenSigTimeoutTime_DMSM" SG_ 2654339132 EOL_FD11_PBWM 0;
BA_ "GenSigTimeoutTime_BSM" SG_ 2654339132 EOL_FD11_PBWM 0;
BA_ "GenSigTimeoutTime_AGSM" SG_ 2654339132 EOL_FD11_PBWM 0;
BA_ "GenSigTimeoutTime_ADCAM" SG_ 2654339132 EOL_FD11_PBWM 0;
BA_ "GenSigTimeoutTime_SGW" SG_ 2654339132 CurrentCanNMState_FD05_PBWM 0;
BA_ "GenSigTimeoutTime_RFHM" SG_ 2654339132 CurrentCanNMState_FD05_PBWM 0;
BA_ "GenSigTimeoutTime_MPAD" SG_ 2654339132 CurrentCanNMState_FD05_PBWM 0;
BA_ "GenSigTimeoutTime_IPC" SG_ 2654339132 CurrentCanNMState_FD05_PBWM 0;
BA_ "GenSigTimeoutTime_GNMM" SG_ 2654339132 CurrentCanNMState_FD05_PBWM 0;
BA_ "GenSigTimeoutTime_EVCU2" SG_ 2654339132 CurrentCanNMState_FD05_PBWM 0;
BA_ "GenSigTimeoutTime_ESL" SG_ 2654339132 CurrentCanNMState_FD05_PBWM 0;
BA_ "GenSigTimeoutTime_ECM" SG_ 2654339132 CurrentCanNMState_FD05_PBWM 0;
BA_ "GenSigTimeoutTime_DTCM" SG_ 2654339132 CurrentCanNMState_FD05_PBWM 0;
BA_ "GenSigTimeoutTime_DMSM" SG_ 2654339132 CurrentCanNMState_FD05_PBWM 0;
BA_ "GenSigTimeoutTime_BSM" SG_ 2654339132 CurrentCanNMState_FD05_PBWM 0;
BA_ "GenSigTimeoutTime_BCM" SG_ 2654339132 CurrentCanNMState_FD05_PBWM 0;
BA_ "GenSigTimeoutTime_AGSM" SG_ 2654339132 CurrentCanNMState_FD05_PBWM 0;
BA_ "GenSigTimeoutTime_ADCAM" SG_ 2654339132 CurrentCanNMState_FD05_PBWM 0;
BA_ "GenSigTimeoutTime_SGW" SG_ 2654339132 CurrentFailSts_FD05_PBWM 0;
BA_ "GenSigTimeoutTime_RFHM" SG_ 2654339132 CurrentFailSts_FD05_PBWM 0;
BA_ "GenSigTimeoutTime_MPAD" SG_ 2654339132 CurrentFailSts_FD05_PBWM 0;
BA_ "GenSigTimeoutTime_IPC" SG_ 2654339132 CurrentFailSts_FD05_PBWM 0;
BA_ "GenSigTimeoutTime_GNMM" SG_ 2654339132 CurrentFailSts_FD05_PBWM 0;
BA_ "GenSigTimeoutTime_EVCU2" SG_ 2654339132 CurrentFailSts_FD05_PBWM 0;
BA_ "GenSigTimeoutTime_ESL" SG_ 2654339132 CurrentFailSts_FD05_PBWM 0;
BA_ "GenSigTimeoutTime_ECM" SG_ 2654339132 CurrentFailSts_FD05_PBWM 0;
BA_ "GenSigTimeoutTime_DTCM" SG_ 2654339132 CurrentFailSts_FD05_PBWM 0;
BA_ "GenSigTimeoutTime_DMSM" SG_ 2654339132 CurrentFailSts_FD05_PBWM 0;
BA_ "GenSigTimeoutTime_BSM" SG_ 2654339132 CurrentFailSts_FD05_PBWM 0;
BA_ "GenSigTimeoutTime_BCM" SG_ 2654339132 CurrentFailSts_FD05_PBWM 0;
BA_ "GenSigTimeoutTime_AGSM" SG_ 2654339132 CurrentFailSts_FD05_PBWM 0;
BA_ "GenSigTimeoutTime_ADCAM" SG_ 2654339132 CurrentFailSts_FD05_PBWM 0;
BA_ "GenSigTimeoutTime_SGW" SG_ 2654339132 CurrentCanNMState_FD11_PBWM 0;
BA_ "GenSigTimeoutTime_RFHM" SG_ 2654339132 CurrentCanNMState_FD11_PBWM 0;
BA_ "GenSigTimeoutTime_MPAD" SG_ 2654339132 CurrentCanNMState_FD11_PBWM 0;
BA_ "GenSigTimeoutTime_IPC" SG_ 2654339132 CurrentCanNMState_FD11_PBWM 0;
BA_ "GenSigTimeoutTime_GNMM" SG_ 2654339132 CurrentCanNMState_FD11_PBWM 0;
BA_ "GenSigTimeoutTime_EVCU2" SG_ 2654339132 CurrentCanNMState_FD11_PBWM 0;
BA_ "GenSigTimeoutTime_ESL" SG_ 2654339132 CurrentCanNMState_FD11_PBWM 0;
BA_ "GenSigTimeoutTime_ECM" SG_ 2654339132 CurrentCanNMState_FD11_PBWM 0;
BA_ "GenSigTimeoutTime_DTCM" SG_ 2654339132 CurrentCanNMState_FD11_PBWM 0;
BA_ "GenSigTimeoutTime_DMSM" SG_ 2654339132 CurrentCanNMState_FD11_PBWM 0;
BA_ "GenSigTimeoutTime_BSM" SG_ 2654339132 CurrentCanNMState_FD11_PBWM 0;
BA_ "GenSigTimeoutTime_BCM" SG_ 2654339132 CurrentCanNMState_FD11_PBWM 0;
BA_ "GenSigTimeoutTime_AGSM" SG_ 2654339132 CurrentCanNMState_FD11_PBWM 0;
BA_ "GenSigTimeoutTime_ADCAM" SG_ 2654339132 CurrentCanNMState_FD11_PBWM 0;
BA_ "GenSigTimeoutTime_SGW" SG_ 2654339132 EOL_FD05_PBWM 0;
BA_ "GenSigTimeoutTime_RFHM" SG_ 2654339132 EOL_FD05_PBWM 0;
BA_ "GenSigTimeoutTime_MPAD" SG_ 2654339132 EOL_FD05_PBWM 0;
BA_ "GenSigTimeoutTime_IPC" SG_ 2654339132 EOL_FD05_PBWM 0;
BA_ "GenSigTimeoutTime_GNMM" SG_ 2654339132 EOL_FD05_PBWM 0;
BA_ "GenSigTimeoutTime_EVCU2" SG_ 2654339132 EOL_FD05_PBWM 0;
BA_ "GenSigTimeoutTime_ESL" SG_ 2654339132 EOL_FD05_PBWM 0;
BA_ "GenSigTimeoutTime_ECM" SG_ 2654339132 EOL_FD05_PBWM 0;
BA_ "GenSigTimeoutTime_DTCM" SG_ 2654339132 EOL_FD05_PBWM 0;
BA_ "GenSigTimeoutTime_DMSM" SG_ 2654339132 EOL_FD05_PBWM 0;
BA_ "GenSigTimeoutTime_BSM" SG_ 2654339132 EOL_FD05_PBWM 0;
BA_ "GenSigTimeoutTime_BCM" SG_ 2654339132 EOL_FD05_PBWM 0;
BA_ "GenSigTimeoutTime_AGSM" SG_ 2654339132 EOL_FD05_PBWM 0;
BA_ "GenSigTimeoutTime_ADCAM" SG_ 2654339132 EOL_FD05_PBWM 0;
BA_ "GenSigTimeoutTime_SGW" SG_ 2654339132 DES_FD11_PBWM 0;
BA_ "GenSigTimeoutTime_RFHM" SG_ 2654339132 DES_FD11_PBWM 0;
BA_ "GenSigTimeoutTime_MPAD" SG_ 2654339132 DES_FD11_PBWM 0;
BA_ "GenSigTimeoutTime_IPC" SG_ 2654339132 DES_FD11_PBWM 0;
BA_ "GenSigTimeoutTime_GNMM" SG_ 2654339132 DES_FD11_PBWM 0;
BA_ "GenSigTimeoutTime_EVCU2" SG_ 2654339132 DES_FD11_PBWM 0;
BA_ "GenSigTimeoutTime_ESL" SG_ 2654339132 DES_FD11_PBWM 0;
BA_ "GenSigTimeoutTime_ECM" SG_ 2654339132 DES_FD11_PBWM 0;
BA_ "GenSigTimeoutTime_DTCM" SG_ 2654339132 DES_FD11_PBWM 0;
BA_ "GenSigTimeoutTime_DMSM" SG_ 2654339132 DES_FD11_PBWM 0;
BA_ "GenSigTimeoutTime_BSM" SG_ 2654339132 DES_FD11_PBWM 0;
BA_ "GenSigTimeoutTime_BCM" SG_ 2654339132 DES_FD11_PBWM 0;
BA_ "GenSigTimeoutTime_AGSM" SG_ 2654339132 DES_FD11_PBWM 0;
BA_ "GenSigTimeoutTime_ADCAM" SG_ 2654339132 DES_FD11_PBWM 0;
BA_ "GenSigTimeoutTime_SGW" SG_ 2654339132 DES_FD05_PBWM 0;
BA_ "GenSigTimeoutTime_RFHM" SG_ 2654339132 DES_FD05_PBWM 0;
BA_ "GenSigTimeoutTime_MPAD" SG_ 2654339132 DES_FD05_PBWM 0;
BA_ "GenSigTimeoutTime_IPC" SG_ 2654339132 DES_FD05_PBWM 0;
BA_ "GenSigTimeoutTime_GNMM" SG_ 2654339132 DES_FD05_PBWM 0;
BA_ "GenSigTimeoutTime_EVCU2" SG_ 2654339132 DES_FD05_PBWM 0;
BA_ "GenSigTimeoutTime_ESL" SG_ 2654339132 DES_FD05_PBWM 0;
BA_ "GenSigTimeoutTime_ECM" SG_ 2654339132 DES_FD05_PBWM 0;
BA_ "GenSigTimeoutTime_DTCM" SG_ 2654339132 DES_FD05_PBWM 0;
BA_ "GenSigTimeoutTime_DMSM" SG_ 2654339132 DES_FD05_PBWM 0;
BA_ "GenSigTimeoutTime_BSM" SG_ 2654339132 DES_FD05_PBWM 0;
BA_ "GenSigTimeoutTime_BCM" SG_ 2654339132 DES_FD05_PBWM 0;
BA_ "GenSigTimeoutTime_AGSM" SG_ 2654339132 DES_FD05_PBWM 0;
BA_ "GenSigTimeoutTime_ADCAM" SG_ 2654339132 DES_FD05_PBWM 0;
BA_ "GenSigTimeoutTime_SGW" SG_ 2654339132 CurrentFailSts_FD11_PBWM 0;
BA_ "GenSigTimeoutTime_RFHM" SG_ 2654339132 CurrentFailSts_FD11_PBWM 0;
BA_ "GenSigTimeoutTime_MPAD" SG_ 2654339132 CurrentFailSts_FD11_PBWM 0;
BA_ "GenSigTimeoutTime_IPC" SG_ 2654339132 CurrentFailSts_FD11_PBWM 0;
BA_ "GenSigTimeoutTime_GNMM" SG_ 2654339132 CurrentFailSts_FD11_PBWM 0;
BA_ "GenSigTimeoutTime_EVCU2" SG_ 2654339132 CurrentFailSts_FD11_PBWM 0;
BA_ "GenSigTimeoutTime_ESL" SG_ 2654339132 CurrentFailSts_FD11_PBWM 0;
BA_ "GenSigTimeoutTime_ECM" SG_ 2654339132 CurrentFailSts_FD11_PBWM 0;
BA_ "GenSigTimeoutTime_DTCM" SG_ 2654339132 CurrentFailSts_FD11_PBWM 0;
BA_ "GenSigTimeoutTime_DMSM" SG_ 2654339132 CurrentFailSts_FD11_PBWM 0;
BA_ "GenSigTimeoutTime_BSM" SG_ 2654339132 CurrentFailSts_FD11_PBWM 0;
BA_ "GenSigTimeoutTime_AGSM" SG_ 2654339132 CurrentFailSts_FD11_PBWM 0;
BA_ "GenSigTimeoutTime_ADCAM" SG_ 2654339132 CurrentFailSts_FD11_PBWM 0;
BA_ "GenSigTimeoutTime_RFHM" SG_ 1914 Update_Status_MPFC 0;
BA_ "GenSigTimeoutTime_MPAD" SG_ 1914 Update_Status_MPFC 0;
BA_ "GenSigTimeoutTime_IPC" SG_ 1914 Update_Status_MPFC 0;
BA_ "GenSigTimeoutTime_GNMM" SG_ 1914 Update_Status_MPFC 0;
BA_ "GenSigTimeoutTime_EVCU2" SG_ 1914 Update_Status_MPFC 0;
BA_ "GenSigTimeoutTime_ESL" SG_ 1914 Update_Status_MPFC 0;
BA_ "GenSigTimeoutTime_ECM" SG_ 1914 Update_Status_MPFC 0;
BA_ "GenSigTimeoutTime_DTCM" SG_ 1914 Update_Status_MPFC 0;
BA_ "GenSigTimeoutTime_DMSM" SG_ 1914 Update_Status_MPFC 0;
BA_ "GenSigTimeoutTime_BSM" SG_ 1914 Update_Status_MPFC 0;
BA_ "GenSigTimeoutTime_BCM" SG_ 1914 Update_Status_MPFC 0;
BA_ "GenSigTimeoutTime_AGSM" SG_ 1914 Update_Status_MPFC 0;
BA_ "GenSigTimeoutTime_ADCAM" SG_ 1914 Update_Status_MPFC 0;
BA_ "GenSigTimeoutTime_RFHM" SG_ 1914 Download_Status_MPFC 0;
BA_ "GenSigTimeoutTime_MPAD" SG_ 1914 Download_Status_MPFC 0;
BA_ "GenSigTimeoutTime_IPC" SG_ 1914 Download_Status_MPFC 0;
BA_ "GenSigTimeoutTime_GNMM" SG_ 1914 Download_Status_MPFC 0;
BA_ "GenSigTimeoutTime_EVCU2" SG_ 1914 Download_Status_MPFC 0;
BA_ "GenSigTimeoutTime_ESL" SG_ 1914 Download_Status_MPFC 0;
BA_ "GenSigTimeoutTime_ECM" SG_ 1914 Download_Status_MPFC 0;
BA_ "GenSigTimeoutTime_DTCM" SG_ 1914 Download_Status_MPFC 0;
BA_ "GenSigTimeoutTime_DMSM" SG_ 1914 Download_Status_MPFC 0;
BA_ "GenSigTimeoutTime_BSM" SG_ 1914 Download_Status_MPFC 0;
BA_ "GenSigTimeoutTime_BCM" SG_ 1914 Download_Status_MPFC 0;
BA_ "GenSigTimeoutTime_AGSM" SG_ 1914 Download_Status_MPFC 0;
BA_ "GenSigTimeoutTime_ADCAM" SG_ 1914 Download_Status_MPFC 0;
BA_ "GenSigTimeoutTime_RFHM" SG_ 1914 Big_ECU_Ready_MPFC 0;
BA_ "GenSigTimeoutTime_MPAD" SG_ 1914 Big_ECU_Ready_MPFC 0;
BA_ "GenSigTimeoutTime_IPC" SG_ 1914 Big_ECU_Ready_MPFC 0;
BA_ "GenSigTimeoutTime_GNMM" SG_ 1914 Big_ECU_Ready_MPFC 0;
BA_ "GenSigTimeoutTime_EVCU2" SG_ 1914 Big_ECU_Ready_MPFC 0;
BA_ "GenSigTimeoutTime_ESL" SG_ 1914 Big_ECU_Ready_MPFC 0;
BA_ "GenSigTimeoutTime_ECM" SG_ 1914 Big_ECU_Ready_MPFC 0;
BA_ "GenSigTimeoutTime_DTCM" SG_ 1914 Big_ECU_Ready_MPFC 0;
BA_ "GenSigTimeoutTime_DMSM" SG_ 1914 Big_ECU_Ready_MPFC 0;
BA_ "GenSigTimeoutTime_BSM" SG_ 1914 Big_ECU_Ready_MPFC 0;
BA_ "GenSigTimeoutTime_BCM" SG_ 1914 Big_ECU_Ready_MPFC 0;
BA_ "GenSigTimeoutTime_AGSM" SG_ 1914 Big_ECU_Ready_MPFC 0;
BA_ "GenSigTimeoutTime_ADCAM" SG_ 1914 Big_ECU_Ready_MPFC 0;
BA_ "GenSigTimeoutTime_RFHM" SG_ 2654339137 WakeupSource_FD03_RFHM 0;
BA_ "GenSigTimeoutTime_MPAD" SG_ 2654339137 WakeupSource_FD03_RFHM 0;
BA_ "GenSigTimeoutTime_IPC" SG_ 2654339137 WakeupSource_FD03_RFHM 0;
BA_ "GenSigTimeoutTime_GNMM" SG_ 2654339137 WakeupSource_FD03_RFHM 0;
BA_ "GenSigTimeoutTime_EVCU2" SG_ 2654339137 WakeupSource_FD03_RFHM 0;
BA_ "GenSigTimeoutTime_ESL" SG_ 2654339137 WakeupSource_FD03_RFHM 0;
BA_ "GenSigTimeoutTime_ECM" SG_ 2654339137 WakeupSource_FD03_RFHM 0;
BA_ "GenSigTimeoutTime_DTCM" SG_ 2654339137 WakeupSource_FD03_RFHM 0;
BA_ "GenSigTimeoutTime_DMSM" SG_ 2654339137 WakeupSource_FD03_RFHM 0;
BA_ "GenSigTimeoutTime_BSM" SG_ 2654339137 WakeupSource_FD03_RFHM 0;
BA_ "GenSigTimeoutTime_BCM" SG_ 2654339137 WakeupSource_FD03_RFHM 0;
BA_ "GenSigTimeoutTime_AGSM" SG_ 2654339137 WakeupSource_FD03_RFHM 0;
BA_ "GenSigTimeoutTime_ADCAM" SG_ 2654339137 WakeupSource_FD03_RFHM 0;
BA_ "GenSigTimeoutTime_RFHM" SG_ 2654339137 PreviousCanNMState_FD03_RFHM 0;
BA_ "GenSigTimeoutTime_MPAD" SG_ 2654339137 PreviousCanNMState_FD03_RFHM 0;
BA_ "GenSigTimeoutTime_IPC" SG_ 2654339137 PreviousCanNMState_FD03_RFHM 0;
BA_ "GenSigTimeoutTime_GNMM" SG_ 2654339137 PreviousCanNMState_FD03_RFHM 0;
BA_ "GenSigTimeoutTime_EVCU2" SG_ 2654339137 PreviousCanNMState_FD03_RFHM 0;
BA_ "GenSigTimeoutTime_ESL" SG_ 2654339137 PreviousCanNMState_FD03_RFHM 0;
BA_ "GenSigTimeoutTime_ECM" SG_ 2654339137 PreviousCanNMState_FD03_RFHM 0;
BA_ "GenSigTimeoutTime_DTCM" SG_ 2654339137 PreviousCanNMState_FD03_RFHM 0;
BA_ "GenSigTimeoutTime_DMSM" SG_ 2654339137 PreviousCanNMState_FD03_RFHM 0;
BA_ "GenSigTimeoutTime_BSM" SG_ 2654339137 PreviousCanNMState_FD03_RFHM 0;
BA_ "GenSigTimeoutTime_BCM" SG_ 2654339137 PreviousCanNMState_FD03_RFHM 0;
BA_ "GenSigTimeoutTime_AGSM" SG_ 2654339137 PreviousCanNMState_FD03_RFHM 0;
BA_ "GenSigTimeoutTime_ADCAM" SG_ 2654339137 PreviousCanNMState_FD03_RFHM 0;
BA_ "GenSigTimeoutTime_RFHM" SG_ 2654339137 WakeupSource_FD09_RFHM 0;
BA_ "GenSigTimeoutTime_MPAD" SG_ 2654339137 WakeupSource_FD09_RFHM 0;
BA_ "GenSigTimeoutTime_IPC" SG_ 2654339137 WakeupSource_FD09_RFHM 0;
BA_ "GenSigTimeoutTime_GNMM" SG_ 2654339137 WakeupSource_FD09_RFHM 0;
BA_ "GenSigTimeoutTime_EVCU2" SG_ 2654339137 WakeupSource_FD09_RFHM 0;
BA_ "GenSigTimeoutTime_ESL" SG_ 2654339137 WakeupSource_FD09_RFHM 0;
BA_ "GenSigTimeoutTime_ECM" SG_ 2654339137 WakeupSource_FD09_RFHM 0;
BA_ "GenSigTimeoutTime_DTCM" SG_ 2654339137 WakeupSource_FD09_RFHM 0;
BA_ "GenSigTimeoutTime_DMSM" SG_ 2654339137 WakeupSource_FD09_RFHM 0;
BA_ "GenSigTimeoutTime_BSM" SG_ 2654339137 WakeupSource_FD09_RFHM 0;
BA_ "GenSigTimeoutTime_BCM" SG_ 2654339137 WakeupSource_FD09_RFHM 0;
BA_ "GenSigTimeoutTime_AGSM" SG_ 2654339137 WakeupSource_FD09_RFHM 0;
BA_ "GenSigTimeoutTime_ADCAM" SG_ 2654339137 WakeupSource_FD09_RFHM 0;
BA_ "GenSigTimeoutTime_RFHM" SG_ 2654339137 StayActiveSource_FD09_RFHM 0;
BA_ "GenSigTimeoutTime_MPAD" SG_ 2654339137 StayActiveSource_FD09_RFHM 0;
BA_ "GenSigTimeoutTime_IPC" SG_ 2654339137 StayActiveSource_FD09_RFHM 0;
BA_ "GenSigTimeoutTime_GNMM" SG_ 2654339137 StayActiveSource_FD09_RFHM 0;
BA_ "GenSigTimeoutTime_EVCU2" SG_ 2654339137 StayActiveSource_FD09_RFHM 0;
BA_ "GenSigTimeoutTime_ESL" SG_ 2654339137 StayActiveSource_FD09_RFHM 0;
BA_ "GenSigTimeoutTime_ECM" SG_ 2654339137 StayActiveSource_FD09_RFHM 0;
BA_ "GenSigTimeoutTime_DTCM" SG_ 2654339137 StayActiveSource_FD09_RFHM 0;
BA_ "GenSigTimeoutTime_DMSM" SG_ 2654339137 StayActiveSource_FD09_RFHM 0;
BA_ "GenSigTimeoutTime_BSM" SG_ 2654339137 StayActiveSource_FD09_RFHM 0;
BA_ "GenSigTimeoutTime_BCM" SG_ 2654339137 StayActiveSource_FD09_RFHM 0;
BA_ "GenSigTimeoutTime_AGSM" SG_ 2654339137 StayActiveSource_FD09_RFHM 0;
BA_ "GenSigTimeoutTime_ADCAM" SG_ 2654339137 StayActiveSource_FD09_RFHM 0;
BA_ "GenSigTimeoutTime_RFHM" SG_ 2654339137 StayActiveSource_FD03_RFHM 0;
BA_ "GenSigTimeoutTime_MPAD" SG_ 2654339137 StayActiveSource_FD03_RFHM 0;
BA_ "GenSigTimeoutTime_IPC" SG_ 2654339137 StayActiveSource_FD03_RFHM 0;
BA_ "GenSigTimeoutTime_GNMM" SG_ 2654339137 StayActiveSource_FD03_RFHM 0;
BA_ "GenSigTimeoutTime_EVCU2" SG_ 2654339137 StayActiveSource_FD03_RFHM 0;
BA_ "GenSigTimeoutTime_ESL" SG_ 2654339137 StayActiveSource_FD03_RFHM 0;
BA_ "GenSigTimeoutTime_ECM" SG_ 2654339137 StayActiveSource_FD03_RFHM 0;
BA_ "GenSigTimeoutTime_DTCM" SG_ 2654339137 StayActiveSource_FD03_RFHM 0;
BA_ "GenSigTimeoutTime_DMSM" SG_ 2654339137 StayActiveSource_FD03_RFHM 0;
BA_ "GenSigTimeoutTime_BSM" SG_ 2654339137 StayActiveSource_FD03_RFHM 0;
BA_ "GenSigTimeoutTime_BCM" SG_ 2654339137 StayActiveSource_FD03_RFHM 0;
BA_ "GenSigTimeoutTime_AGSM" SG_ 2654339137 StayActiveSource_FD03_RFHM 0;
BA_ "GenSigTimeoutTime_ADCAM" SG_ 2654339137 StayActiveSource_FD03_RFHM 0;
BA_ "GenSigTimeoutTime_RFHM" SG_ 2654339137 PreviousCanNMState_FD09_RFHM 0;
BA_ "GenSigTimeoutTime_MPAD" SG_ 2654339137 PreviousCanNMState_FD09_RFHM 0;
BA_ "GenSigTimeoutTime_IPC" SG_ 2654339137 PreviousCanNMState_FD09_RFHM 0;
BA_ "GenSigTimeoutTime_GNMM" SG_ 2654339137 PreviousCanNMState_FD09_RFHM 0;
BA_ "GenSigTimeoutTime_EVCU2" SG_ 2654339137 PreviousCanNMState_FD09_RFHM 0;
BA_ "GenSigTimeoutTime_ESL" SG_ 2654339137 PreviousCanNMState_FD09_RFHM 0;
BA_ "GenSigTimeoutTime_ECM" SG_ 2654339137 PreviousCanNMState_FD09_RFHM 0;
BA_ "GenSigTimeoutTime_DTCM" SG_ 2654339137 PreviousCanNMState_FD09_RFHM 0;
BA_ "GenSigTimeoutTime_DMSM" SG_ 2654339137 PreviousCanNMState_FD09_RFHM 0;
BA_ "GenSigTimeoutTime_BSM" SG_ 2654339137 PreviousCanNMState_FD09_RFHM 0;
BA_ "GenSigTimeoutTime_BCM" SG_ 2654339137 PreviousCanNMState_FD09_RFHM 0;
BA_ "GenSigTimeoutTime_AGSM" SG_ 2654339137 PreviousCanNMState_FD09_RFHM 0;
BA_ "GenSigTimeoutTime_ADCAM" SG_ 2654339137 PreviousCanNMState_FD09_RFHM 0;
BA_ "GenSigTimeoutTime_RFHM" SG_ 2654339137 GenericFailSts_FD09_RFHM 0;
BA_ "GenSigTimeoutTime_MPAD" SG_ 2654339137 GenericFailSts_FD09_RFHM 0;
BA_ "GenSigTimeoutTime_IPC" SG_ 2654339137 GenericFailSts_FD09_RFHM 0;
BA_ "GenSigTimeoutTime_GNMM" SG_ 2654339137 GenericFailSts_FD09_RFHM 0;
BA_ "GenSigTimeoutTime_EVCU2" SG_ 2654339137 GenericFailSts_FD09_RFHM 0;
BA_ "GenSigTimeoutTime_SGW" SG_ 2654339138 WakeupSource_FD11_DMPI 0;
BA_ "GenSigTimeoutTime_RFHM" SG_ 2654339138 WakeupSource_FD11_DMPI 0;
BA_ "GenSigTimeoutTime_MPAD" SG_ 2654339138 WakeupSource_FD11_DMPI 0;
BA_ "GenSigTimeoutTime_IPC" SG_ 2654339138 WakeupSource_FD11_DMPI 0;
BA_ "GenSigTimeoutTime_GNMM" SG_ 2654339138 WakeupSource_FD11_DMPI 0;
BA_ "GenSigTimeoutTime_EVCU2" SG_ 2654339138 WakeupSource_FD11_DMPI 0;
BA_ "GenSigTimeoutTime_ESL" SG_ 2654339138 WakeupSource_FD11_DMPI 0;
BA_ "GenSigTimeoutTime_ECM" SG_ 2654339138 WakeupSource_FD11_DMPI 0;
BA_ "GenSigTimeoutTime_DTCM" SG_ 2654339138 WakeupSource_FD11_DMPI 0;
BA_ "GenSigTimeoutTime_DMSM" SG_ 2654339138 WakeupSource_FD11_DMPI 0;
BA_ "GenSigTimeoutTime_BSM" SG_ 2654339138 WakeupSource_FD11_DMPI 0;
BA_ "GenSigTimeoutTime_BCM" SG_ 2654339138 WakeupSource_FD11_DMPI 0;
BA_ "GenSigTimeoutTime_AGSM" SG_ 2654339138 WakeupSource_FD11_DMPI 0;
BA_ "GenSigTimeoutTime_ADCAM" SG_ 2654339138 WakeupSource_FD11_DMPI 0;
BA_ "GenSigTimeoutTime_SGW" SG_ 2654339138 WakeupSource_FD05_DMPI 0;
BA_ "GenSigTimeoutTime_RFHM" SG_ 2654339138 WakeupSource_FD05_DMPI 0;
BA_ "GenSigTimeoutTime_MPAD" SG_ 2654339138 WakeupSource_FD05_DMPI 0;
BA_ "GenSigTimeoutTime_IPC" SG_ 2654339138 WakeupSource_FD05_DMPI 0;
BA_ "GenSigTimeoutTime_GNMM" SG_ 2654339138 WakeupSource_FD05_DMPI 0;
BA_ "GenSigTimeoutTime_EVCU2" SG_ 2654339138 WakeupSource_FD05_DMPI 0;
BA_ "GenSigTimeoutTime_ESL" SG_ 2654339138 WakeupSource_FD05_DMPI 0;
BA_ "GenSigTimeoutTime_ECM" SG_ 2654339138 WakeupSource_FD05_DMPI 0;
BA_ "GenSigTimeoutTime_DTCM" SG_ 2654339138 WakeupSource_FD05_DMPI 0;
BA_ "GenSigTimeoutTime_DMSM" SG_ 2654339138 WakeupSource_FD05_DMPI 0;
BA_ "GenSigTimeoutTime_BSM" SG_ 2654339138 WakeupSource_FD05_DMPI 0;
BA_ "GenSigTimeoutTime_BCM" SG_ 2654339138 WakeupSource_FD05_DMPI 0;
BA_ "GenSigTimeoutTime_AGSM" SG_ 2654339138 WakeupSource_FD05_DMPI 0;
BA_ "GenSigTimeoutTime_ADCAM" SG_ 2654339138 WakeupSource_FD05_DMPI 0;
BA_ "GenSigTimeoutTime_SGW" SG_ 2654339138 StayActiveSource_FD11_DMPI 0;
BA_ "GenSigTimeoutTime_RFHM" SG_ 2654339138 StayActiveSource_FD11_DMPI 0;
BA_ "GenSigTimeoutTime_MPAD" SG_ 2654339138 StayActiveSource_FD11_DMPI 0;
BA_ "GenSigTimeoutTime_IPC" SG_ 2654339138 StayActiveSource_FD11_DMPI 0;
BA_ "GenSigTimeoutTime_GNMM" SG_ 2654339138 StayActiveSource_FD11_DMPI 0;
BA_ "GenSigTimeoutTime_EVCU2" SG_ 2654339138 StayActiveSource_FD11_DMPI 0;
BA_ "GenSigTimeoutTime_ESL" SG_ 2654339138 StayActiveSource_FD11_DMPI 0;
BA_ "GenSigTimeoutTime_ECM" SG_ 2654339138 StayActiveSource_FD11_DMPI 0;
BA_ "GenSigTimeoutTime_DTCM" SG_ 2654339138 StayActiveSource_FD11_DMPI 0;
BA_ "GenSigTimeoutTime_DMSM" SG_ 2654339138 StayActiveSource_FD11_DMPI 0;
BA_ "GenSigTimeoutTime_BSM" SG_ 2654339138 StayActiveSource_FD11_DMPI 0;
BA_ "GenSigTimeoutTime_BCM" SG_ 2654339138 StayActiveSource_FD11_DMPI 0;
BA_ "GenSigTimeoutTime_AGSM" SG_ 2654339138 StayActiveSource_FD11_DMPI 0;
BA_ "GenSigTimeoutTime_ADCAM" SG_ 2654339138 StayActiveSource_FD11_DMPI 0;
BA_ "GenSigTimeoutTime_SGW" SG_ 2654339138 StayActiveSource_FD05_DMPI 0;
BA_ "GenSigTimeoutTime_RFHM" SG_ 2654339138 StayActiveSource_FD05_DMPI 0;
BA_ "GenSigTimeoutTime_MPAD" SG_ 2654339138 StayActiveSource_FD05_DMPI 0;
BA_ "GenSigTimeoutTime_IPC" SG_ 2654339138 StayActiveSource_FD05_DMPI 0;
BA_ "GenSigTimeoutTime_GNMM" SG_ 2654339138 StayActiveSource_FD05_DMPI 0;
BA_ "GenSigTimeoutTime_EVCU2" SG_ 2654339138 StayActiveSource_FD05_DMPI 0;
BA_ "GenSigTimeoutTime_ESL" SG_ 2654339138 StayActiveSource_FD05_DMPI 0;
BA_ "GenSigTimeoutTime_ECM" SG_ 2654339138 StayActiveSource_FD05_DMPI 0;
BA_ "GenSigTimeoutTime_DTCM" SG_ 2654339138 StayActiveSource_FD05_DMPI 0;
BA_ "GenSigTimeoutTime_DMSM" SG_ 2654339138 StayActiveSource_FD05_DMPI 0;
BA_ "GenSigTimeoutTime_BSM" SG_ 2654339138 StayActiveSource_FD05_DMPI 0;
BA_ "GenSigTimeoutTime_BCM" SG_ 2654339138 StayActiveSource_FD05_DMPI 0;
BA_ "GenSigTimeoutTime_AGSM" SG_ 2654339138 StayActiveSource_FD05_DMPI 0;
BA_ "GenSigTimeoutTime_ADCAM" SG_ 2654339138 StayActiveSource_FD05_DMPI 0;
BA_ "GenSigTimeoutTime_SGW" SG_ 2654339138 PreviousCanNMState_FD11_DMPI 0;
BA_ "GenSigTimeoutTime_RFHM" SG_ 2654339138 PreviousCanNMState_FD11_DMPI 0;
BA_ "GenSigTimeoutTime_MPAD" SG_ 2654339138 PreviousCanNMState_FD11_DMPI 0;
BA_ "GenSigTimeoutTime_IPC" SG_ 2654339138 PreviousCanNMState_FD11_DMPI 0;
BA_ "GenSigTimeoutTime_GNMM" SG_ 2654339138 PreviousCanNMState_FD11_DMPI 0;
BA_ "GenSigTimeoutTime_EVCU2" SG_ 2654339138 PreviousCanNMState_FD11_DMPI 0;
BA_ "GenSigTimeoutTime_ESL" SG_ 2654339138 PreviousCanNMState_FD11_DMPI 0;
BA_ "GenSigTimeoutTime_ECM" SG_ 2654339138 PreviousCanNMState_FD11_DMPI 0;
BA_ "GenSigTimeoutTime_DTCM" SG_ 2654339138 PreviousCanNMState_FD11_DMPI 0;
BA_ "GenSigTimeoutTime_DMSM" SG_ 2654339138 PreviousCanNMState_FD11_DMPI 0;
BA_ "GenSigTimeoutTime_BSM" SG_ 2654339138 PreviousCanNMState_FD11_DMPI 0;
BA_ "GenSigTimeoutTime_BCM" SG_ 2654339138 PreviousCanNMState_FD11_DMPI 0;
BA_ "GenSigTimeoutTime_AGSM" SG_ 2654339138 PreviousCanNMState_FD11_DMPI 0;
BA_ "GenSigTimeoutTime_ADCAM" SG_ 2654339138 PreviousCanNMState_FD11_DMPI 0;
BA_ "GenSigTimeoutTime_SGW" SG_ 2654339138 PreviousCanNMState_FD05_DMPI 0;
BA_ "GenSigTimeoutTime_RFHM" SG_ 2654339138 PreviousCanNMState_FD05_DMPI 0;
BA_ "GenSigTimeoutTime_MPAD" SG_ 2654339138 PreviousCanNMState_FD05_DMPI 0;
BA_ "GenSigTimeoutTime_IPC" SG_ 2654339138 PreviousCanNMState_FD05_DMPI 0;
BA_ "GenSigTimeoutTime_GNMM" SG_ 2654339138 PreviousCanNMState_FD05_DMPI 0;
BA_ "GenSigTimeoutTime_EVCU2" SG_ 2654339138 PreviousCanNMState_FD05_DMPI 0;
BA_ "GenSigTimeoutTime_ESL" SG_ 2654339138 PreviousCanNMState_FD05_DMPI 0;
BA_ "GenSigTimeoutTime_ECM" SG_ 2654339138 PreviousCanNMState_FD05_DMPI 0;
BA_ "GenSigTimeoutTime_DTCM" SG_ 2654339138 PreviousCanNMState_FD05_DMPI 0;
BA_ "GenSigTimeoutTime_DMSM" SG_ 2654339138 PreviousCanNMState_FD05_DMPI 0;
BA_ "GenSigTimeoutTime_BSM" SG_ 2654339138 PreviousCanNMState_FD05_DMPI 0;
BA_ "GenSigTimeoutTime_BCM" SG_ 2654339138 PreviousCanNMState_FD05_DMPI 0;
BA_ "GenSigTimeoutTime_AGSM" SG_ 2654339138 PreviousCanNMState_FD05_DMPI 0;
BA_ "GenSigTimeoutTime_ADCAM" SG_ 2654339138 PreviousCanNMState_FD05_DMPI 0;
BA_ "GenSigTimeoutTime_SGW" SG_ 2654339138 GenericFailSts_FD11_DMPI 0;
BA_ "GenSigTimeoutTime_RFHM" SG_ 2654339138 GenericFailSts_FD11_DMPI 0;
BA_ "GenSigTimeoutTime_MPAD" SG_ 2654339138 GenericFailSts_FD11_DMPI 0;
BA_ "GenSigTimeoutTime_IPC" SG_ 2654339138 GenericFailSts_FD11_DMPI 0;
BA_ "GenSigTimeoutTime_GNMM" SG_ 2654339138 GenericFailSts_FD11_DMPI 0;
BA_ "GenSigTimeoutTime_EVCU2" SG_ 2654339138 GenericFailSts_FD11_DMPI 0;
BA_ "GenSigTimeoutTime_ESL" SG_ 2654339138 GenericFailSts_FD11_DMPI 0;
BA_ "GenSigTimeoutTime_ECM" SG_ 2654339138 GenericFailSts_FD11_DMPI 0;
BA_ "GenSigTimeoutTime_DTCM" SG_ 2654339138 GenericFailSts_FD11_DMPI 0;
BA_ "GenSigTimeoutTime_DMSM" SG_ 2654339138 GenericFailSts_FD11_DMPI 0;
BA_ "GenSigTimeoutTime_BSM" SG_ 2654339138 GenericFailSts_FD11_DMPI 0;
BA_ "GenSigTimeoutTime_AGSM" SG_ 2654339138 GenericFailSts_FD11_DMPI 0;
BA_ "GenSigTimeoutTime_ADCAM" SG_ 2654339138 GenericFailSts_FD11_DMPI 0;
BA_ "GenSigTimeoutTime_SGW" SG_ 2654339138 GenericFailSts_FD05_DMPI 0;
BA_ "GenSigTimeoutTime_RFHM" SG_ 2654339138 GenericFailSts_FD05_DMPI 0;
BA_ "GenSigTimeoutTime_MPAD" SG_ 2654339138 GenericFailSts_FD05_DMPI 0;
BA_ "GenSigTimeoutTime_IPC" SG_ 2654339138 GenericFailSts_FD05_DMPI 0;
BA_ "GenSigTimeoutTime_GNMM" SG_ 2654339138 GenericFailSts_FD05_DMPI 0;
BA_ "GenSigTimeoutTime_EVCU2" SG_ 2654339138 GenericFailSts_FD05_DMPI 0;
BA_ "GenSigTimeoutTime_ESL" SG_ 2654339138 GenericFailSts_FD05_DMPI 0;
BA_ "GenSigTimeoutTime_ECM" SG_ 2654339138 GenericFailSts_FD05_DMPI 0;
BA_ "GenSigTimeoutTime_DTCM" SG_ 2654339138 GenericFailSts_FD05_DMPI 0;
BA_ "GenSigTimeoutTime_DMSM" SG_ 2654339138 GenericFailSts_FD05_DMPI 0;
BA_ "GenSigTimeoutTime_BSM" SG_ 2654339138 GenericFailSts_FD05_DMPI 0;
BA_ "GenSigTimeoutTime_BCM" SG_ 2654339138 GenericFailSts_FD05_DMPI 0;
BA_ "GenSigTimeoutTime_AGSM" SG_ 2654339138 GenericFailSts_FD05_DMPI 0;
BA_ "GenSigTimeoutTime_ADCAM" SG_ 2654339138 GenericFailSts_FD05_DMPI 0;
BA_ "GenSigTimeoutTime_SGW" SG_ 2654339138 EOL_FD11_DMPI 0;
BA_ "GenSigTimeoutTime_RFHM" SG_ 2654339138 EOL_FD11_DMPI 0;
BA_ "GenSigTimeoutTime_MPAD" SG_ 2654339138 EOL_FD11_DMPI 0;
BA_ "GenSigTimeoutTime_IPC" SG_ 2654339138 EOL_FD11_DMPI 0;
BA_ "GenSigTimeoutTime_GNMM" SG_ 2654339138 EOL_FD11_DMPI 0;
BA_ "GenSigTimeoutTime_EVCU2" SG_ 2654339138 EOL_FD11_DMPI 0;
BA_ "GenSigTimeoutTime_ESL" SG_ 2654339138 EOL_FD11_DMPI 0;
BA_ "GenSigTimeoutTime_ECM" SG_ 2654339138 EOL_FD11_DMPI 0;
BA_ "GenSigTimeoutTime_DTCM" SG_ 2654339138 EOL_FD11_DMPI 0;
BA_ "GenSigTimeoutTime_DMSM" SG_ 2654339138 EOL_FD11_DMPI 0;
BA_ "GenSigTimeoutTime_BSM" SG_ 2654339138 EOL_FD11_DMPI 0;
BA_ "GenSigTimeoutTime_AGSM" SG_ 2654339138 EOL_FD11_DMPI 0;
BA_ "GenSigTimeoutTime_ADCAM" SG_ 2654339138 EOL_FD11_DMPI 0;
BA_ "GenSigTimeoutTime_SGW" SG_ 2654339138 EOL_FD05_DMPI 0;
BA_ "GenSigTimeoutTime_RFHM" SG_ 2654339138 EOL_FD05_DMPI 0;
BA_ "GenSigTimeoutTime_MPAD" SG_ 2654339138 EOL_FD05_DMPI 0;
BA_ "GenSigTimeoutTime_IPC" SG_ 2654339138 EOL_FD05_DMPI 0;
BA_ "GenSigTimeoutTime_GNMM" SG_ 2654339138 EOL_FD05_DMPI 0;
BA_ "GenSigTimeoutTime_EVCU2" SG_ 2654339138 EOL_FD05_DMPI 0;
BA_ "GenSigTimeoutTime_ESL" SG_ 2654339138 EOL_FD05_DMPI 0;
BA_ "GenSigTimeoutTime_ECM" SG_ 2654339138 EOL_FD05_DMPI 0;
BA_ "GenSigTimeoutTime_DTCM" SG_ 2654339138 EOL_FD05_DMPI 0;
BA_ "GenSigTimeoutTime_DMSM" SG_ 2654339138 EOL_FD05_DMPI 0;
BA_ "GenSigTimeoutTime_BSM" SG_ 2654339138 EOL_FD05_DMPI 0;
BA_ "GenSigTimeoutTime_BCM" SG_ 2654339138 EOL_FD05_DMPI 0;
BA_ "GenSigTimeoutTime_AGSM" SG_ 2654339138 EOL_FD05_DMPI 0;
BA_ "GenSigTimeoutTime_ADCAM" SG_ 2654339138 EOL_FD05_DMPI 0;
BA_ "GenSigTimeoutTime_SGW" SG_ 2654339138 DES_FD11_DMPI 0;
BA_ "GenSigTimeoutTime_RFHM" SG_ 2654339138 DES_FD11_DMPI 0;
BA_ "GenSigTimeoutTime_MPAD" SG_ 2654339138 DES_FD11_DMPI 0;
BA_ "GenSigTimeoutTime_IPC" SG_ 2654339138 DES_FD11_DMPI 0;
BA_ "GenSigTimeoutTime_GNMM" SG_ 2654339138 DES_FD11_DMPI 0;
BA_ "GenSigTimeoutTime_EVCU2" SG_ 2654339138 DES_FD11_DMPI 0;
BA_ "GenSigTimeoutTime_ESL" SG_ 2654339138 DES_FD11_DMPI 0;
BA_ "GenSigTimeoutTime_ECM" SG_ 2654339138 DES_FD11_DMPI 0;
BA_ "GenSigTimeoutTime_DTCM" SG_ 2654339138 DES_FD11_DMPI 0;
BA_ "GenSigTimeoutTime_DMSM" SG_ 2654339138 DES_FD11_DMPI 0;
BA_ "GenSigTimeoutTime_BSM" SG_ 2654339138 DES_FD11_DMPI 0;
BA_ "GenSigTimeoutTime_BCM" SG_ 2654339138 DES_FD11_DMPI 0;
BA_ "GenSigTimeoutTime_AGSM" SG_ 2654339138 DES_FD11_DMPI 0;
BA_ "GenSigTimeoutTime_ADCAM" SG_ 2654339138 DES_FD11_DMPI 0;
BA_ "GenSigTimeoutTime_SGW" SG_ 2654339138 DES_FD05_DMPI 0;
BA_ "GenSigTimeoutTime_RFHM" SG_ 2654339138 DES_FD05_DMPI 0;
BA_ "GenSigTimeoutTime_RFHM" SG_ 2654339197 CurrentCanNMState_FD11_IDCM 0;
BA_ "GenSigTimeoutTime_MPAD" SG_ 2654339197 CurrentCanNMState_FD11_IDCM 0;
BA_ "GenSigTimeoutTime_IPC" SG_ 2654339197 CurrentCanNMState_FD11_IDCM 0;
BA_ "GenSigTimeoutTime_GNMM" SG_ 2654339197 CurrentCanNMState_FD11_IDCM 0;
BA_ "GenSigTimeoutTime_EVCU2" SG_ 2654339197 CurrentCanNMState_FD11_IDCM 0;
BA_ "GenSigTimeoutTime_ESL" SG_ 2654339197 CurrentCanNMState_FD11_IDCM 0;
BA_ "GenSigTimeoutTime_ECM" SG_ 2654339197 CurrentCanNMState_FD11_IDCM 0;
BA_ "GenSigTimeoutTime_DTCM" SG_ 2654339197 CurrentCanNMState_FD11_IDCM 0;
BA_ "GenSigTimeoutTime_DMSM" SG_ 2654339197 CurrentCanNMState_FD11_IDCM 0;
BA_ "GenSigTimeoutTime_BSM" SG_ 2654339197 CurrentCanNMState_FD11_IDCM 0;
BA_ "GenSigTimeoutTime_BCM" SG_ 2654339197 CurrentCanNMState_FD11_IDCM 0;
BA_ "GenSigTimeoutTime_AGSM" SG_ 2654339197 CurrentCanNMState_FD11_IDCM 0;
BA_ "GenSigTimeoutTime_ADCAM" SG_ 2654339197 CurrentCanNMState_FD11_IDCM 0;
BA_ "GenSigTimeoutTime_RFHM" SG_ 2654339197 CurrentFailSts_FD05_IDCM 0;
BA_ "GenSigTimeoutTime_MPAD" SG_ 2654339197 CurrentFailSts_FD05_IDCM 0;
BA_ "GenSigTimeoutTime_IPC" SG_ 2654339197 CurrentFailSts_FD05_IDCM 0;
BA_ "GenSigTimeoutTime_GNMM" SG_ 2654339197 CurrentFailSts_FD05_IDCM 0;
BA_ "GenSigTimeoutTime_EVCU2" SG_ 2654339197 CurrentFailSts_FD05_IDCM 0;
BA_ "GenSigTimeoutTime_ESL" SG_ 2654339197 CurrentFailSts_FD05_IDCM 0;
BA_ "GenSigTimeoutTime_ECM" SG_ 2654339197 CurrentFailSts_FD05_IDCM 0;
BA_ "GenSigTimeoutTime_DTCM" SG_ 2654339197 CurrentFailSts_FD05_IDCM 0;
BA_ "GenSigTimeoutTime_DMSM" SG_ 2654339197 CurrentFailSts_FD05_IDCM 0;
BA_ "GenSigTimeoutTime_BSM" SG_ 2654339197 CurrentFailSts_FD05_IDCM 0;
BA_ "GenSigTimeoutTime_AGSM" SG_ 2654339197 CurrentFailSts_FD05_IDCM 0;
BA_ "GenSigTimeoutTime_ADCAM" SG_ 2654339197 CurrentFailSts_FD05_IDCM 0;
BA_ "GenSigTimeoutTime_RFHM" SG_ 2654339197 CurrentCanNMState_FD05_IDCM 0;
BA_ "GenSigTimeoutTime_MPAD" SG_ 2654339197 CurrentCanNMState_FD05_IDCM 0;
BA_ "GenSigTimeoutTime_IPC" SG_ 2654339197 CurrentCanNMState_FD05_IDCM 0;
BA_ "GenSigTimeoutTime_GNMM" SG_ 2654339197 CurrentCanNMState_FD05_IDCM 0;
BA_ "GenSigTimeoutTime_EVCU2" SG_ 2654339197 CurrentCanNMState_FD05_IDCM 0;
BA_ "GenSigTimeoutTime_ESL" SG_ 2654339197 CurrentCanNMState_FD05_IDCM 0;
BA_ "GenSigTimeoutTime_ECM" SG_ 2654339197 CurrentCanNMState_FD05_IDCM 0;
BA_ "GenSigTimeoutTime_DTCM" SG_ 2654339197 CurrentCanNMState_FD05_IDCM 0;
BA_ "GenSigTimeoutTime_DMSM" SG_ 2654339197 CurrentCanNMState_FD05_IDCM 0;
BA_ "GenSigTimeoutTime_BSM" SG_ 2654339197 CurrentCanNMState_FD05_IDCM 0;
BA_ "GenSigTimeoutTime_BCM" SG_ 2654339197 CurrentCanNMState_FD05_IDCM 0;
BA_ "GenSigTimeoutTime_AGSM" SG_ 2654339197 CurrentCanNMState_FD05_IDCM 0;
BA_ "GenSigTimeoutTime_ADCAM" SG_ 2654339197 CurrentCanNMState_FD05_IDCM 0;
BA_ "GenSigTimeoutTime_MPAD" SG_ 2654339138 DES_FD05_DMPI 0;
BA_ "GenSigTimeoutTime_IPC" SG_ 2654339138 DES_FD05_DMPI 0;
BA_ "GenSigTimeoutTime_GNMM" SG_ 2654339138 DES_FD05_DMPI 0;
BA_ "GenSigTimeoutTime_EVCU2" SG_ 2654339138 DES_FD05_DMPI 0;
BA_ "GenSigTimeoutTime_ESL" SG_ 2654339138 DES_FD05_DMPI 0;
BA_ "GenSigTimeoutTime_ECM" SG_ 2654339138 DES_FD05_DMPI 0;
BA_ "GenSigTimeoutTime_DTCM" SG_ 2654339138 DES_FD05_DMPI 0;
BA_ "GenSigTimeoutTime_DMSM" SG_ 2654339138 DES_FD05_DMPI 0;
BA_ "GenSigTimeoutTime_BSM" SG_ 2654339138 DES_FD05_DMPI 0;
BA_ "GenSigTimeoutTime_BCM" SG_ 2654339138 DES_FD05_DMPI 0;
BA_ "GenSigTimeoutTime_AGSM" SG_ 2654339138 DES_FD05_DMPI 0;
BA_ "GenSigTimeoutTime_ADCAM" SG_ 2654339138 DES_FD05_DMPI 0;
BA_ "GenSigTimeoutTime_SGW" SG_ 2654339138 CurrentFailSts_FD11_DMPI 0;
BA_ "GenSigTimeoutTime_RFHM" SG_ 2654339138 CurrentFailSts_FD11_DMPI 0;
BA_ "GenSigTimeoutTime_MPAD" SG_ 2654339138 CurrentFailSts_FD11_DMPI 0;
BA_ "GenSigTimeoutTime_IPC" SG_ 2654339138 CurrentFailSts_FD11_DMPI 0;
BA_ "GenSigTimeoutTime_GNMM" SG_ 2654339138 CurrentFailSts_FD11_DMPI 0;
BA_ "GenSigTimeoutTime_EVCU2" SG_ 2654339138 CurrentFailSts_FD11_DMPI 0;
BA_ "GenSigTimeoutTime_ESL" SG_ 2654339138 CurrentFailSts_FD11_DMPI 0;
BA_ "GenSigTimeoutTime_ECM" SG_ 2654339138 CurrentFailSts_FD11_DMPI 0;
BA_ "GenSigTimeoutTime_DTCM" SG_ 2654339138 CurrentFailSts_FD11_DMPI 0;
BA_ "GenSigTimeoutTime_DMSM" SG_ 2654339138 CurrentFailSts_FD11_DMPI 0;
BA_ "GenSigTimeoutTime_BSM" SG_ 2654339138 CurrentFailSts_FD11_DMPI 0;
BA_ "GenSigTimeoutTime_AGSM" SG_ 2654339138 CurrentFailSts_FD11_DMPI 0;
BA_ "GenSigTimeoutTime_ADCAM" SG_ 2654339138 CurrentFailSts_FD11_DMPI 0;
BA_ "GenSigTimeoutTime_SGW" SG_ 2654339138 CurrentFailSts_FD05_DMPI 0;
BA_ "GenSigTimeoutTime_RFHM" SG_ 2654339138 CurrentFailSts_FD05_DMPI 0;
BA_ "GenSigTimeoutTime_MPAD" SG_ 2654339138 CurrentFailSts_FD05_DMPI 0;
BA_ "GenSigTimeoutTime_IPC" SG_ 2654339138 CurrentFailSts_FD05_DMPI 0;
BA_ "GenSigTimeoutTime_GNMM" SG_ 2654339138 CurrentFailSts_FD05_DMPI 0;
BA_ "GenSigTimeoutTime_EVCU2" SG_ 2654339138 CurrentFailSts_FD05_DMPI 0;
BA_ "GenSigTimeoutTime_ESL" SG_ 2654339138 CurrentFailSts_FD05_DMPI 0;
BA_ "GenSigTimeoutTime_ECM" SG_ 2654339138 CurrentFailSts_FD05_DMPI 0;
BA_ "GenSigTimeoutTime_DTCM" SG_ 2654339138 CurrentFailSts_FD05_DMPI 0;
BA_ "GenSigTimeoutTime_DMSM" SG_ 2654339138 CurrentFailSts_FD05_DMPI 0;
BA_ "GenSigTimeoutTime_BSM" SG_ 2654339138 CurrentFailSts_FD05_DMPI 0;
BA_ "GenSigTimeoutTime_BCM" SG_ 2654339138 CurrentFailSts_FD05_DMPI 0;
BA_ "GenSigTimeoutTime_AGSM" SG_ 2654339138 CurrentFailSts_FD05_DMPI 0;
BA_ "GenSigTimeoutTime_ADCAM" SG_ 2654339138 CurrentFailSts_FD05_DMPI 0;
BA_ "GenSigTimeoutTime_SGW" SG_ 2654339138 CurrentCanNMState_FD11_DMPI 0;
BA_ "GenSigTimeoutTime_RFHM" SG_ 2654339138 CurrentCanNMState_FD11_DMPI 0;
BA_ "GenSigTimeoutTime_MPAD" SG_ 2654339138 CurrentCanNMState_FD11_DMPI 0;
BA_ "GenSigTimeoutTime_IPC" SG_ 2654339138 CurrentCanNMState_FD11_DMPI 0;
BA_ "GenSigTimeoutTime_GNMM" SG_ 2654339138 CurrentCanNMState_FD11_DMPI 0;
BA_ "GenSigTimeoutTime_EVCU2" SG_ 2654339138 CurrentCanNMState_FD11_DMPI 0;
BA_ "GenSigTimeoutTime_ESL" SG_ 2654339138 CurrentCanNMState_FD11_DMPI 0;
BA_ "GenSigTimeoutTime_ECM" SG_ 2654339138 CurrentCanNMState_FD11_DMPI 0;
BA_ "GenSigTimeoutTime_DTCM" SG_ 2654339138 CurrentCanNMState_FD11_DMPI 0;
BA_ "GenSigTimeoutTime_DMSM" SG_ 2654339138 CurrentCanNMState_FD11_DMPI 0;
BA_ "GenSigTimeoutTime_BSM" SG_ 2654339138 CurrentCanNMState_FD11_DMPI 0;
BA_ "GenSigTimeoutTime_BCM" SG_ 2654339138 CurrentCanNMState_FD11_DMPI 0;
BA_ "GenSigTimeoutTime_AGSM" SG_ 2654339138 CurrentCanNMState_FD11_DMPI 0;
BA_ "GenSigTimeoutTime_ADCAM" SG_ 2654339138 CurrentCanNMState_FD11_DMPI 0;
BA_ "GenSigTimeoutTime_SGW" SG_ 2654339138 CurrentCanNMState_FD05_DMPI 0;
BA_ "GenSigTimeoutTime_RFHM" SG_ 2654339138 CurrentCanNMState_FD05_DMPI 0;
BA_ "GenSigTimeoutTime_MPAD" SG_ 2654339138 CurrentCanNMState_FD05_DMPI 0;
BA_ "GenSigTimeoutTime_IPC" SG_ 2654339138 CurrentCanNMState_FD05_DMPI 0;
BA_ "GenSigTimeoutTime_GNMM" SG_ 2654339138 CurrentCanNMState_FD05_DMPI 0;
BA_ "GenSigTimeoutTime_EVCU2" SG_ 2654339138 CurrentCanNMState_FD05_DMPI 0;
BA_ "GenSigTimeoutTime_ESL" SG_ 2654339138 CurrentCanNMState_FD05_DMPI 0;
BA_ "GenSigTimeoutTime_ECM" SG_ 2654339138 CurrentCanNMState_FD05_DMPI 0;
BA_ "GenSigTimeoutTime_DTCM" SG_ 2654339138 CurrentCanNMState_FD05_DMPI 0;
BA_ "GenSigTimeoutTime_DMSM" SG_ 2654339138 CurrentCanNMState_FD05_DMPI 0;
BA_ "GenSigTimeoutTime_BSM" SG_ 2654339138 CurrentCanNMState_FD05_DMPI 0;
BA_ "GenSigTimeoutTime_BCM" SG_ 2654339138 CurrentCanNMState_FD05_DMPI 0;
BA_ "GenSigTimeoutTime_AGSM" SG_ 2654339138 CurrentCanNMState_FD05_DMPI 0;
BA_ "GenSigTimeoutTime_ADCAM" SG_ 2654339138 CurrentCanNMState_FD05_DMPI 0;
BA_ "GenSigTimeoutTime_SGW" SG_ 2651930684 Digit_01_PBWM 0;
BA_ "GenSigTimeoutTime_RFHM" SG_ 2651930684 Digit_01_PBWM 0;
BA_ "GenSigTimeoutTime_MPAD" SG_ 2651930684 Digit_01_PBWM 0;
BA_ "GenSigTimeoutTime_IPC" SG_ 2651930684 Digit_01_PBWM 0;
BA_ "GenSigTimeoutTime_GNMM" SG_ 2651930684 Digit_01_PBWM 0;
BA_ "GenSigTimeoutTime_EVCU2" SG_ 2651930684 Digit_01_PBWM 0;
BA_ "GenSigTimeoutTime_ESL" SG_ 2651930684 Digit_01_PBWM 0;
BA_ "GenSigTimeoutTime_ECM" SG_ 2651930684 Digit_01_PBWM 0;
BA_ "GenSigTimeoutTime_DTCM" SG_ 2651930684 Digit_01_PBWM 0;
BA_ "GenSigTimeoutTime_DMSM" SG_ 2651930684 Digit_01_PBWM 0;
BA_ "GenSigTimeoutTime_BSM" SG_ 2651930684 Digit_01_PBWM 0;
BA_ "GenSigTimeoutTime_AGSM" SG_ 2651930684 Digit_01_PBWM 0;
BA_ "GenSigTimeoutTime_ADCAM" SG_ 2651930684 Digit_01_PBWM 0;
BA_ "GenSigSendType" SG_ 2651930684 Digit_01_PBWM 1;
BA_ "GenSigTimeoutTime_SGW" SG_ 2651930684 Digit_02_PBWM 0;
BA_ "GenSigTimeoutTime_RFHM" SG_ 2651930684 Digit_02_PBWM 0;
BA_ "GenSigTimeoutTime_MPAD" SG_ 2651930684 Digit_02_PBWM 0;
BA_ "GenSigTimeoutTime_IPC" SG_ 2651930684 Digit_02_PBWM 0;
BA_ "GenSigTimeoutTime_GNMM" SG_ 2651930684 Digit_02_PBWM 0;
BA_ "GenSigTimeoutTime_EVCU2" SG_ 2651930684 Digit_02_PBWM 0;
BA_ "GenSigTimeoutTime_ESL" SG_ 2651930684 Digit_02_PBWM 0;
BA_ "GenSigTimeoutTime_ECM" SG_ 2651930684 Digit_02_PBWM 0;
BA_ "GenSigTimeoutTime_DTCM" SG_ 2651930684 Digit_02_PBWM 0;
BA_ "GenSigTimeoutTime_DMSM" SG_ 2651930684 Digit_02_PBWM 0;
BA_ "GenSigTimeoutTime_BSM" SG_ 2651930684 Digit_02_PBWM 0;
BA_ "GenSigTimeoutTime_AGSM" SG_ 2651930684 Digit_02_PBWM 0;
BA_ "GenSigTimeoutTime_ADCAM" SG_ 2651930684 Digit_02_PBWM 0;
BA_ "GenSigTimeoutTime_SGW" SG_ 2651930684 Digit_03_PBWM 0;
BA_ "GenSigTimeoutTime_RFHM" SG_ 2651930684 Digit_03_PBWM 0;
BA_ "GenSigTimeoutTime_MPAD" SG_ 2651930684 Digit_03_PBWM 0;
BA_ "GenSigTimeoutTime_IPC" SG_ 2651930684 Digit_03_PBWM 0;
BA_ "GenSigTimeoutTime_GNMM" SG_ 2651930684 Digit_03_PBWM 0;
BA_ "GenSigTimeoutTime_EVCU2" SG_ 2651930684 Digit_03_PBWM 0;
BA_ "GenSigTimeoutTime_ESL" SG_ 2651930684 Digit_03_PBWM 0;
BA_ "GenSigTimeoutTime_ECM" SG_ 2651930684 Digit_03_PBWM 0;
BA_ "GenSigTimeoutTime_DTCM" SG_ 2651930684 Digit_03_PBWM 0;
BA_ "GenSigTimeoutTime_DMSM" SG_ 2651930684 Digit_03_PBWM 0;
BA_ "GenSigTimeoutTime_BSM" SG_ 2651930684 Digit_03_PBWM 0;
BA_ "GenSigTimeoutTime_AGSM" SG_ 2651930684 Digit_03_PBWM 0;
BA_ "GenSigTimeoutTime_ADCAM" SG_ 2651930684 Digit_03_PBWM 0;
BA_ "GenSigTimeoutTime_SGW" SG_ 2651930684 Digit_04_PBWM 0;
BA_ "GenSigTimeoutTime_RFHM" SG_ 2651930684 Digit_04_PBWM 0;
BA_ "GenSigTimeoutTime_MPAD" SG_ 2651930684 Digit_04_PBWM 0;
BA_ "GenSigTimeoutTime_IPC" SG_ 2651930684 Digit_04_PBWM 0;
BA_ "GenSigTimeoutTime_GNMM" SG_ 2651930684 Digit_04_PBWM 0;
BA_ "GenSigTimeoutTime_EVCU2" SG_ 2651930684 Digit_04_PBWM 0;
BA_ "GenSigTimeoutTime_ESL" SG_ 2651930684 Digit_04_PBWM 0;
BA_ "GenSigTimeoutTime_ECM" SG_ 2651930684 Digit_04_PBWM 0;
BA_ "GenSigTimeoutTime_DTCM" SG_ 2651930684 Digit_04_PBWM 0;
BA_ "GenSigTimeoutTime_DMSM" SG_ 2651930684 Digit_04_PBWM 0;
BA_ "GenSigTimeoutTime_BSM" SG_ 2651930684 Digit_04_PBWM 0;
BA_ "GenSigTimeoutTime_AGSM" SG_ 2651930684 Digit_04_PBWM 0;
BA_ "GenSigTimeoutTime_ADCAM" SG_ 2651930684 Digit_04_PBWM 0;
BA_ "GenSigTimeoutTime_SGW" SG_ 2654486592 CBV_bit7 0;
BA_ "GenSigTimeoutTime_RFHM" SG_ 2654486592 CBV_bit7 0;
BA_ "GenSigTimeoutTime_MPAD" SG_ 2654486592 CBV_bit7 0;
BA_ "GenSigTimeoutTime_IPC" SG_ 2654486592 CBV_bit7 0;
BA_ "GenSigTimeoutTime_GNMM" SG_ 2654486592 CBV_bit7 0;
BA_ "GenSigTimeoutTime_EVCU2" SG_ 2654486592 CBV_bit7 0;
BA_ "GenSigTimeoutTime_ESL" SG_ 2654486592 CBV_bit7 0;
BA_ "GenSigTimeoutTime_ECM" SG_ 2654486592 CBV_bit7 0;
BA_ "GenSigTimeoutTime_DTCM" SG_ 2654486592 CBV_bit7 0;
BA_ "GenSigTimeoutTime_DMSM" SG_ 2654486592 CBV_bit7 0;
BA_ "GenSigTimeoutTime_BSM" SG_ 2654486592 CBV_bit7 0;
BA_ "GenSigTimeoutTime_BCM" SG_ 2654486592 CBV_bit7 0;
BA_ "GenSigTimeoutTime_AGSM" SG_ 2654486592 CBV_bit7 0;
BA_ "GenSigTimeoutTime_ADCAM" SG_ 2654486592 CBV_bit7 0;
BA_ "GenSigTimeoutTime_SGW" SG_ 2654486592 SourceNodeIdentifier 0;
BA_ "GenSigTimeoutTime_RFHM" SG_ 2654486592 SourceNodeIdentifier 0;
BA_ "GenSigTimeoutTime_MPAD" SG_ 2654486592 SourceNodeIdentifier 0;
BA_ "GenSigTimeoutTime_IPC" SG_ 2654486592 SourceNodeIdentifier 0;
BA_ "GenSigTimeoutTime_GNMM" SG_ 2654486592 SourceNodeIdentifier 0;
BA_ "GenSigTimeoutTime_EVCU2" SG_ 2654486592 SourceNodeIdentifier 0;
BA_ "GenSigTimeoutTime_ESL" SG_ 2654486592 SourceNodeIdentifier 0;
BA_ "GenSigTimeoutTime_ECM" SG_ 2654486592 SourceNodeIdentifier 0;
BA_ "GenSigTimeoutTime_DTCM" SG_ 2654486592 SourceNodeIdentifier 0;
BA_ "GenSigTimeoutTime_DMSM" SG_ 2654486592 SourceNodeIdentifier 0;
BA_ "GenSigTimeoutTime_BSM" SG_ 2654486592 SourceNodeIdentifier 0;
BA_ "GenSigTimeoutTime_BCM" SG_ 2654486592 SourceNodeIdentifier 0;
BA_ "GenSigTimeoutTime_AGSM" SG_ 2654486592 SourceNodeIdentifier 0;
BA_ "GenSigTimeoutTime_ADCAM" SG_ 2654486592 SourceNodeIdentifier 0;
BA_ "GenSigTimeoutTime_SGW" SG_ 1585 WiFi_Client_Mode_Confirm 0;
BA_ "GenSigTimeoutTime_RFHM" SG_ 1585 WiFi_Client_Mode_Confirm 0;
BA_ "GenSigTimeoutTime_IPC" SG_ 1585 WiFi_Client_Mode_Confirm 0;
BA_ "GenSigTimeoutTime_GNMM" SG_ 1585 WiFi_Client_Mode_Confirm 0;
BA_ "GenSigTimeoutTime_EVCU2" SG_ 1585 WiFi_Client_Mode_Confirm 0;
BA_ "GenSigTimeoutTime_ESL" SG_ 1585 WiFi_Client_Mode_Confirm 0;
BA_ "GenSigTimeoutTime_ECM" SG_ 1585 WiFi_Client_Mode_Confirm 0;
BA_ "GenSigTimeoutTime_DTCM" SG_ 1585 WiFi_Client_Mode_Confirm 0;
BA_ "GenSigTimeoutTime_DMSM" SG_ 1585 WiFi_Client_Mode_Confirm 0;
BA_ "GenSigTimeoutTime_BSM" SG_ 1585 WiFi_Client_Mode_Confirm 0;
BA_ "GenSigTimeoutTime_BCM" SG_ 1585 WiFi_Client_Mode_Confirm 0;
BA_ "GenSigTimeoutTime_AGSM" SG_ 1585 WiFi_Client_Mode_Confirm 0;
BA_ "GenSigTimeoutTime_ADCAM" SG_ 1585 WiFi_Client_Mode_Confirm 0;
BA_ "GenSigTimeoutTime_SGW" SG_ 1488 TBM_StopCharge 0;
BA_ "GenSigTimeoutTime_RFHM" SG_ 1488 TBM_StopCharge 0;
BA_ "GenSigTimeoutTime_MPAD" SG_ 1488 TBM_StopCharge 0;
BA_ "GenSigTimeoutTime_IPC" SG_ 1488 TBM_StopCharge 0;
BA_ "GenSigTimeoutTime_GNMM" SG_ 1488 TBM_StopCharge 0;
BA_ "GenSigTimeoutTime_ESL" SG_ 1488 TBM_StopCharge 0;
BA_ "GenSigTimeoutTime_ECM" SG_ 1488 TBM_StopCharge 0;
BA_ "GenSigTimeoutTime_DTCM" SG_ 1488 TBM_StopCharge 0;
BA_ "GenSigTimeoutTime_DMSM" SG_ 1488 TBM_StopCharge 0;
BA_ "GenSigTimeoutTime_BSM" SG_ 1488 TBM_StopCharge 0;
BA_ "GenSigTimeoutTime_BCM" SG_ 1488 TBM_StopCharge 0;
BA_ "GenSigTimeoutTime_AGSM" SG_ 1488 TBM_StopCharge 0;
BA_ "GenSigTimeoutTime_ADCAM" SG_ 1488 TBM_StopCharge 0;
BA_ "GenSigTimeoutTime_SGW" SG_ 1488 TBM_Cooperative_Charge_Command 0;
BA_ "GenSigTimeoutTime_RFHM" SG_ 1488 TBM_Cooperative_Charge_Command 0;
BA_ "GenSigTimeoutTime_MPAD" SG_ 1488 TBM_Cooperative_Charge_Command 0;
BA_ "GenSigTimeoutTime_IPC" SG_ 1488 TBM_Cooperative_Charge_Command 0;
BA_ "GenSigTimeoutTime_GNMM" SG_ 1488 TBM_Cooperative_Charge_Command 0;
BA_ "GenSigTimeoutTime_ESL" SG_ 1488 TBM_Cooperative_Charge_Command 0;
BA_ "GenSigTimeoutTime_ECM" SG_ 1488 TBM_Cooperative_Charge_Command 0;
BA_ "GenSigTimeoutTime_DTCM" SG_ 1488 TBM_Cooperative_Charge_Command 0;
BA_ "GenSigTimeoutTime_DMSM" SG_ 1488 TBM_Cooperative_Charge_Command 0;
BA_ "GenSigTimeoutTime_BSM" SG_ 1488 TBM_Cooperative_Charge_Command 0;
BA_ "GenSigTimeoutTime_BCM" SG_ 1488 TBM_Cooperative_Charge_Command 0;
BA_ "GenSigTimeoutTime_AGSM" SG_ 1488 TBM_Cooperative_Charge_Command 0;
BA_ "GenSigTimeoutTime_ADCAM" SG_ 1488 TBM_Cooperative_Charge_Command 0;
BA_ "GenSigTimeoutTime_SGW" SG_ 1488 Remote_Chargeport_Command 0;
BA_ "GenSigTimeoutTime_RFHM" SG_ 1488 Remote_Chargeport_Command 0;
BA_ "GenSigTimeoutTime_MPAD" SG_ 1488 Remote_Chargeport_Command 0;
BA_ "GenSigTimeoutTime_IPC" SG_ 1488 Remote_Chargeport_Command 0;
BA_ "GenSigTimeoutTime_GNMM" SG_ 1488 Remote_Chargeport_Command 0;
BA_ "GenSigTimeoutTime_ESL" SG_ 1488 Remote_Chargeport_Command 0;
BA_ "GenSigTimeoutTime_ECM" SG_ 1488 Remote_Chargeport_Command 0;
BA_ "GenSigTimeoutTime_DTCM" SG_ 1488 Remote_Chargeport_Command 0;
BA_ "GenSigTimeoutTime_DMSM" SG_ 1488 Remote_Chargeport_Command 0;
BA_ "GenSigTimeoutTime_BSM" SG_ 1488 Remote_Chargeport_Command 0;
BA_ "GenSigTimeoutTime_BCM" SG_ 1488 Remote_Chargeport_Command 0;
BA_ "GenSigTimeoutTime_AGSM" SG_ 1488 Remote_Chargeport_Command 0;
BA_ "GenSigTimeoutTime_ADCAM" SG_ 1488 Remote_Chargeport_Command 0;
BA_ "GenSigTimeoutTime_SGW" SG_ 1488 Cooperative_Vehicle_Location 0;
BA_ "GenSigTimeoutTime_RFHM" SG_ 1488 Cooperative_Vehicle_Location 0;
BA_ "GenSigTimeoutTime_MPAD" SG_ 1488 Cooperative_Vehicle_Location 0;
BA_ "GenSigTimeoutTime_IPC" SG_ 1488 Cooperative_Vehicle_Location 0;
BA_ "GenSigTimeoutTime_GNMM" SG_ 1488 Cooperative_Vehicle_Location 0;
BA_ "GenSigTimeoutTime_ESL" SG_ 1488 Cooperative_Vehicle_Location 0;
BA_ "GenSigTimeoutTime_ECM" SG_ 1488 Cooperative_Vehicle_Location 0;
BA_ "GenSigTimeoutTime_DTCM" SG_ 1488 Cooperative_Vehicle_Location 0;
BA_ "GenSigTimeoutTime_DMSM" SG_ 1488 Cooperative_Vehicle_Location 0;
BA_ "GenSigTimeoutTime_BSM" SG_ 1488 Cooperative_Vehicle_Location 0;
BA_ "GenSigTimeoutTime_BCM" SG_ 1488 Cooperative_Vehicle_Location 0;
BA_ "GenSigTimeoutTime_AGSM" SG_ 1488 Cooperative_Vehicle_Location 0;
BA_ "GenSigTimeoutTime_ADCAM" SG_ 1488 Cooperative_Vehicle_Location 0;
BA_ "GenSigTimeoutTime_SGW" SG_ 577 QualifyDriveCycle 0;
BA_ "GenSigTimeoutTime_RFHM" SG_ 577 QualifyDriveCycle 0;
BA_ "GenSigTimeoutTime_MPAD" SG_ 577 QualifyDriveCycle 0;
BA_ "GenSigTimeoutTime_IPC" SG_ 577 QualifyDriveCycle 0;
BA_ "GenSigTimeoutTime_GNMM" SG_ 577 QualifyDriveCycle 0;
BA_ "GenSigTimeoutTime_ESL" SG_ 577 QualifyDriveCycle 0;
BA_ "GenSigTimeoutTime_ECM" SG_ 577 QualifyDriveCycle 0;
BA_ "GenSigTimeoutTime_DTCM" SG_ 577 QualifyDriveCycle 0;
BA_ "GenSigTimeoutTime_DMSM" SG_ 577 QualifyDriveCycle 0;
BA_ "GenSigTimeoutTime_BSM" SG_ 577 QualifyDriveCycle 0;
BA_ "GenSigTimeoutTime_BCM" SG_ 577 QualifyDriveCycle 0;
BA_ "GenSigTimeoutTime_AGSM" SG_ 577 QualifyDriveCycle 0;
BA_ "GenSigTimeoutTime_ADCAM" SG_ 577 QualifyDriveCycle 0;
BA_ "GenSigSendType" SG_ 577 QualifyDriveCycle 3;
VAL_ 2654339137 GenericFailSts_FD03_RFHM 0 "No_Fail_Present" 1 "Fail_Present";
VAL_ 2654339137 EOL_FD03_RFHM 0 "No_EOL_Programming" 1 "EOL_Programming";
VAL_ 2654339137 CurrentFailSts_FD03_RFHM 0 "No_Fail_Present" 1 "Fail_Present";
VAL_ 2654339197 EOL_FD11_IDCM 0 "No_EOL_Programming" 1 "EOL_Programming";
VAL_ 2654339137 WakeupSource_FD03_RFHM 0 "No_Wakeup" 1 "Diagnostic" 2 "Network_FD3" 3 "Start_Stop_Ignition_Button" 4 "Left_Front_Door_Handle_Input" 5 "Right_Front_Door_Handle_Input" 6 "Left_Rear_Door_Handle_Input" 7 "Right_Rear_Door_Handle_Input" 8 "Trunk_Liftgate_Input" 9 "RF_Input" 10 "Reset" 11 "Cap_Sens_24Hr_Reset_Timer_Expire" 12 "Clutch_Input" 13 "Network_FD9" 14 "Proximity" 15 "None" 16 "Ignition_RUN_START" 17 "RKE_Lock" 18 "RKE_Unlock" 19 "RKE_Trunk" 20 "RKE_Panic" 21 "RKE_AS" 22 "RKE_RS" 23 "Fob_Search_Request_BCM" 24 "Liftgate_Lock" 25 "KIN_Press" 26 "Warning_Reserved" 27 "Proximity_Wakeup" 28 "NM_From_Other_ECU_CANFD3" 29 "CANFD9" 30 "PE_FL_Lock" 31 "PE_FL_Unlock" 32 "PE_FL_Pull" 33 "PE_FR_Lock" 34 "PE_FR_Unlock" 35 "PE_FR_Pull" 36 "PE_RL_Lock" 37 "PE_RL_Unlock" 38 "PE_RL_Pull" 39 "PE_RR_Lock" 40 "PE_RR_Unlock" 41 "PE_RR_Pull" 129 "FD1_Psv_WU" 130 "FD2_Psv_WU" 131 "FD3_Psv_WU" 132 "FD4_Psv_WU" 133 "FD5_Psv_WU" 134 "FD6_Psv_WU" 135 "FD7_Psv_WU" 136 "FD8_Psv_WU" 137 "FD9_Psv_WU" 138 "FD10_Psv_WU" 139 "FD11_Psv_WU" 140 "FD12_Psv_WU" 141 "FD13_Psv_WU" 142 "FD14_Psv_WU" 143 "FD15_Psv_WU" 144 "FD16_Psv_WU" 145 "FD17_Psv_WU" 146 "FD18_Psv_WU" 147 "FD19_Psv_WU" 148 "FD20_Psv_WU" 149 "FD21_Psv_WU" 150 "FD22_Psv_WU" 151 "FD23_Psv_WU" 152 "FD24_Psv_WU" 153 "FD25_Psv_WU" 154 "FD26_Psv_WU" 155 "FD27_Psv_WU" 156 "FD28_Psv_WU" 157 "FD29_Psv_WU" 158 "BHCAN_Psv_WU" 159 "CCAN_Psv_WU" 254 "WUSource_Not_Listed" 255 "SNA";
VAL_ 2654339137 PreviousCanNMState_FD03_RFHM 0 "Uninitialized State" 1 "Bus-Sleep State" 2 "Prepare-Bus State" 3 "Ready-Sleep State" 4 "Normal Operation State" 5 "Repeat Message State" 6 "Synchronize State" 7 "Offline State";
VAL_ 2654339137 DES_FD03_RFHM 0 "Error_Active_state" 1 "Error_passive_warning_state" 2 "Bus_off_state" 3 "Not_used";
VAL_ 2654339137 CurrentCanNMState_FD03_RFHM 0 "Uninitialized State" 1 "Bus-Sleep State" 2 "Prepare-Bus State" 3 "Ready-Sleep State" 4 "Normal Operation State" 5 "Repeat Message State" 6 "Synchronize State" 7 "Offline State";
VAL_ 2654486592 CBV_bit4_ActiveWakeupBit 0 "PassiveWakeup" 1 "ActiveWakeup";
VAL_ 2654339132 WakeupSource_FD11_PBWM 0 "No_Wakeup";
VAL_ 2654339132 WakeupSource_FD05_PBWM 0 "No_Wakeup";
VAL_ 2654339132 StayActiveSource_FD11_PBWM 0 "CANNM_Ready_Sleep" 1 "IGN_ON" 2 "NonDefault_Diag" 4 "ING_OFF_NormSt_RptSt" 8 "HV_ON" 1073741824 "SASource_Not_Listed";
VAL_ 2654339132 PreviousCanNMState_FD11_PBWM 0 "Uninitialized State" 1 "Bus-Sleep State" 2 "Prepare-Bus State" 3 "Ready-Sleep State" 4 "Normal Operation State" 5 "Repeat Message State" 6 "Synchronize State" 7 "Offline State";
VAL_ 2654339132 PreviousCanNMState_FD05_PBWM 0 "Uninitialized State" 1 "Bus-Sleep State" 2 "Prepare-Bus State" 3 "Ready-Sleep State" 4 "Normal Operation State" 5 "Repeat Message State" 6 "Synchronize State" 7 "Offline State";
VAL_ 2654339132 GenericFailSts_FD11_PBWM 0 "No_Fail_Present" 1 "Fail_Present";
VAL_ 2654339132 GenericFailSts_FD05_PBWM 0 "No_Fail_Present" 1 "Fail_Present";
VAL_ 2654339132 EOL_FD11_PBWM 0 "No_EOL_Programming" 1 "EOL_Programming";
VAL_ 2654339132 EOL_FD05_PBWM 0 "No_EOL_Programming" 1 "EOL_Programming";
VAL_ 2654339132 DES_FD11_PBWM 0 "Error_Active_state" 1 "Error_passive_warning_state" 2 "Bus_off_state" 3 "Not_used";
VAL_ 2654339132 DES_FD05_PBWM 0 "Error_Active_state" 1 "Error_passive_warning_state" 2 "Bus_off_state" 3 "Not_used";
VAL_ 2654339132 CurrentFailSts_FD11_PBWM 0 "No_Fail_Present" 1 "Fail_Present";
VAL_ 2654339132 CurrentFailSts_FD05_PBWM 0 "No_Fail_Present" 1 "Fail_Present";
VAL_ 2654339132 CurrentCanNMState_FD11_PBWM 0 "Uninitialized State" 1 "Bus-Sleep State" 2 "Prepare-Bus State" 3 "Ready-Sleep State" 4 "Normal Operation State" 5 "Repeat Message State" 6 "Synchronize State" 7 "Offline State";
VAL_ 2654339132 CurrentCanNMState_FD05_PBWM 0 "Uninitialized State" 1 "Bus-Sleep State" 2 "Prepare-Bus State" 3 "Ready-Sleep State" 4 "Normal Operation State" 5 "Repeat Message State" 6 "Synchronize State" 7 "Offline State";
VAL_ 2654339138 WakeupSource_FD11_DMPI 0 "No_Wakeup";
VAL_ 2654339138 WakeupSource_FD05_DMPI 0 "No_Wakeup";
VAL_ 2654339138 StayActiveSource_FD11_DMPI 0 "CANNM_Ready_Sleep" 1 "IGN_ON" 2 "NonDefault_Diag" 4 "ING_OFF_NormSt_RptSt" 8 "HV_ON" 1073741824 "SASource_Not_Listed";
VAL_ 2654339138 PreviousCanNMState_FD11_DMPI 0 "Uninitialized State" 1 "Bus-Sleep State" 2 "Prepare-Bus State" 3 "Ready-Sleep State" 4 "Normal Operation State" 5 "Repeat Message State" 6 "Synchronize State" 7 "Offline State";
VAL_ 2654339138 PreviousCanNMState_FD05_DMPI 0 "Uninitialized State" 1 "Bus-Sleep State" 2 "Prepare-Bus State" 3 "Ready-Sleep State" 4 "Normal Operation State" 5 "Repeat Message State" 6 "Synchronize State" 7 "Offline State";
VAL_ 2654339138 GenericFailSts_FD11_DMPI 0 "No_Fail_Present" 1 "Fail_Present";
VAL_ 2654339138 GenericFailSts_FD05_DMPI 0 "No_Fail_Present" 1 "Fail_Present";
VAL_ 2654339138 EOL_FD11_DMPI 0 "No_EOL_Programming" 1 "EOL_Programming";
VAL_ 2654339138 EOL_FD05_DMPI 0 "No_EOL_Programming" 1 "EOL_Programming";
VAL_ 2654339138 DES_FD11_DMPI 0 "Error_Active_state" 1 "Error_passive_warning_state" 2 "Bus_off_state" 3 "Not_used";
VAL_ 2654339138 DES_FD05_DMPI 0 "Error_Active_state" 1 "Error_passive_warning_state" 2 "Bus_off_state" 3 "Not_used";
VAL_ 2654339138 CurrentFailSts_FD11_DMPI 0 "No_Fail_Present" 1 "Fail_Present";
VAL_ 2654339138 CurrentFailSts_FD05_DMPI 0 "No_Fail_Present" 1 "Fail_Present";
VAL_ 2654339138 CurrentCanNMState_FD11_DMPI 0 "Uninitialized State" 1 "Bus-Sleep State" 2 "Prepare-Bus State" 3 "Ready-Sleep State" 4 "Normal Operation State" 5 "Repeat Message State" 6 "Synchronize State" 7 "Offline State";
VAL_ 2654339138 CurrentCanNMState_FD05_DMPI 0 "Uninitialized State" 1 "Bus-Sleep State" 2 "Prepare-Bus State" 3 "Ready-Sleep State" 4 "Normal Operation State" 5 "Repeat Message State" 6 "Synchronize State" 7 "Offline State";
VAL_ 1914 Download_Status_MPFC 0 "Not Downloading" 1 "Download in Progress" 2 "Download Completed" 3 "Fault Download Failed";
VAL_ 1914 Big_ECU_Ready_MPFC 0 "Not Ready" 1 "Ready for Transfer" 2 "ECU ID not Downloaded" 3 "Ready for Install";
VAL_ 577 QualifyDriveCycle 0 "Not_Realized" 1 "Realized";
VAL_ 1044 TransTemp_Display 63 "SNA";
VAL_ 1044 HVBatteryMILRq 0 "FALSE" 1 "TRUE";
VAL_ 1044 APCM_Rq_Display 0 "OFF" 1 "ON" 2 "PENDING" 3 "SNA";
VAL_ 1914 Update_Status_MPFC 0 "Not_Updating" 1 "Update_in_progress" 2 "Update_Completed" 3 "Fault_Update_Failed";
VAL_ 2654339197 WakeupSource_FD11_IDCM 0 "No_Wakeup";
VAL_ 2654339197 PreviousCanNMState_FD11_IDCM 0 "Uninitialized State" 1 "Bus-Sleep State" 2 "Prepare-Bus State" 3 "Ready-Sleep State" 4 "Normal Operation State" 5 "Repeat Message State" 6 "Synchronize State" 7 "Offline State";
VAL_ 2654339197 GenericFailSts_FD11_IDCM 0 "No_Fail_Present" 1 "Fail_Present";
VAL_ 2654339197 DES_FD11_IDCM 0 "Error_Active_state" 1 "Error_passive_warning_state" 2 "Bus_off_state" 3 "Not_used";
VAL_ 2654339197 CurrentFailSts_FD11_IDCM 0 "No_Fail_Present" 1 "Fail_Present";
VAL_ 2654339197 CurrentCanNMState_FD11_IDCM 0 "Uninitialized State" 1 "Bus-Sleep State" 2 "Prepare-Bus State" 3 "Ready-Sleep State" 4 "Normal Operation State" 5 "Repeat Message State" 6 "Synchronize State" 7 "Offline State";
VAL_ 1585 WiFi_Client_Mode_Confirm 0 "Off" 1 "On" 3 "SNA";
VAL_ 2654339197 WakeupSource_FD05_IDCM 0 "No_Wakeup";
VAL_ 2654339197 PreviousCanNMState_FD05_IDCM 0 "Uninitialized State" 1 "Bus-Sleep State" 2 "Prepare-Bus State" 3 "Ready-Sleep State" 4 "Normal Operation State" 5 "Repeat Message State" 6 "Synchronize State" 7 "Offline State";
VAL_ 2654339197 GenericFailSts_FD05_IDCM 0 "No_Fail_Present" 1 "Fail_Present";
VAL_ 2654339197 EOL_FD05_IDCM 0 "No_EOL_Programming" 1 "EOL_Programming";
VAL_ 2654339197 DES_FD05_IDCM 0 "Error_Active_state" 1 "Error_passive_warning_state" 2 "Bus_off_state" 3 "Not_used";
VAL_ 2654339197 CurrentFailSts_FD05_IDCM 0 "No_Fail_Present" 1 "Fail_Present";
VAL_ 2654339197 CurrentCanNMState_FD05_IDCM 0 "Uninitialized State" 1 "Bus-Sleep State" 2 "Prepare-Bus State" 3 "Ready-Sleep State" 4 "Normal Operation State" 5 "Repeat Message State" 6 "Synchronize State" 7 "Offline State";
VAL_ 2654339137 WakeupSource_FD09_RFHM 0 "No_Wakeup" 1 "Diagnostic" 2 "Network_FD3" 3 "Start_Stop_Ignition_Button" 4 "Left_Front_Door_Handle_Input" 5 "Right_Front_Door_Handle_Input" 6 "Left_Rear_Door_Handle_Input" 7 "Right_Rear_Door_Handle_Input" 8 "Trunk_Liftgate_Input" 9 "RF_Input" 10 "Reset" 11 "Cap_Sens_24Hr_Reset_Timer_Expire" 12 "Clutch_Input" 13 "Network_FD9" 14 "Proximity" 15 "SNA" 129 "FD1_Psv_WU" 130 "FD2_Psv_WU" 131 "FD3_Psv_WU" 132 "FD4_Psv_WU" 133 "FD5_Psv_WU" 134 "FD6_Psv_WU" 135 "FD7_Psv_WU" 136 "FD8_Psv_WU" 137 "FD9_Psv_WU" 138 "FD10_Psv_WU" 139 "FD11_Psv_WU" 140 "FD12_Psv_WU" 141 "FD13_Psv_WU" 142 "FD14_Psv_WU" 143 "FD15_Psv_WU" 144 "FD16_Psv_WU" 145 "FD17_Psv_WU" 146 "FD18_Psv_WU" 147 "FD19_Psv_WU" 148 "FD20_Psv_WU" 149 "FD21_Psv_WU" 150 "FD22_Psv_WU" 151 "FD23_Psv_WU" 152 "FD24_Psv_WU" 153 "FD25_Psv_WU" 154 "FD26_Psv_WU" 155 "FD27_Psv_WU" 156 "FD28_Psv_WU" 157 "FD29_Psv_WU" 158 "BHCAN_Psv_WU" 159 "CCAN_Psv_WU" 254 "WUSource_Not_Listed";
VAL_ 2654339137 PreviousCanNMState_FD09_RFHM 0 "Uninitialized State" 1 "Bus-Sleep State" 2 "Prepare-Bus State" 3 "Ready-Sleep State" 4 "Normal Operation State" 5 "Repeat Message State" 6 "Synchronize State" 7 "Offline State";
VAL_ 2654339137 GenericFailSts_FD09_RFHM 0 "No_Fail_Present" 1 "Fail_Present";
VAL_ 2654339137 EOL_FD09_RFHM 0 "No_EOL_Programming" 1 "EOL_Programming";
VAL_ 2654339137 DES_FD09_RFHM 0 "Error_Active_state" 1 "Error_passive_warning_state" 2 "Bus_off_state" 3 "Not_used";
VAL_ 2654339137 CurrentFailSts_FD09_RFHM 0 "No_Fail_Present" 1 "Fail_Present";
VAL_ 2654339137 CurrentCanNMState_FD09_RFHM 0 "Uninitialized State" 1 "Bus-Sleep State" 2 "Prepare-Bus State" 3 "Ready-Sleep State" 4 "Normal Operation State" 5 "Repeat Message State" 6 "Synchronize State" 7 "Offline State";
VAL_ 2654339137 StayActiveSource_FD09_RFHM 0 "CANNM_Ready_Sleep" 1 "IGN_ON" 2 "NonDefault_Diag" 4 "ING_OFF_NormSt_RptSt" 1073741824 "SASource_Not_Listed";
VAL_ 2654339137 StayActiveSource_FD03_RFHM 0 "CANNM_Ready_Sleep" 1 "IGN_ON" 2 "NonDefault_Diag" 4 "ING_OFF_NormSt_RptSt" 15 "None" 16 "Ignition_RUN_START" 17 "RKE_Lock" 18 "RKE_Unlock" 19 "RKE_Trunk" 20 "RKE_Panic" 21 "RKE_AS" 22 "RKE_RS" 23 "Fob_Search_Request_BCM" 24 "Liftgate_Lock" 25 "KIN_Press" 26 "Warning_Reserved" 27 "Proximity_Wakeup" 28 "NM_From_Other_ECU_CANFD3" 29 "CANFD9" 30 "PE_FL_Lock" 31 "PE_FL_Unlock" 32 "PE_FL_Pull" 33 "PE_FR_Lock" 34 "PE_FR_Unlock" 35 "PE_FR_Pull" 36 "PE_RL_Lock" 37 "PE_RL_Unlock" 38 "PE_RL_Pull" 39 "PE_RR_Lock" 40 "PE_RR_Unlock" 41 "PE_RR_Pull" 1073741824 "SASource_Not_Listed";
VAL_ 1044 RI_TOTAL_Range_Add 2047 "SNA";
VAL_ 1044 RI_SEATSWHL_Range 511 "SNA";
VAL_ 1044 RI_LIGHTS_Range 511 "SNA";
VAL_ 1044 RI_DEFROST_Range 511 "SNA";
VAL_ 1044 RI_AUDIO_Range 1023 "SNA";
VAL_ 1044 RI_AC_FAN_Range 1023 "SNA";
VAL_ 616 Set_Speed_MPH_VIP 255 "SNA";
VAL_ 616 Set_Speed_KPH_VIP 255 "SNA";
VAL_ 616 RRCC_LEDSts_VIP 0 "OFF" 1 "Cont" 2 "Blink" 3 "SNA";
VAL_ 1488 TBM_StopCharge 0 "No_Charge" 1 "Stop_Charge";
VAL_ 1488 TBM_Cooperative_Charge_Command 0 "Default" 1 "Charge_Now" 2 "Stop_Charge" 3 "SNA";
VAL_ 1488 Remote_Chargeport_Command 0 "Default" 1 "Lock_Request" 2 "Unlock_Request" 3 "SNA";
VAL_ 1488 Cooperative_Vehicle_Location 0 "Absent" 1 "Present";
VAL_ 1044 PnC_Reattepmt_Failure 0 "No_Failure" 1 "Failure";
VAL_ 1044 PnC_Failure 0 "No_Failure" 1 "Failure";
VAL_ 1487 Total_Battery_Capacity 4095 "SNA";
VAL_ 1487 Lv2_EstChargeTime_80 8191 "SNA";
VAL_ 1487 Lv1_EstChargeTime_80 8191 "SNA";
VAL_ 1487 EVSE_Power 511 "SNA";
VAL_ 1487 EV_Charge_Current 2047 "SNA";
VAL_ 1487 Est_Range_FullCharge 2047 "SNA";
VAL_ 1487 Energy_to_Battery 511 "SNA";
VAL_ 1487 Cooperative_Status 0 "Default" 1 "Regular_Charging" 2 "External_Charging" 3 "ChargeNow_Override" 4 "Other_reason";
VAL_ 1487 Chargeport_Lock_Status 0 "Default" 1 "Locked" 2 "Unlocked" 3 "reserved";
